VERSION "HINBNNNYYNNNYYNNNNNNNNNNNNYNNNYYYNNYNNNNNN/4//%%/4/'%**4NNN///"

NS_ :

BS_:

BU_: VirtualNMTMaster BMS_5_1 BMS_4_1 BMS_3_1 BMS_2_1 BMS_1_1 BMS_0_1 BMS_5_0 BMS_4_0 BMS_3_0 BMS_2_0 BMS_1_0 BMS_0_0 PVC IMU TMS TMU MC

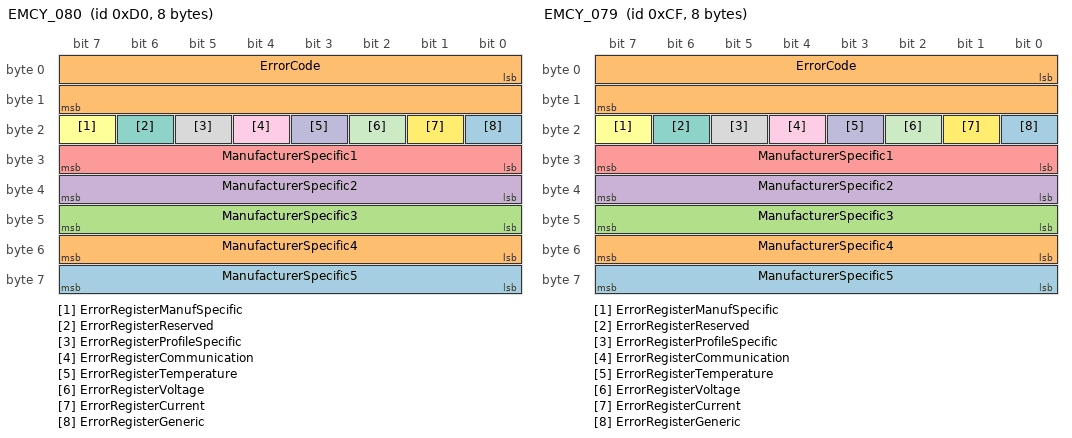
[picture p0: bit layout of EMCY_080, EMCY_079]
BO_ 208 EMCY_080: 8 Vector__XXX
 SG_ ManufacturerSpecific5 : 56|8@1+ (1,0) [0|0] "" Vector__XXX
 SG_ ManufacturerSpecific4 : 48|8@1+ (1,0) [0|0] "" Vector__XXX
 SG_ ManufacturerSpecific3 : 40|8@1+ (1,0) [0|0] "" Vector__XXX
 SG_ ManufacturerSpecific2 : 32|8@1+ (1,0) [0|0] "" Vector__XXX
 SG_ ManufacturerSpecific1 : 24|8@1+ (1,0) [0|0] "" Vector__XXX
 SG_ ErrorRegisterManufSpecific : 23|1@1+ (1,0) [0|0] "" Vector__XXX
 SG_ ErrorRegisterReserved : 22|1@1+ (1,0) [0|0] "" Vector__XXX
 SG_ ErrorRegisterProfileSpecific : 21|1@1+ (1,0) [0|0] "" Vector__XXX
 SG_ ErrorRegisterCommunication : 20|1@1+ (1,0) [0|0] "" Vector__XXX
 SG_ ErrorRegisterTemperature : 19|1@1+ (1,0) [0|0] "" Vector__XXX
 SG_ ErrorRegisterVoltage : 18|1@1+ (1,0) [0|0] "" Vector__XXX
 SG_ ErrorRegisterCurrent : 17|1@1+ (1,0) [0|0] "" Vector__XXX
 SG_ ErrorRegisterGeneric : 16|1@1+ (1,0) [0|0] "" Vector__XXX
 SG_ ErrorCode : 0|16@1+ (1,0) [0|0] "" Vector__XXX

BO_ 1871 HBGuard_079: 1 Vector__XXX
 SG_ Toggle : 7|1@1+ (1,0) [0|0] "" Vector__XXX
 SG_ State : 0|7@1+ (1,0) [0|0] "" Vector__XXX

BO_ 1487 SSDO_079: 8 Vector__XXX

BO_ 1615 CSDO_079: 8 Vector__XXX

BO_ 207 EMCY_079: 8 Vector__XXX
 SG_ ManufacturerSpecific5 : 56|8@1+ (1,0) [0|0] "" Vector__XXX
 SG_ ManufacturerSpecific4 : 48|8@1+ (1,0) [0|0] "" Vector__XXX
 SG_ ManufacturerSpecific3 : 40|8@1+ (1,0) [0|0] "" Vector__XXX
 SG_ ManufacturerSpecific2 : 32|8@1+ (1,0) [0|0] "" Vector__XXX
 SG_ ManufacturerSpecific1 : 24|8@1+ (1,0) [0|0] "" Vector__XXX
 SG_ ErrorRegisterManufSpecific : 23|1@1+ (1,0) [0|0] "" Vector__XXX
 SG_ ErrorRegisterReserved : 22|1@1+ (1,0) [0|0] "" Vector__XXX
 SG_ ErrorRegisterProfileSpecific : 21|1@1+ (1,0) [0|0] "" Vector__XXX
 SG_ ErrorRegisterCommunication : 20|1@1+ (1,0) [0|0] "" Vector__XXX
 SG_ ErrorRegisterTemperature : 19|1@1+ (1,0) [0|0] "" Vector__XXX
 SG_ ErrorRegisterVoltage : 18|1@1+ (1,0) [0|0] "" Vector__XXX
 SG_ ErrorRegisterCurrent : 17|1@1+ (1,0) [0|0] "" Vector__XXX
 SG_ ErrorRegisterGeneric : 16|1@1+ (1,0) [0|0] "" Vector__XXX
 SG_ ErrorCode : 0|16@1+ (1,0) [0|0] "" Vector__XXX

BO_ 1870 HBGuard_078: 1 Vector__XXX
 SG_ Toggle : 7|1@1+ (1,0) [0|0] "" Vector__XXX
 SG_ State : 0|7@1+ (1,0) [0|0] "" Vector__XXX

BO_ 1486 SSDO_078: 8 Vector__XXX

BO_ 1614 CSDO_078: 8 Vector__XXX

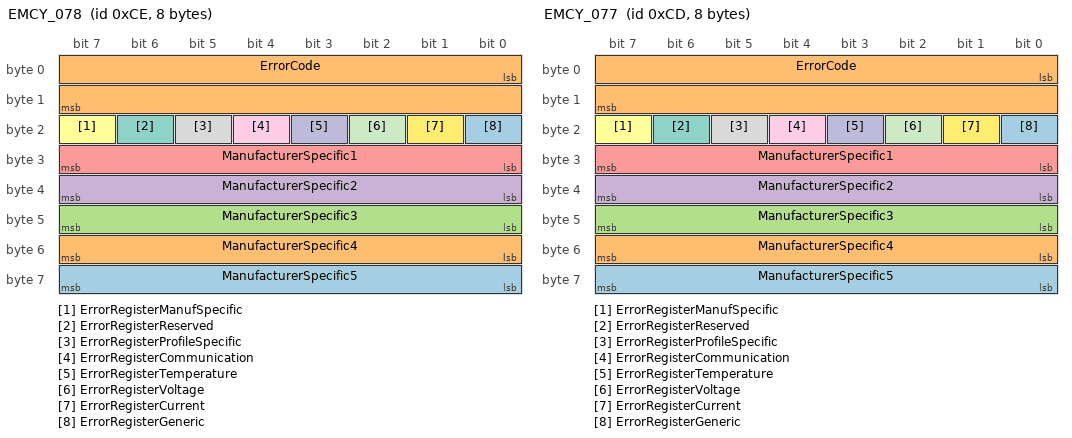
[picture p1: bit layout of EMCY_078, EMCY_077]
BO_ 206 EMCY_078: 8 Vector__XXX
 SG_ ManufacturerSpecific5 : 56|8@1+ (1,0) [0|0] "" Vector__XXX
 SG_ ManufacturerSpecific4 : 48|8@1+ (1,0) [0|0] "" Vector__XXX
 SG_ ManufacturerSpecific3 : 40|8@1+ (1,0) [0|0] "" Vector__XXX
 SG_ ManufacturerSpecific2 : 32|8@1+ (1,0) [0|0] "" Vector__XXX
 SG_ ManufacturerSpecific1 : 24|8@1+ (1,0) [0|0] "" Vector__XXX
 SG_ ErrorRegisterManufSpecific : 23|1@1+ (1,0) [0|0] "" Vector__XXX
 SG_ ErrorRegisterReserved : 22|1@1+ (1,0) [0|0] "" Vector__XXX
 SG_ ErrorRegisterProfileSpecific : 21|1@1+ (1,0) [0|0] "" Vector__XXX
 SG_ ErrorRegisterCommunication : 20|1@1+ (1,0) [0|0] "" Vector__XXX
 SG_ ErrorRegisterTemperature : 19|1@1+ (1,0) [0|0] "" Vector__XXX
 SG_ ErrorRegisterVoltage : 18|1@1+ (1,0) [0|0] "" Vector__XXX
 SG_ ErrorRegisterCurrent : 17|1@1+ (1,0) [0|0] "" Vector__XXX
 SG_ ErrorRegisterGeneric : 16|1@1+ (1,0) [0|0] "" Vector__XXX
 SG_ ErrorCode : 0|16@1+ (1,0) [0|0] "" Vector__XXX

BO_ 1869 HBGuard_077: 1 Vector__XXX
 SG_ Toggle : 7|1@1+ (1,0) [0|0] "" Vector__XXX
 SG_ State : 0|7@1+ (1,0) [0|0] "" Vector__XXX

BO_ 1485 SSDO_077: 8 Vector__XXX

BO_ 1613 CSDO_077: 8 Vector__XXX

BO_ 205 EMCY_077: 8 Vector__XXX
 SG_ ManufacturerSpecific5 : 56|8@1+ (1,0) [0|0] "" Vector__XXX
 SG_ ManufacturerSpecific4 : 48|8@1+ (1,0) [0|0] "" Vector__XXX
 SG_ ManufacturerSpecific3 : 40|8@1+ (1,0) [0|0] "" Vector__XXX
 SG_ ManufacturerSpecific2 : 32|8@1+ (1,0) [0|0] "" Vector__XXX
 SG_ ManufacturerSpecific1 : 24|8@1+ (1,0) [0|0] "" Vector__XXX
 SG_ ErrorRegisterManufSpecific : 23|1@1+ (1,0) [0|0] "" Vector__XXX
 SG_ ErrorRegisterReserved : 22|1@1+ (1,0) [0|0] "" Vector__XXX
 SG_ ErrorRegisterProfileSpecific : 21|1@1+ (1,0) [0|0] "" Vector__XXX
 SG_ ErrorRegisterCommunication : 20|1@1+ (1,0) [0|0] "" Vector__XXX
 SG_ ErrorRegisterTemperature : 19|1@1+ (1,0) [0|0] "" Vector__XXX
 SG_ ErrorRegisterVoltage : 18|1@1+ (1,0) [0|0] "" Vector__XXX
 SG_ ErrorRegisterCurrent : 17|1@1+ (1,0) [0|0] "" Vector__XXX
 SG_ ErrorRegisterGeneric : 16|1@1+ (1,0) [0|0] "" Vector__XXX
 SG_ ErrorCode : 0|16@1+ (1,0) [0|0] "" Vector__XXX

BO_ 1868 HBGuard_076: 1 Vector__XXX
 SG_ Toggle : 7|1@1+ (1,0) [0|0] "" Vector__XXX
 SG_ State : 0|7@1+ (1,0) [0|0] "" Vector__XXX

BO_ 1484 SSDO_076: 8 Vector__XXX

BO_ 1612 CSDO_076: 8 Vector__XXX

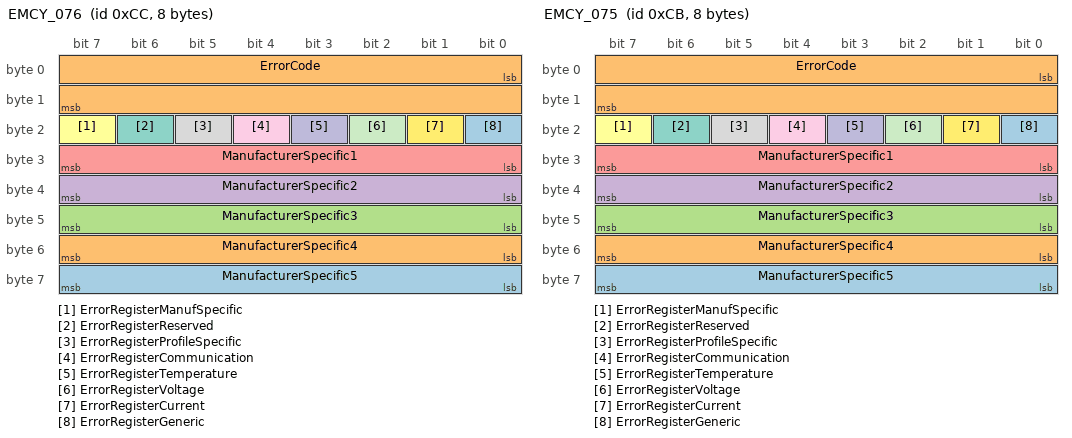
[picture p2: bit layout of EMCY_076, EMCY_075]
BO_ 204 EMCY_076: 8 Vector__XXX
 SG_ ManufacturerSpecific5 : 56|8@1+ (1,0) [0|0] "" Vector__XXX
 SG_ ManufacturerSpecific4 : 48|8@1+ (1,0) [0|0] "" Vector__XXX
 SG_ ManufacturerSpecific3 : 40|8@1+ (1,0) [0|0] "" Vector__XXX
 SG_ ManufacturerSpecific2 : 32|8@1+ (1,0) [0|0] "" Vector__XXX
 SG_ ManufacturerSpecific1 : 24|8@1+ (1,0) [0|0] "" Vector__XXX
 SG_ ErrorRegisterManufSpecific : 23|1@1+ (1,0) [0|0] "" Vector__XXX
 SG_ ErrorRegisterReserved : 22|1@1+ (1,0) [0|0] "" Vector__XXX
 SG_ ErrorRegisterProfileSpecific : 21|1@1+ (1,0) [0|0] "" Vector__XXX
 SG_ ErrorRegisterCommunication : 20|1@1+ (1,0) [0|0] "" Vector__XXX
 SG_ ErrorRegisterTemperature : 19|1@1+ (1,0) [0|0] "" Vector__XXX
 SG_ ErrorRegisterVoltage : 18|1@1+ (1,0) [0|0] "" Vector__XXX
 SG_ ErrorRegisterCurrent : 17|1@1+ (1,0) [0|0] "" Vector__XXX
 SG_ ErrorRegisterGeneric : 16|1@1+ (1,0) [0|0] "" Vector__XXX
 SG_ ErrorCode : 0|16@1+ (1,0) [0|0] "" Vector__XXX

BO_ 1867 HBGuard_075: 1 Vector__XXX
 SG_ Toggle : 7|1@1+ (1,0) [0|0] "" Vector__XXX
 SG_ State : 0|7@1+ (1,0) [0|0] "" Vector__XXX

BO_ 1483 SSDO_075: 8 Vector__XXX

BO_ 1611 CSDO_075: 8 Vector__XXX

BO_ 203 EMCY_075: 8 Vector__XXX
 SG_ ManufacturerSpecific5 : 56|8@1+ (1,0) [0|0] "" Vector__XXX
 SG_ ManufacturerSpecific4 : 48|8@1+ (1,0) [0|0] "" Vector__XXX
 SG_ ManufacturerSpecific3 : 40|8@1+ (1,0) [0|0] "" Vector__XXX
 SG_ ManufacturerSpecific2 : 32|8@1+ (1,0) [0|0] "" Vector__XXX
 SG_ ManufacturerSpecific1 : 24|8@1+ (1,0) [0|0] "" Vector__XXX
 SG_ ErrorRegisterManufSpecific : 23|1@1+ (1,0) [0|0] "" Vector__XXX
 SG_ ErrorRegisterReserved : 22|1@1+ (1,0) [0|0] "" Vector__XXX
 SG_ ErrorRegisterProfileSpecific : 21|1@1+ (1,0) [0|0] "" Vector__XXX
 SG_ ErrorRegisterCommunication : 20|1@1+ (1,0) [0|0] "" Vector__XXX
 SG_ ErrorRegisterTemperature : 19|1@1+ (1,0) [0|0] "" Vector__XXX
 SG_ ErrorRegisterVoltage : 18|1@1+ (1,0) [0|0] "" Vector__XXX
 SG_ ErrorRegisterCurrent : 17|1@1+ (1,0) [0|0] "" Vector__XXX
 SG_ ErrorRegisterGeneric : 16|1@1+ (1,0) [0|0] "" Vector__XXX
 SG_ ErrorCode : 0|16@1+ (1,0) [0|0] "" Vector__XXX

BO_ 1866 HBGuard_074: 1 Vector__XXX
 SG_ Toggle : 7|1@1+ (1,0) [0|0] "" Vector__XXX
 SG_ State : 0|7@1+ (1,0) [0|0] "" Vector__XXX

BO_ 1482 SSDO_074: 8 Vector__XXX

BO_ 1610 CSDO_074: 8 Vector__XXX

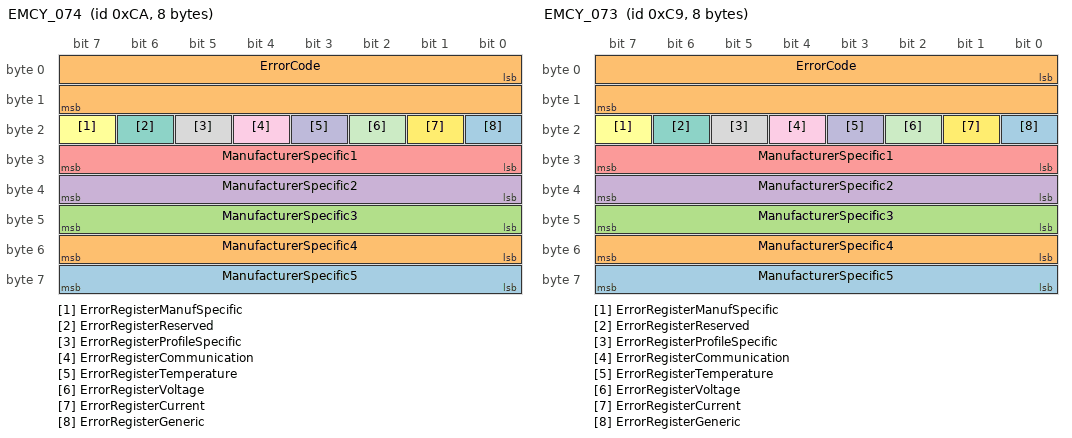
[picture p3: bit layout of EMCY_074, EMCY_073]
BO_ 202 EMCY_074: 8 Vector__XXX
 SG_ ManufacturerSpecific5 : 56|8@1+ (1,0) [0|0] "" Vector__XXX
 SG_ ManufacturerSpecific4 : 48|8@1+ (1,0) [0|0] "" Vector__XXX
 SG_ ManufacturerSpecific3 : 40|8@1+ (1,0) [0|0] "" Vector__XXX
 SG_ ManufacturerSpecific2 : 32|8@1+ (1,0) [0|0] "" Vector__XXX
 SG_ ManufacturerSpecific1 : 24|8@1+ (1,0) [0|0] "" Vector__XXX
 SG_ ErrorRegisterManufSpecific : 23|1@1+ (1,0) [0|0] "" Vector__XXX
 SG_ ErrorRegisterReserved : 22|1@1+ (1,0) [0|0] "" Vector__XXX
 SG_ ErrorRegisterProfileSpecific : 21|1@1+ (1,0) [0|0] "" Vector__XXX
 SG_ ErrorRegisterCommunication : 20|1@1+ (1,0) [0|0] "" Vector__XXX
 SG_ ErrorRegisterTemperature : 19|1@1+ (1,0) [0|0] "" Vector__XXX
 SG_ ErrorRegisterVoltage : 18|1@1+ (1,0) [0|0] "" Vector__XXX
 SG_ ErrorRegisterCurrent : 17|1@1+ (1,0) [0|0] "" Vector__XXX
 SG_ ErrorRegisterGeneric : 16|1@1+ (1,0) [0|0] "" Vector__XXX
 SG_ ErrorCode : 0|16@1+ (1,0) [0|0] "" Vector__XXX

BO_ 1865 HBGuard_073: 1 Vector__XXX
 SG_ Toggle : 7|1@1+ (1,0) [0|0] "" Vector__XXX
 SG_ State : 0|7@1+ (1,0) [0|0] "" Vector__XXX

BO_ 1481 SSDO_073: 8 Vector__XXX

BO_ 1609 CSDO_073: 8 Vector__XXX

BO_ 201 EMCY_073: 8 Vector__XXX
 SG_ ManufacturerSpecific5 : 56|8@1+ (1,0) [0|0] "" Vector__XXX
 SG_ ManufacturerSpecific4 : 48|8@1+ (1,0) [0|0] "" Vector__XXX
 SG_ ManufacturerSpecific3 : 40|8@1+ (1,0) [0|0] "" Vector__XXX
 SG_ ManufacturerSpecific2 : 32|8@1+ (1,0) [0|0] "" Vector__XXX
 SG_ ManufacturerSpecific1 : 24|8@1+ (1,0) [0|0] "" Vector__XXX
 SG_ ErrorRegisterManufSpecific : 23|1@1+ (1,0) [0|0] "" Vector__XXX
 SG_ ErrorRegisterReserved : 22|1@1+ (1,0) [0|0] "" Vector__XXX
 SG_ ErrorRegisterProfileSpecific : 21|1@1+ (1,0) [0|0] "" Vector__XXX
 SG_ ErrorRegisterCommunication : 20|1@1+ (1,0) [0|0] "" Vector__XXX
 SG_ ErrorRegisterTemperature : 19|1@1+ (1,0) [0|0] "" Vector__XXX
 SG_ ErrorRegisterVoltage : 18|1@1+ (1,0) [0|0] "" Vector__XXX
 SG_ ErrorRegisterCurrent : 17|1@1+ (1,0) [0|0] "" Vector__XXX
 SG_ ErrorRegisterGeneric : 16|1@1+ (1,0) [0|0] "" Vector__XXX
 SG_ ErrorCode : 0|16@1+ (1,0) [0|0] "" Vector__XXX

BO_ 1864 HBGuard_072: 1 Vector__XXX
 SG_ Toggle : 7|1@1+ (1,0) [0|0] "" Vector__XXX
 SG_ State : 0|7@1+ (1,0) [0|0] "" Vector__XXX

BO_ 1480 SSDO_072: 8 Vector__XXX

BO_ 1608 CSDO_072: 8 Vector__XXX

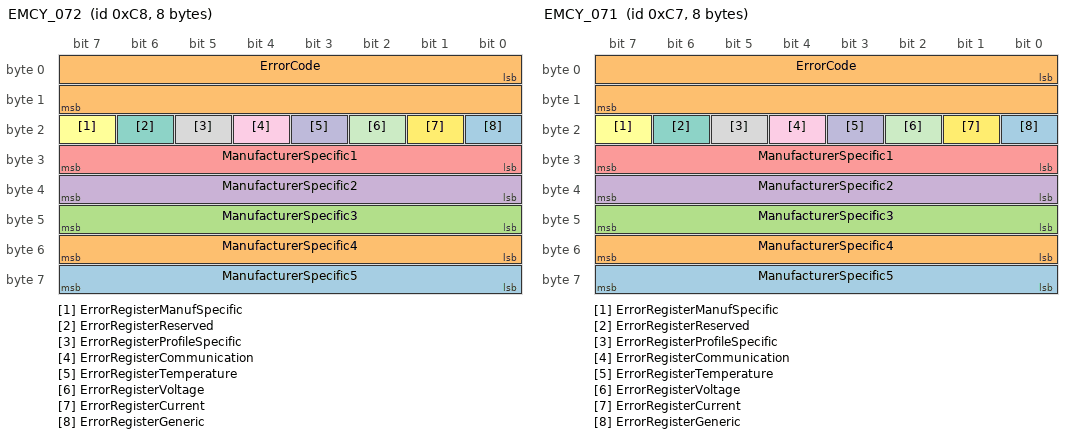
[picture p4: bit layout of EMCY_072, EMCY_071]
BO_ 200 EMCY_072: 8 Vector__XXX
 SG_ ManufacturerSpecific5 : 56|8@1+ (1,0) [0|0] "" Vector__XXX
 SG_ ManufacturerSpecific4 : 48|8@1+ (1,0) [0|0] "" Vector__XXX
 SG_ ManufacturerSpecific3 : 40|8@1+ (1,0) [0|0] "" Vector__XXX
 SG_ ManufacturerSpecific2 : 32|8@1+ (1,0) [0|0] "" Vector__XXX
 SG_ ManufacturerSpecific1 : 24|8@1+ (1,0) [0|0] "" Vector__XXX
 SG_ ErrorRegisterManufSpecific : 23|1@1+ (1,0) [0|0] "" Vector__XXX
 SG_ ErrorRegisterReserved : 22|1@1+ (1,0) [0|0] "" Vector__XXX
 SG_ ErrorRegisterProfileSpecific : 21|1@1+ (1,0) [0|0] "" Vector__XXX
 SG_ ErrorRegisterCommunication : 20|1@1+ (1,0) [0|0] "" Vector__XXX
 SG_ ErrorRegisterTemperature : 19|1@1+ (1,0) [0|0] "" Vector__XXX
 SG_ ErrorRegisterVoltage : 18|1@1+ (1,0) [0|0] "" Vector__XXX
 SG_ ErrorRegisterCurrent : 17|1@1+ (1,0) [0|0] "" Vector__XXX
 SG_ ErrorRegisterGeneric : 16|1@1+ (1,0) [0|0] "" Vector__XXX
 SG_ ErrorCode : 0|16@1+ (1,0) [0|0] "" Vector__XXX

BO_ 1863 HBGuard_071: 1 Vector__XXX
 SG_ Toggle : 7|1@1+ (1,0) [0|0] "" Vector__XXX
 SG_ State : 0|7@1+ (1,0) [0|0] "" Vector__XXX

BO_ 1479 SSDO_071: 8 Vector__XXX

BO_ 1607 CSDO_071: 8 Vector__XXX

BO_ 199 EMCY_071: 8 Vector__XXX
 SG_ ManufacturerSpecific5 : 56|8@1+ (1,0) [0|0] "" Vector__XXX
 SG_ ManufacturerSpecific4 : 48|8@1+ (1,0) [0|0] "" Vector__XXX
 SG_ ManufacturerSpecific3 : 40|8@1+ (1,0) [0|0] "" Vector__XXX
 SG_ ManufacturerSpecific2 : 32|8@1+ (1,0) [0|0] "" Vector__XXX
 SG_ ManufacturerSpecific1 : 24|8@1+ (1,0) [0|0] "" Vector__XXX
 SG_ ErrorRegisterManufSpecific : 23|1@1+ (1,0) [0|0] "" Vector__XXX
 SG_ ErrorRegisterReserved : 22|1@1+ (1,0) [0|0] "" Vector__XXX
 SG_ ErrorRegisterProfileSpecific : 21|1@1+ (1,0) [0|0] "" Vector__XXX
 SG_ ErrorRegisterCommunication : 20|1@1+ (1,0) [0|0] "" Vector__XXX
 SG_ ErrorRegisterTemperature : 19|1@1+ (1,0) [0|0] "" Vector__XXX
 SG_ ErrorRegisterVoltage : 18|1@1+ (1,0) [0|0] "" Vector__XXX
 SG_ ErrorRegisterCurrent : 17|1@1+ (1,0) [0|0] "" Vector__XXX
 SG_ ErrorRegisterGeneric : 16|1@1+ (1,0) [0|0] "" Vector__XXX
 SG_ ErrorCode : 0|16@1+ (1,0) [0|0] "" Vector__XXX

BO_ 1862 HBGuard_070: 1 Vector__XXX
 SG_ Toggle : 7|1@1+ (1,0) [0|0] "" Vector__XXX
 SG_ State : 0|7@1+ (1,0) [0|0] "" Vector__XXX

BO_ 1478 SSDO_070: 8 Vector__XXX

BO_ 1606 CSDO_070: 8 Vector__XXX

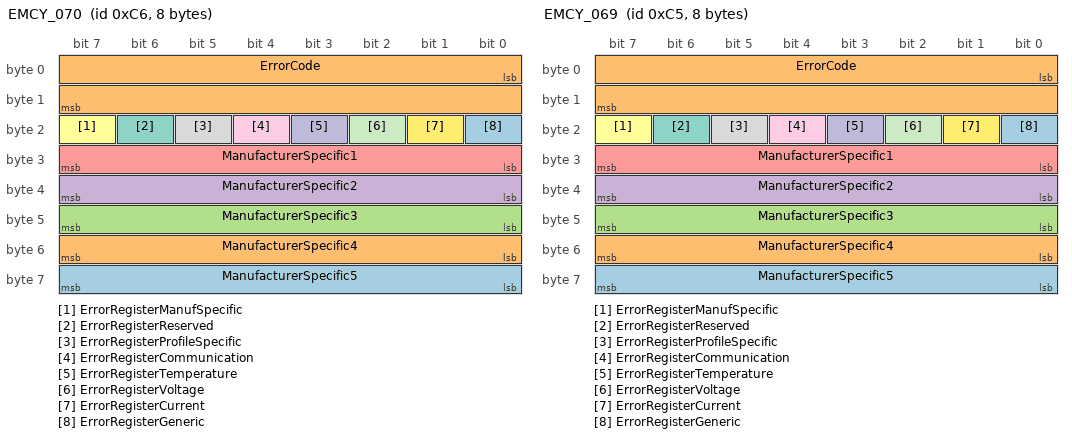
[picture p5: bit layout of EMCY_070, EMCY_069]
BO_ 198 EMCY_070: 8 Vector__XXX
 SG_ ManufacturerSpecific5 : 56|8@1+ (1,0) [0|0] "" Vector__XXX
 SG_ ManufacturerSpecific4 : 48|8@1+ (1,0) [0|0] "" Vector__XXX
 SG_ ManufacturerSpecific3 : 40|8@1+ (1,0) [0|0] "" Vector__XXX
 SG_ ManufacturerSpecific2 : 32|8@1+ (1,0) [0|0] "" Vector__XXX
 SG_ ManufacturerSpecific1 : 24|8@1+ (1,0) [0|0] "" Vector__XXX
 SG_ ErrorRegisterManufSpecific : 23|1@1+ (1,0) [0|0] "" Vector__XXX
 SG_ ErrorRegisterReserved : 22|1@1+ (1,0) [0|0] "" Vector__XXX
 SG_ ErrorRegisterProfileSpecific : 21|1@1+ (1,0) [0|0] "" Vector__XXX
 SG_ ErrorRegisterCommunication : 20|1@1+ (1,0) [0|0] "" Vector__XXX
 SG_ ErrorRegisterTemperature : 19|1@1+ (1,0) [0|0] "" Vector__XXX
 SG_ ErrorRegisterVoltage : 18|1@1+ (1,0) [0|0] "" Vector__XXX
 SG_ ErrorRegisterCurrent : 17|1@1+ (1,0) [0|0] "" Vector__XXX
 SG_ ErrorRegisterGeneric : 16|1@1+ (1,0) [0|0] "" Vector__XXX
 SG_ ErrorCode : 0|16@1+ (1,0) [0|0] "" Vector__XXX

BO_ 1861 HBGuard_069: 1 Vector__XXX
 SG_ Toggle : 7|1@1+ (1,0) [0|0] "" Vector__XXX
 SG_ State : 0|7@1+ (1,0) [0|0] "" Vector__XXX

BO_ 1477 SSDO_069: 8 Vector__XXX

BO_ 1605 CSDO_069: 8 Vector__XXX

BO_ 197 EMCY_069: 8 Vector__XXX
 SG_ ManufacturerSpecific5 : 56|8@1+ (1,0) [0|0] "" Vector__XXX
 SG_ ManufacturerSpecific4 : 48|8@1+ (1,0) [0|0] "" Vector__XXX
 SG_ ManufacturerSpecific3 : 40|8@1+ (1,0) [0|0] "" Vector__XXX
 SG_ ManufacturerSpecific2 : 32|8@1+ (1,0) [0|0] "" Vector__XXX
 SG_ ManufacturerSpecific1 : 24|8@1+ (1,0) [0|0] "" Vector__XXX
 SG_ ErrorRegisterManufSpecific : 23|1@1+ (1,0) [0|0] "" Vector__XXX
 SG_ ErrorRegisterReserved : 22|1@1+ (1,0) [0|0] "" Vector__XXX
 SG_ ErrorRegisterProfileSpecific : 21|1@1+ (1,0) [0|0] "" Vector__XXX
 SG_ ErrorRegisterCommunication : 20|1@1+ (1,0) [0|0] "" Vector__XXX
 SG_ ErrorRegisterTemperature : 19|1@1+ (1,0) [0|0] "" Vector__XXX
 SG_ ErrorRegisterVoltage : 18|1@1+ (1,0) [0|0] "" Vector__XXX
 SG_ ErrorRegisterCurrent : 17|1@1+ (1,0) [0|0] "" Vector__XXX
 SG_ ErrorRegisterGeneric : 16|1@1+ (1,0) [0|0] "" Vector__XXX
 SG_ ErrorCode : 0|16@1+ (1,0) [0|0] "" Vector__XXX

BO_ 1860 HBGuard_068: 1 Vector__XXX
 SG_ Toggle : 7|1@1+ (1,0) [0|0] "" Vector__XXX
 SG_ State : 0|7@1+ (1,0) [0|0] "" Vector__XXX

BO_ 1476 SSDO_068: 8 Vector__XXX

BO_ 1604 CSDO_068: 8 Vector__XXX

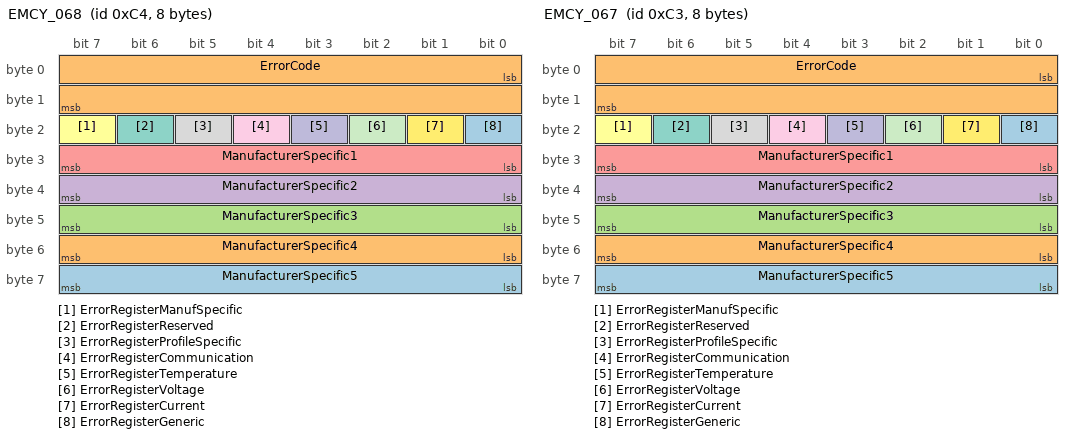
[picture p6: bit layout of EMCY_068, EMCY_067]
BO_ 196 EMCY_068: 8 Vector__XXX
 SG_ ManufacturerSpecific5 : 56|8@1+ (1,0) [0|0] "" Vector__XXX
 SG_ ManufacturerSpecific4 : 48|8@1+ (1,0) [0|0] "" Vector__XXX
 SG_ ManufacturerSpecific3 : 40|8@1+ (1,0) [0|0] "" Vector__XXX
 SG_ ManufacturerSpecific2 : 32|8@1+ (1,0) [0|0] "" Vector__XXX
 SG_ ManufacturerSpecific1 : 24|8@1+ (1,0) [0|0] "" Vector__XXX
 SG_ ErrorRegisterManufSpecific : 23|1@1+ (1,0) [0|0] "" Vector__XXX
 SG_ ErrorRegisterReserved : 22|1@1+ (1,0) [0|0] "" Vector__XXX
 SG_ ErrorRegisterProfileSpecific : 21|1@1+ (1,0) [0|0] "" Vector__XXX
 SG_ ErrorRegisterCommunication : 20|1@1+ (1,0) [0|0] "" Vector__XXX
 SG_ ErrorRegisterTemperature : 19|1@1+ (1,0) [0|0] "" Vector__XXX
 SG_ ErrorRegisterVoltage : 18|1@1+ (1,0) [0|0] "" Vector__XXX
 SG_ ErrorRegisterCurrent : 17|1@1+ (1,0) [0|0] "" Vector__XXX
 SG_ ErrorRegisterGeneric : 16|1@1+ (1,0) [0|0] "" Vector__XXX
 SG_ ErrorCode : 0|16@1+ (1,0) [0|0] "" Vector__XXX

BO_ 1859 HBGuard_067: 1 Vector__XXX
 SG_ Toggle : 7|1@1+ (1,0) [0|0] "" Vector__XXX
 SG_ State : 0|7@1+ (1,0) [0|0] "" Vector__XXX

BO_ 1475 SSDO_067: 8 Vector__XXX

BO_ 1603 CSDO_067: 8 Vector__XXX

BO_ 195 EMCY_067: 8 Vector__XXX
 SG_ ManufacturerSpecific5 : 56|8@1+ (1,0) [0|0] "" Vector__XXX
 SG_ ManufacturerSpecific4 : 48|8@1+ (1,0) [0|0] "" Vector__XXX
 SG_ ManufacturerSpecific3 : 40|8@1+ (1,0) [0|0] "" Vector__XXX
 SG_ ManufacturerSpecific2 : 32|8@1+ (1,0) [0|0] "" Vector__XXX
 SG_ ManufacturerSpecific1 : 24|8@1+ (1,0) [0|0] "" Vector__XXX
 SG_ ErrorRegisterManufSpecific : 23|1@1+ (1,0) [0|0] "" Vector__XXX
 SG_ ErrorRegisterReserved : 22|1@1+ (1,0) [0|0] "" Vector__XXX
 SG_ ErrorRegisterProfileSpecific : 21|1@1+ (1,0) [0|0] "" Vector__XXX
 SG_ ErrorRegisterCommunication : 20|1@1+ (1,0) [0|0] "" Vector__XXX
 SG_ ErrorRegisterTemperature : 19|1@1+ (1,0) [0|0] "" Vector__XXX
 SG_ ErrorRegisterVoltage : 18|1@1+ (1,0) [0|0] "" Vector__XXX
 SG_ ErrorRegisterCurrent : 17|1@1+ (1,0) [0|0] "" Vector__XXX
 SG_ ErrorRegisterGeneric : 16|1@1+ (1,0) [0|0] "" Vector__XXX
 SG_ ErrorCode : 0|16@1+ (1,0) [0|0] "" Vector__XXX

BO_ 1858 HBGuard_066: 1 Vector__XXX
 SG_ Toggle : 7|1@1+ (1,0) [0|0] "" Vector__XXX
 SG_ State : 0|7@1+ (1,0) [0|0] "" Vector__XXX

BO_ 1474 SSDO_066: 8 Vector__XXX

BO_ 1602 CSDO_066: 8 Vector__XXX

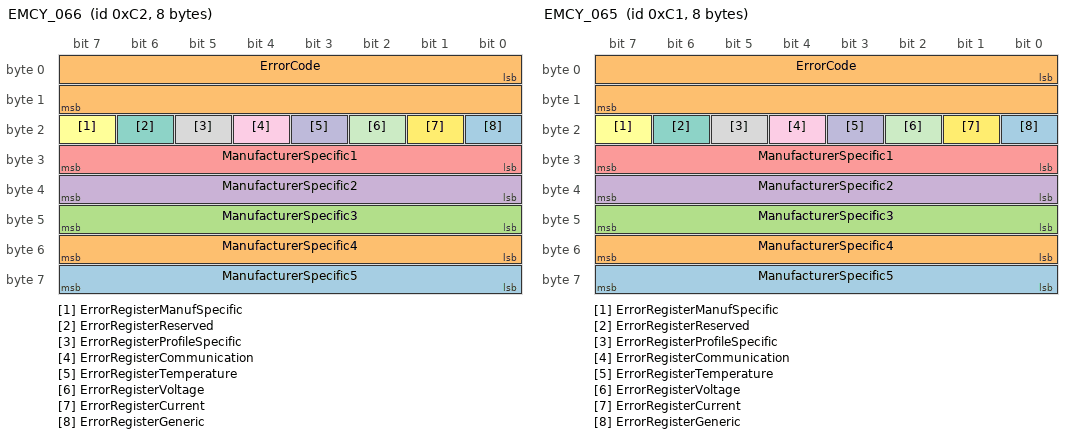
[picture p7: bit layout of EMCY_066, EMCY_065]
BO_ 194 EMCY_066: 8 Vector__XXX
 SG_ ManufacturerSpecific5 : 56|8@1+ (1,0) [0|0] "" Vector__XXX
 SG_ ManufacturerSpecific4 : 48|8@1+ (1,0) [0|0] "" Vector__XXX
 SG_ ManufacturerSpecific3 : 40|8@1+ (1,0) [0|0] "" Vector__XXX
 SG_ ManufacturerSpecific2 : 32|8@1+ (1,0) [0|0] "" Vector__XXX
 SG_ ManufacturerSpecific1 : 24|8@1+ (1,0) [0|0] "" Vector__XXX
 SG_ ErrorRegisterManufSpecific : 23|1@1+ (1,0) [0|0] "" Vector__XXX
 SG_ ErrorRegisterReserved : 22|1@1+ (1,0) [0|0] "" Vector__XXX
 SG_ ErrorRegisterProfileSpecific : 21|1@1+ (1,0) [0|0] "" Vector__XXX
 SG_ ErrorRegisterCommunication : 20|1@1+ (1,0) [0|0] "" Vector__XXX
 SG_ ErrorRegisterTemperature : 19|1@1+ (1,0) [0|0] "" Vector__XXX
 SG_ ErrorRegisterVoltage : 18|1@1+ (1,0) [0|0] "" Vector__XXX
 SG_ ErrorRegisterCurrent : 17|1@1+ (1,0) [0|0] "" Vector__XXX
 SG_ ErrorRegisterGeneric : 16|1@1+ (1,0) [0|0] "" Vector__XXX
 SG_ ErrorCode : 0|16@1+ (1,0) [0|0] "" Vector__XXX

BO_ 1857 HBGuard_065: 1 Vector__XXX
 SG_ Toggle : 7|1@1+ (1,0) [0|0] "" Vector__XXX
 SG_ State : 0|7@1+ (1,0) [0|0] "" Vector__XXX

BO_ 1473 SSDO_065: 8 Vector__XXX

BO_ 1601 CSDO_065: 8 Vector__XXX

BO_ 193 EMCY_065: 8 Vector__XXX
 SG_ ManufacturerSpecific5 : 56|8@1+ (1,0) [0|0] "" Vector__XXX
 SG_ ManufacturerSpecific4 : 48|8@1+ (1,0) [0|0] "" Vector__XXX
 SG_ ManufacturerSpecific3 : 40|8@1+ (1,0) [0|0] "" Vector__XXX
 SG_ ManufacturerSpecific2 : 32|8@1+ (1,0) [0|0] "" Vector__XXX
 SG_ ManufacturerSpecific1 : 24|8@1+ (1,0) [0|0] "" Vector__XXX
 SG_ ErrorRegisterManufSpecific : 23|1@1+ (1,0) [0|0] "" Vector__XXX
 SG_ ErrorRegisterReserved : 22|1@1+ (1,0) [0|0] "" Vector__XXX
 SG_ ErrorRegisterProfileSpecific : 21|1@1+ (1,0) [0|0] "" Vector__XXX
 SG_ ErrorRegisterCommunication : 20|1@1+ (1,0) [0|0] "" Vector__XXX
 SG_ ErrorRegisterTemperature : 19|1@1+ (1,0) [0|0] "" Vector__XXX
 SG_ ErrorRegisterVoltage : 18|1@1+ (1,0) [0|0] "" Vector__XXX
 SG_ ErrorRegisterCurrent : 17|1@1+ (1,0) [0|0] "" Vector__XXX
 SG_ ErrorRegisterGeneric : 16|1@1+ (1,0) [0|0] "" Vector__XXX
 SG_ ErrorCode : 0|16@1+ (1,0) [0|0] "" Vector__XXX

BO_ 1856 HBGuard_064: 1 Vector__XXX
 SG_ Toggle : 7|1@1+ (1,0) [0|0] "" Vector__XXX
 SG_ State : 0|7@1+ (1,0) [0|0] "" Vector__XXX

BO_ 1472 SSDO_064: 8 Vector__XXX

BO_ 1600 CSDO_064: 8 Vector__XXX

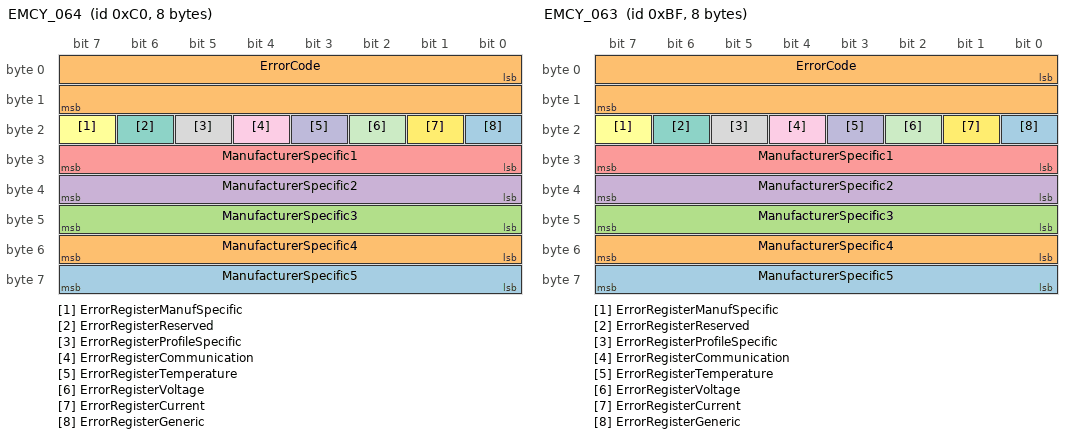
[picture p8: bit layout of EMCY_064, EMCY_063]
BO_ 192 EMCY_064: 8 Vector__XXX
 SG_ ManufacturerSpecific5 : 56|8@1+ (1,0) [0|0] "" Vector__XXX
 SG_ ManufacturerSpecific4 : 48|8@1+ (1,0) [0|0] "" Vector__XXX
 SG_ ManufacturerSpecific3 : 40|8@1+ (1,0) [0|0] "" Vector__XXX
 SG_ ManufacturerSpecific2 : 32|8@1+ (1,0) [0|0] "" Vector__XXX
 SG_ ManufacturerSpecific1 : 24|8@1+ (1,0) [0|0] "" Vector__XXX
 SG_ ErrorRegisterManufSpecific : 23|1@1+ (1,0) [0|0] "" Vector__XXX
 SG_ ErrorRegisterReserved : 22|1@1+ (1,0) [0|0] "" Vector__XXX
 SG_ ErrorRegisterProfileSpecific : 21|1@1+ (1,0) [0|0] "" Vector__XXX
 SG_ ErrorRegisterCommunication : 20|1@1+ (1,0) [0|0] "" Vector__XXX
 SG_ ErrorRegisterTemperature : 19|1@1+ (1,0) [0|0] "" Vector__XXX
 SG_ ErrorRegisterVoltage : 18|1@1+ (1,0) [0|0] "" Vector__XXX
 SG_ ErrorRegisterCurrent : 17|1@1+ (1,0) [0|0] "" Vector__XXX
 SG_ ErrorRegisterGeneric : 16|1@1+ (1,0) [0|0] "" Vector__XXX
 SG_ ErrorCode : 0|16@1+ (1,0) [0|0] "" Vector__XXX

BO_ 1855 HBGuard_063: 1 Vector__XXX
 SG_ Toggle : 7|1@1+ (1,0) [0|0] "" Vector__XXX
 SG_ State : 0|7@1+ (1,0) [0|0] "" Vector__XXX

BO_ 1471 SSDO_063: 8 Vector__XXX

BO_ 1599 CSDO_063: 8 Vector__XXX

BO_ 191 EMCY_063: 8 Vector__XXX
 SG_ ManufacturerSpecific5 : 56|8@1+ (1,0) [0|0] "" Vector__XXX
 SG_ ManufacturerSpecific4 : 48|8@1+ (1,0) [0|0] "" Vector__XXX
 SG_ ManufacturerSpecific3 : 40|8@1+ (1,0) [0|0] "" Vector__XXX
 SG_ ManufacturerSpecific2 : 32|8@1+ (1,0) [0|0] "" Vector__XXX
 SG_ ManufacturerSpecific1 : 24|8@1+ (1,0) [0|0] "" Vector__XXX
 SG_ ErrorRegisterManufSpecific : 23|1@1+ (1,0) [0|0] "" Vector__XXX
 SG_ ErrorRegisterReserved : 22|1@1+ (1,0) [0|0] "" Vector__XXX
 SG_ ErrorRegisterProfileSpecific : 21|1@1+ (1,0) [0|0] "" Vector__XXX
 SG_ ErrorRegisterCommunication : 20|1@1+ (1,0) [0|0] "" Vector__XXX
 SG_ ErrorRegisterTemperature : 19|1@1+ (1,0) [0|0] "" Vector__XXX
 SG_ ErrorRegisterVoltage : 18|1@1+ (1,0) [0|0] "" Vector__XXX
 SG_ ErrorRegisterCurrent : 17|1@1+ (1,0) [0|0] "" Vector__XXX
 SG_ ErrorRegisterGeneric : 16|1@1+ (1,0) [0|0] "" Vector__XXX
 SG_ ErrorCode : 0|16@1+ (1,0) [0|0] "" Vector__XXX

BO_ 1854 HBGuard_062: 1 Vector__XXX
 SG_ Toggle : 7|1@1+ (1,0) [0|0] "" Vector__XXX
 SG_ State : 0|7@1+ (1,0) [0|0] "" Vector__XXX

BO_ 1470 SSDO_062: 8 Vector__XXX

BO_ 1598 CSDO_062: 8 Vector__XXX

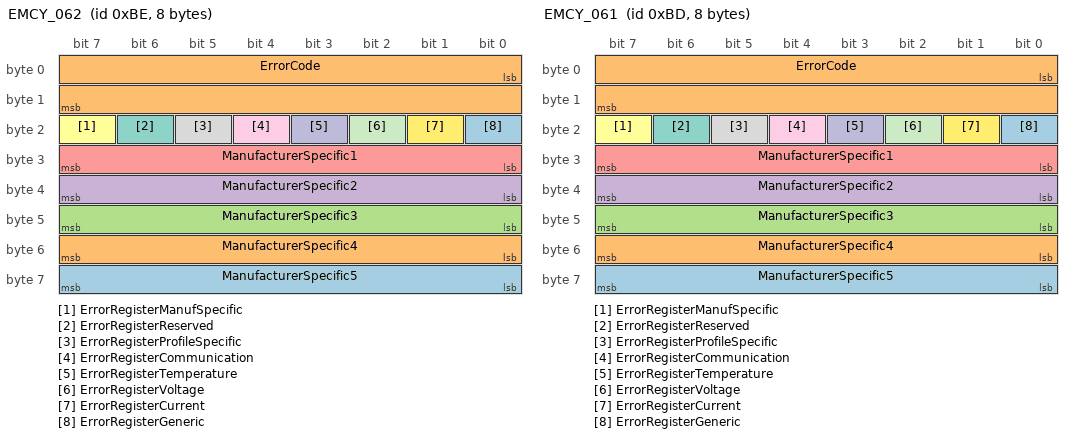
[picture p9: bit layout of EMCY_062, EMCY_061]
BO_ 190 EMCY_062: 8 Vector__XXX
 SG_ ManufacturerSpecific5 : 56|8@1+ (1,0) [0|0] "" Vector__XXX
 SG_ ManufacturerSpecific4 : 48|8@1+ (1,0) [0|0] "" Vector__XXX
 SG_ ManufacturerSpecific3 : 40|8@1+ (1,0) [0|0] "" Vector__XXX
 SG_ ManufacturerSpecific2 : 32|8@1+ (1,0) [0|0] "" Vector__XXX
 SG_ ManufacturerSpecific1 : 24|8@1+ (1,0) [0|0] "" Vector__XXX
 SG_ ErrorRegisterManufSpecific : 23|1@1+ (1,0) [0|0] "" Vector__XXX
 SG_ ErrorRegisterReserved : 22|1@1+ (1,0) [0|0] "" Vector__XXX
 SG_ ErrorRegisterProfileSpecific : 21|1@1+ (1,0) [0|0] "" Vector__XXX
 SG_ ErrorRegisterCommunication : 20|1@1+ (1,0) [0|0] "" Vector__XXX
 SG_ ErrorRegisterTemperature : 19|1@1+ (1,0) [0|0] "" Vector__XXX
 SG_ ErrorRegisterVoltage : 18|1@1+ (1,0) [0|0] "" Vector__XXX
 SG_ ErrorRegisterCurrent : 17|1@1+ (1,0) [0|0] "" Vector__XXX
 SG_ ErrorRegisterGeneric : 16|1@1+ (1,0) [0|0] "" Vector__XXX
 SG_ ErrorCode : 0|16@1+ (1,0) [0|0] "" Vector__XXX

BO_ 1853 HBGuard_061: 1 Vector__XXX
 SG_ Toggle : 7|1@1+ (1,0) [0|0] "" Vector__XXX
 SG_ State : 0|7@1+ (1,0) [0|0] "" Vector__XXX

BO_ 1469 SSDO_061: 8 Vector__XXX

BO_ 1597 CSDO_061: 8 Vector__XXX

BO_ 189 EMCY_061: 8 Vector__XXX
 SG_ ManufacturerSpecific5 : 56|8@1+ (1,0) [0|0] "" Vector__XXX
 SG_ ManufacturerSpecific4 : 48|8@1+ (1,0) [0|0] "" Vector__XXX
 SG_ ManufacturerSpecific3 : 40|8@1+ (1,0) [0|0] "" Vector__XXX
 SG_ ManufacturerSpecific2 : 32|8@1+ (1,0) [0|0] "" Vector__XXX
 SG_ ManufacturerSpecific1 : 24|8@1+ (1,0) [0|0] "" Vector__XXX
 SG_ ErrorRegisterManufSpecific : 23|1@1+ (1,0) [0|0] "" Vector__XXX
 SG_ ErrorRegisterReserved : 22|1@1+ (1,0) [0|0] "" Vector__XXX
 SG_ ErrorRegisterProfileSpecific : 21|1@1+ (1,0) [0|0] "" Vector__XXX
 SG_ ErrorRegisterCommunication : 20|1@1+ (1,0) [0|0] "" Vector__XXX
 SG_ ErrorRegisterTemperature : 19|1@1+ (1,0) [0|0] "" Vector__XXX
 SG_ ErrorRegisterVoltage : 18|1@1+ (1,0) [0|0] "" Vector__XXX
 SG_ ErrorRegisterCurrent : 17|1@1+ (1,0) [0|0] "" Vector__XXX
 SG_ ErrorRegisterGeneric : 16|1@1+ (1,0) [0|0] "" Vector__XXX
 SG_ ErrorCode : 0|16@1+ (1,0) [0|0] "" Vector__XXX

BO_ 1852 HBGuard_060: 1 Vector__XXX
 SG_ Toggle : 7|1@1+ (1,0) [0|0] "" Vector__XXX
 SG_ State : 0|7@1+ (1,0) [0|0] "" Vector__XXX

BO_ 1468 SSDO_060: 8 Vector__XXX

BO_ 1596 CSDO_060: 8 Vector__XXX

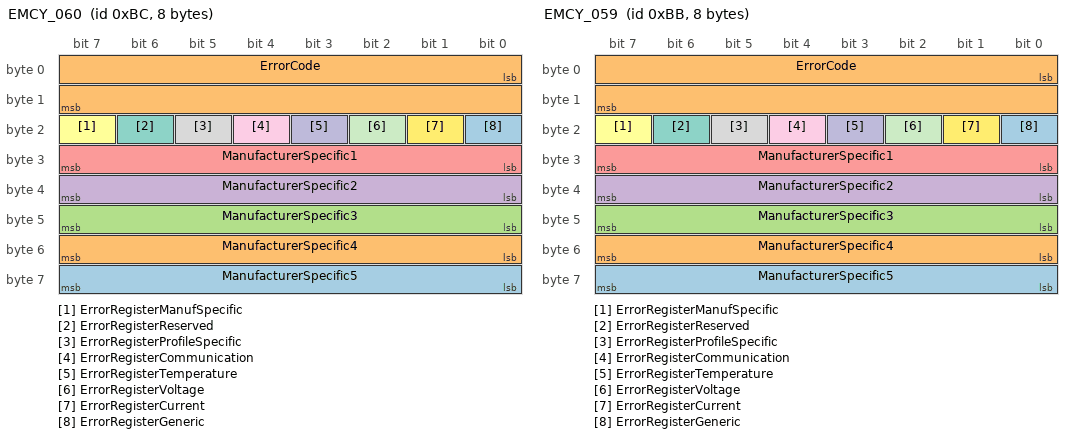
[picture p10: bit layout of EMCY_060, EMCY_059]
BO_ 188 EMCY_060: 8 Vector__XXX
 SG_ ManufacturerSpecific5 : 56|8@1+ (1,0) [0|0] "" Vector__XXX
 SG_ ManufacturerSpecific4 : 48|8@1+ (1,0) [0|0] "" Vector__XXX
 SG_ ManufacturerSpecific3 : 40|8@1+ (1,0) [0|0] "" Vector__XXX
 SG_ ManufacturerSpecific2 : 32|8@1+ (1,0) [0|0] "" Vector__XXX
 SG_ ManufacturerSpecific1 : 24|8@1+ (1,0) [0|0] "" Vector__XXX
 SG_ ErrorRegisterManufSpecific : 23|1@1+ (1,0) [0|0] "" Vector__XXX
 SG_ ErrorRegisterReserved : 22|1@1+ (1,0) [0|0] "" Vector__XXX
 SG_ ErrorRegisterProfileSpecific : 21|1@1+ (1,0) [0|0] "" Vector__XXX
 SG_ ErrorRegisterCommunication : 20|1@1+ (1,0) [0|0] "" Vector__XXX
 SG_ ErrorRegisterTemperature : 19|1@1+ (1,0) [0|0] "" Vector__XXX
 SG_ ErrorRegisterVoltage : 18|1@1+ (1,0) [0|0] "" Vector__XXX
 SG_ ErrorRegisterCurrent : 17|1@1+ (1,0) [0|0] "" Vector__XXX
 SG_ ErrorRegisterGeneric : 16|1@1+ (1,0) [0|0] "" Vector__XXX
 SG_ ErrorCode : 0|16@1+ (1,0) [0|0] "" Vector__XXX

BO_ 1851 HBGuard_059: 1 Vector__XXX
 SG_ Toggle : 7|1@1+ (1,0) [0|0] "" Vector__XXX
 SG_ State : 0|7@1+ (1,0) [0|0] "" Vector__XXX

BO_ 1467 SSDO_059: 8 Vector__XXX

BO_ 1595 CSDO_059: 8 Vector__XXX

BO_ 187 EMCY_059: 8 Vector__XXX
 SG_ ManufacturerSpecific5 : 56|8@1+ (1,0) [0|0] "" Vector__XXX
 SG_ ManufacturerSpecific4 : 48|8@1+ (1,0) [0|0] "" Vector__XXX
 SG_ ManufacturerSpecific3 : 40|8@1+ (1,0) [0|0] "" Vector__XXX
 SG_ ManufacturerSpecific2 : 32|8@1+ (1,0) [0|0] "" Vector__XXX
 SG_ ManufacturerSpecific1 : 24|8@1+ (1,0) [0|0] "" Vector__XXX
 SG_ ErrorRegisterManufSpecific : 23|1@1+ (1,0) [0|0] "" Vector__XXX
 SG_ ErrorRegisterReserved : 22|1@1+ (1,0) [0|0] "" Vector__XXX
 SG_ ErrorRegisterProfileSpecific : 21|1@1+ (1,0) [0|0] "" Vector__XXX
 SG_ ErrorRegisterCommunication : 20|1@1+ (1,0) [0|0] "" Vector__XXX
 SG_ ErrorRegisterTemperature : 19|1@1+ (1,0) [0|0] "" Vector__XXX
 SG_ ErrorRegisterVoltage : 18|1@1+ (1,0) [0|0] "" Vector__XXX
 SG_ ErrorRegisterCurrent : 17|1@1+ (1,0) [0|0] "" Vector__XXX
 SG_ ErrorRegisterGeneric : 16|1@1+ (1,0) [0|0] "" Vector__XXX
 SG_ ErrorCode : 0|16@1+ (1,0) [0|0] "" Vector__XXX

BO_ 1850 HBGuard_058: 1 Vector__XXX
 SG_ Toggle : 7|1@1+ (1,0) [0|0] "" Vector__XXX
 SG_ State : 0|7@1+ (1,0) [0|0] "" Vector__XXX

BO_ 1466 SSDO_058: 8 Vector__XXX

BO_ 1594 CSDO_058: 8 Vector__XXX

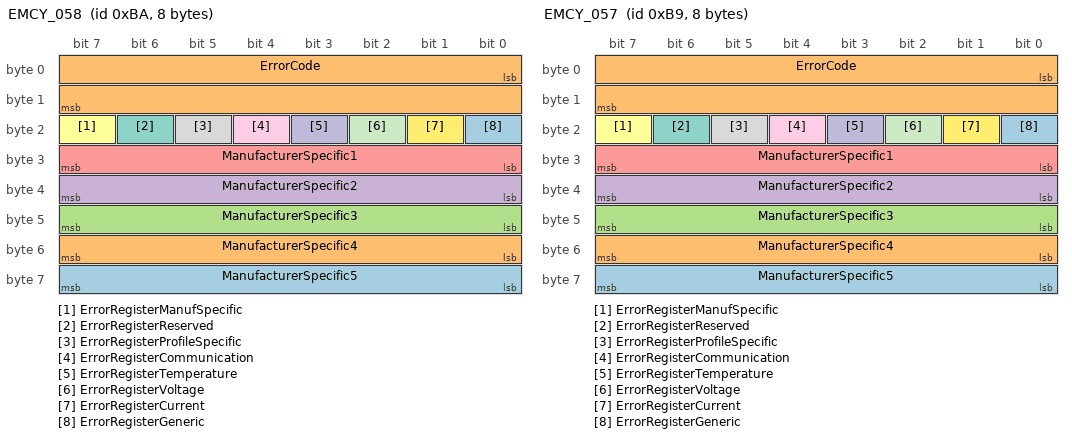
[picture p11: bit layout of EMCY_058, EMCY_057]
BO_ 186 EMCY_058: 8 Vector__XXX
 SG_ ManufacturerSpecific5 : 56|8@1+ (1,0) [0|0] "" Vector__XXX
 SG_ ManufacturerSpecific4 : 48|8@1+ (1,0) [0|0] "" Vector__XXX
 SG_ ManufacturerSpecific3 : 40|8@1+ (1,0) [0|0] "" Vector__XXX
 SG_ ManufacturerSpecific2 : 32|8@1+ (1,0) [0|0] "" Vector__XXX
 SG_ ManufacturerSpecific1 : 24|8@1+ (1,0) [0|0] "" Vector__XXX
 SG_ ErrorRegisterManufSpecific : 23|1@1+ (1,0) [0|0] "" Vector__XXX
 SG_ ErrorRegisterReserved : 22|1@1+ (1,0) [0|0] "" Vector__XXX
 SG_ ErrorRegisterProfileSpecific : 21|1@1+ (1,0) [0|0] "" Vector__XXX
 SG_ ErrorRegisterCommunication : 20|1@1+ (1,0) [0|0] "" Vector__XXX
 SG_ ErrorRegisterTemperature : 19|1@1+ (1,0) [0|0] "" Vector__XXX
 SG_ ErrorRegisterVoltage : 18|1@1+ (1,0) [0|0] "" Vector__XXX
 SG_ ErrorRegisterCurrent : 17|1@1+ (1,0) [0|0] "" Vector__XXX
 SG_ ErrorRegisterGeneric : 16|1@1+ (1,0) [0|0] "" Vector__XXX
 SG_ ErrorCode : 0|16@1+ (1,0) [0|0] "" Vector__XXX

BO_ 1849 HBGuard_057: 1 Vector__XXX
 SG_ Toggle : 7|1@1+ (1,0) [0|0] "" Vector__XXX
 SG_ State : 0|7@1+ (1,0) [0|0] "" Vector__XXX

BO_ 1465 SSDO_057: 8 Vector__XXX

BO_ 1593 CSDO_057: 8 Vector__XXX

BO_ 185 EMCY_057: 8 Vector__XXX
 SG_ ManufacturerSpecific5 : 56|8@1+ (1,0) [0|0] "" Vector__XXX
 SG_ ManufacturerSpecific4 : 48|8@1+ (1,0) [0|0] "" Vector__XXX
 SG_ ManufacturerSpecific3 : 40|8@1+ (1,0) [0|0] "" Vector__XXX
 SG_ ManufacturerSpecific2 : 32|8@1+ (1,0) [0|0] "" Vector__XXX
 SG_ ManufacturerSpecific1 : 24|8@1+ (1,0) [0|0] "" Vector__XXX
 SG_ ErrorRegisterManufSpecific : 23|1@1+ (1,0) [0|0] "" Vector__XXX
 SG_ ErrorRegisterReserved : 22|1@1+ (1,0) [0|0] "" Vector__XXX
 SG_ ErrorRegisterProfileSpecific : 21|1@1+ (1,0) [0|0] "" Vector__XXX
 SG_ ErrorRegisterCommunication : 20|1@1+ (1,0) [0|0] "" Vector__XXX
 SG_ ErrorRegisterTemperature : 19|1@1+ (1,0) [0|0] "" Vector__XXX
 SG_ ErrorRegisterVoltage : 18|1@1+ (1,0) [0|0] "" Vector__XXX
 SG_ ErrorRegisterCurrent : 17|1@1+ (1,0) [0|0] "" Vector__XXX
 SG_ ErrorRegisterGeneric : 16|1@1+ (1,0) [0|0] "" Vector__XXX
 SG_ ErrorCode : 0|16@1+ (1,0) [0|0] "" Vector__XXX

BO_ 1848 HBGuard_056: 1 Vector__XXX
 SG_ Toggle : 7|1@1+ (1,0) [0|0] "" Vector__XXX
 SG_ State : 0|7@1+ (1,0) [0|0] "" Vector__XXX

BO_ 1464 SSDO_056: 8 Vector__XXX

BO_ 1592 CSDO_056: 8 Vector__XXX

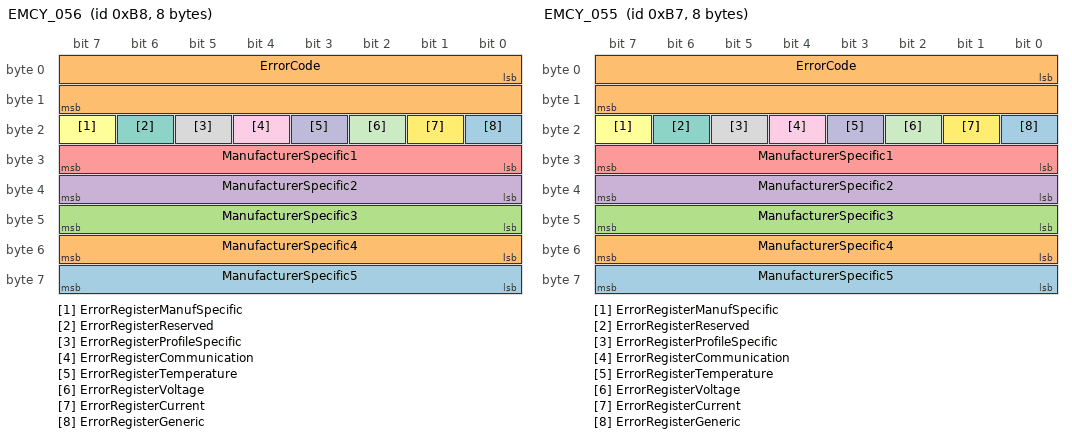
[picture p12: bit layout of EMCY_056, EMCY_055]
BO_ 184 EMCY_056: 8 Vector__XXX
 SG_ ManufacturerSpecific5 : 56|8@1+ (1,0) [0|0] "" Vector__XXX
 SG_ ManufacturerSpecific4 : 48|8@1+ (1,0) [0|0] "" Vector__XXX
 SG_ ManufacturerSpecific3 : 40|8@1+ (1,0) [0|0] "" Vector__XXX
 SG_ ManufacturerSpecific2 : 32|8@1+ (1,0) [0|0] "" Vector__XXX
 SG_ ManufacturerSpecific1 : 24|8@1+ (1,0) [0|0] "" Vector__XXX
 SG_ ErrorRegisterManufSpecific : 23|1@1+ (1,0) [0|0] "" Vector__XXX
 SG_ ErrorRegisterReserved : 22|1@1+ (1,0) [0|0] "" Vector__XXX
 SG_ ErrorRegisterProfileSpecific : 21|1@1+ (1,0) [0|0] "" Vector__XXX
 SG_ ErrorRegisterCommunication : 20|1@1+ (1,0) [0|0] "" Vector__XXX
 SG_ ErrorRegisterTemperature : 19|1@1+ (1,0) [0|0] "" Vector__XXX
 SG_ ErrorRegisterVoltage : 18|1@1+ (1,0) [0|0] "" Vector__XXX
 SG_ ErrorRegisterCurrent : 17|1@1+ (1,0) [0|0] "" Vector__XXX
 SG_ ErrorRegisterGeneric : 16|1@1+ (1,0) [0|0] "" Vector__XXX
 SG_ ErrorCode : 0|16@1+ (1,0) [0|0] "" Vector__XXX

BO_ 1847 HBGuard_055: 1 Vector__XXX
 SG_ Toggle : 7|1@1+ (1,0) [0|0] "" Vector__XXX
 SG_ State : 0|7@1+ (1,0) [0|0] "" Vector__XXX

BO_ 1463 SSDO_055: 8 Vector__XXX

BO_ 1591 CSDO_055: 8 Vector__XXX

BO_ 183 EMCY_055: 8 Vector__XXX
 SG_ ManufacturerSpecific5 : 56|8@1+ (1,0) [0|0] "" Vector__XXX
 SG_ ManufacturerSpecific4 : 48|8@1+ (1,0) [0|0] "" Vector__XXX
 SG_ ManufacturerSpecific3 : 40|8@1+ (1,0) [0|0] "" Vector__XXX
 SG_ ManufacturerSpecific2 : 32|8@1+ (1,0) [0|0] "" Vector__XXX
 SG_ ManufacturerSpecific1 : 24|8@1+ (1,0) [0|0] "" Vector__XXX
 SG_ ErrorRegisterManufSpecific : 23|1@1+ (1,0) [0|0] "" Vector__XXX
 SG_ ErrorRegisterReserved : 22|1@1+ (1,0) [0|0] "" Vector__XXX
 SG_ ErrorRegisterProfileSpecific : 21|1@1+ (1,0) [0|0] "" Vector__XXX
 SG_ ErrorRegisterCommunication : 20|1@1+ (1,0) [0|0] "" Vector__XXX
 SG_ ErrorRegisterTemperature : 19|1@1+ (1,0) [0|0] "" Vector__XXX
 SG_ ErrorRegisterVoltage : 18|1@1+ (1,0) [0|0] "" Vector__XXX
 SG_ ErrorRegisterCurrent : 17|1@1+ (1,0) [0|0] "" Vector__XXX
 SG_ ErrorRegisterGeneric : 16|1@1+ (1,0) [0|0] "" Vector__XXX
 SG_ ErrorCode : 0|16@1+ (1,0) [0|0] "" Vector__XXX

BO_ 1846 HBGuard_054: 1 Vector__XXX
 SG_ Toggle : 7|1@1+ (1,0) [0|0] "" Vector__XXX
 SG_ State : 0|7@1+ (1,0) [0|0] "" Vector__XXX

BO_ 1462 SSDO_054: 8 Vector__XXX

BO_ 1590 CSDO_054: 8 Vector__XXX

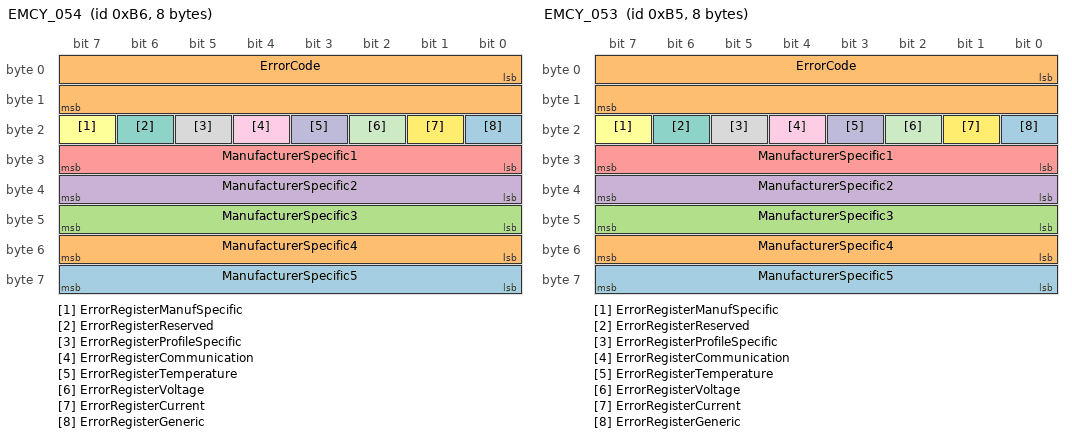
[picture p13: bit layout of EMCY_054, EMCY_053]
BO_ 182 EMCY_054: 8 Vector__XXX
 SG_ ManufacturerSpecific5 : 56|8@1+ (1,0) [0|0] "" Vector__XXX
 SG_ ManufacturerSpecific4 : 48|8@1+ (1,0) [0|0] "" Vector__XXX
 SG_ ManufacturerSpecific3 : 40|8@1+ (1,0) [0|0] "" Vector__XXX
 SG_ ManufacturerSpecific2 : 32|8@1+ (1,0) [0|0] "" Vector__XXX
 SG_ ManufacturerSpecific1 : 24|8@1+ (1,0) [0|0] "" Vector__XXX
 SG_ ErrorRegisterManufSpecific : 23|1@1+ (1,0) [0|0] "" Vector__XXX
 SG_ ErrorRegisterReserved : 22|1@1+ (1,0) [0|0] "" Vector__XXX
 SG_ ErrorRegisterProfileSpecific : 21|1@1+ (1,0) [0|0] "" Vector__XXX
 SG_ ErrorRegisterCommunication : 20|1@1+ (1,0) [0|0] "" Vector__XXX
 SG_ ErrorRegisterTemperature : 19|1@1+ (1,0) [0|0] "" Vector__XXX
 SG_ ErrorRegisterVoltage : 18|1@1+ (1,0) [0|0] "" Vector__XXX
 SG_ ErrorRegisterCurrent : 17|1@1+ (1,0) [0|0] "" Vector__XXX
 SG_ ErrorRegisterGeneric : 16|1@1+ (1,0) [0|0] "" Vector__XXX
 SG_ ErrorCode : 0|16@1+ (1,0) [0|0] "" Vector__XXX

BO_ 1845 HBGuard_053: 1 Vector__XXX
 SG_ Toggle : 7|1@1+ (1,0) [0|0] "" Vector__XXX
 SG_ State : 0|7@1+ (1,0) [0|0] "" Vector__XXX

BO_ 1461 SSDO_053: 8 Vector__XXX

BO_ 1589 CSDO_053: 8 Vector__XXX

BO_ 181 EMCY_053: 8 Vector__XXX
 SG_ ManufacturerSpecific5 : 56|8@1+ (1,0) [0|0] "" Vector__XXX
 SG_ ManufacturerSpecific4 : 48|8@1+ (1,0) [0|0] "" Vector__XXX
 SG_ ManufacturerSpecific3 : 40|8@1+ (1,0) [0|0] "" Vector__XXX
 SG_ ManufacturerSpecific2 : 32|8@1+ (1,0) [0|0] "" Vector__XXX
 SG_ ManufacturerSpecific1 : 24|8@1+ (1,0) [0|0] "" Vector__XXX
 SG_ ErrorRegisterManufSpecific : 23|1@1+ (1,0) [0|0] "" Vector__XXX
 SG_ ErrorRegisterReserved : 22|1@1+ (1,0) [0|0] "" Vector__XXX
 SG_ ErrorRegisterProfileSpecific : 21|1@1+ (1,0) [0|0] "" Vector__XXX
 SG_ ErrorRegisterCommunication : 20|1@1+ (1,0) [0|0] "" Vector__XXX
 SG_ ErrorRegisterTemperature : 19|1@1+ (1,0) [0|0] "" Vector__XXX
 SG_ ErrorRegisterVoltage : 18|1@1+ (1,0) [0|0] "" Vector__XXX
 SG_ ErrorRegisterCurrent : 17|1@1+ (1,0) [0|0] "" Vector__XXX
 SG_ ErrorRegisterGeneric : 16|1@1+ (1,0) [0|0] "" Vector__XXX
 SG_ ErrorCode : 0|16@1+ (1,0) [0|0] "" Vector__XXX

BO_ 1844 HBGuard_052: 1 Vector__XXX
 SG_ Toggle : 7|1@1+ (1,0) [0|0] "" Vector__XXX
 SG_ State : 0|7@1+ (1,0) [0|0] "" Vector__XXX

BO_ 1460 SSDO_052: 8 Vector__XXX

BO_ 1588 CSDO_052: 8 Vector__XXX

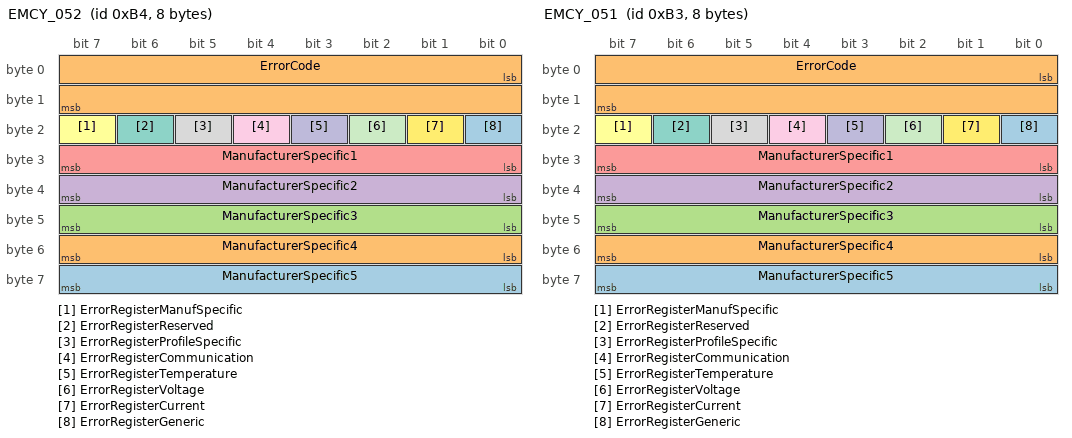
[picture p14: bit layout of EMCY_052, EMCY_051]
BO_ 180 EMCY_052: 8 Vector__XXX
 SG_ ManufacturerSpecific5 : 56|8@1+ (1,0) [0|0] "" Vector__XXX
 SG_ ManufacturerSpecific4 : 48|8@1+ (1,0) [0|0] "" Vector__XXX
 SG_ ManufacturerSpecific3 : 40|8@1+ (1,0) [0|0] "" Vector__XXX
 SG_ ManufacturerSpecific2 : 32|8@1+ (1,0) [0|0] "" Vector__XXX
 SG_ ManufacturerSpecific1 : 24|8@1+ (1,0) [0|0] "" Vector__XXX
 SG_ ErrorRegisterManufSpecific : 23|1@1+ (1,0) [0|0] "" Vector__XXX
 SG_ ErrorRegisterReserved : 22|1@1+ (1,0) [0|0] "" Vector__XXX
 SG_ ErrorRegisterProfileSpecific : 21|1@1+ (1,0) [0|0] "" Vector__XXX
 SG_ ErrorRegisterCommunication : 20|1@1+ (1,0) [0|0] "" Vector__XXX
 SG_ ErrorRegisterTemperature : 19|1@1+ (1,0) [0|0] "" Vector__XXX
 SG_ ErrorRegisterVoltage : 18|1@1+ (1,0) [0|0] "" Vector__XXX
 SG_ ErrorRegisterCurrent : 17|1@1+ (1,0) [0|0] "" Vector__XXX
 SG_ ErrorRegisterGeneric : 16|1@1+ (1,0) [0|0] "" Vector__XXX
 SG_ ErrorCode : 0|16@1+ (1,0) [0|0] "" Vector__XXX

BO_ 1843 HBGuard_051: 1 Vector__XXX
 SG_ Toggle : 7|1@1+ (1,0) [0|0] "" Vector__XXX
 SG_ State : 0|7@1+ (1,0) [0|0] "" Vector__XXX

BO_ 1459 SSDO_051: 8 Vector__XXX

BO_ 1587 CSDO_051: 8 Vector__XXX

BO_ 179 EMCY_051: 8 Vector__XXX
 SG_ ManufacturerSpecific5 : 56|8@1+ (1,0) [0|0] "" Vector__XXX
 SG_ ManufacturerSpecific4 : 48|8@1+ (1,0) [0|0] "" Vector__XXX
 SG_ ManufacturerSpecific3 : 40|8@1+ (1,0) [0|0] "" Vector__XXX
 SG_ ManufacturerSpecific2 : 32|8@1+ (1,0) [0|0] "" Vector__XXX
 SG_ ManufacturerSpecific1 : 24|8@1+ (1,0) [0|0] "" Vector__XXX
 SG_ ErrorRegisterManufSpecific : 23|1@1+ (1,0) [0|0] "" Vector__XXX
 SG_ ErrorRegisterReserved : 22|1@1+ (1,0) [0|0] "" Vector__XXX
 SG_ ErrorRegisterProfileSpecific : 21|1@1+ (1,0) [0|0] "" Vector__XXX
 SG_ ErrorRegisterCommunication : 20|1@1+ (1,0) [0|0] "" Vector__XXX
 SG_ ErrorRegisterTemperature : 19|1@1+ (1,0) [0|0] "" Vector__XXX
 SG_ ErrorRegisterVoltage : 18|1@1+ (1,0) [0|0] "" Vector__XXX
 SG_ ErrorRegisterCurrent : 17|1@1+ (1,0) [0|0] "" Vector__XXX
 SG_ ErrorRegisterGeneric : 16|1@1+ (1,0) [0|0] "" Vector__XXX
 SG_ ErrorCode : 0|16@1+ (1,0) [0|0] "" Vector__XXX

BO_ 1842 HBGuard_050: 1 Vector__XXX
 SG_ Toggle : 7|1@1+ (1,0) [0|0] "" Vector__XXX
 SG_ State : 0|7@1+ (1,0) [0|0] "" Vector__XXX

BO_ 1458 SSDO_050: 8 Vector__XXX

BO_ 1586 CSDO_050: 8 Vector__XXX

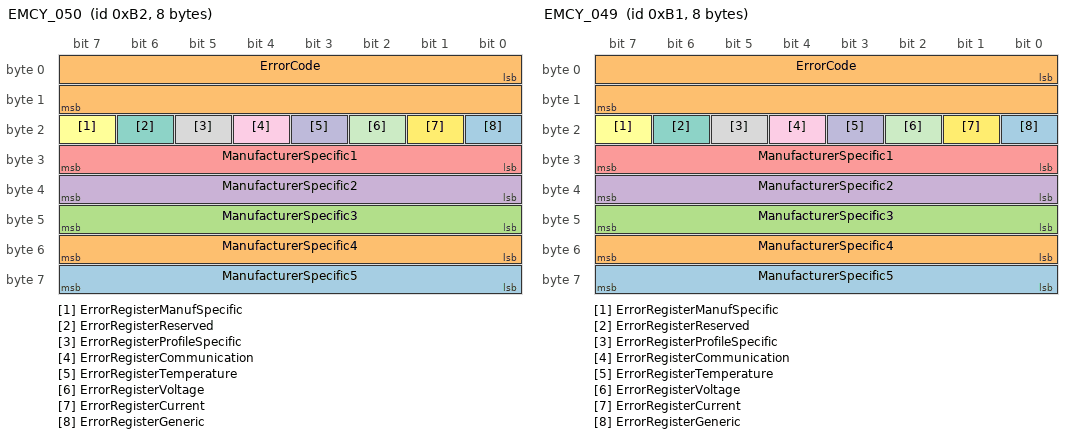
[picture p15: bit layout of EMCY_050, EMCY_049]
BO_ 178 EMCY_050: 8 Vector__XXX
 SG_ ManufacturerSpecific5 : 56|8@1+ (1,0) [0|0] "" Vector__XXX
 SG_ ManufacturerSpecific4 : 48|8@1+ (1,0) [0|0] "" Vector__XXX
 SG_ ManufacturerSpecific3 : 40|8@1+ (1,0) [0|0] "" Vector__XXX
 SG_ ManufacturerSpecific2 : 32|8@1+ (1,0) [0|0] "" Vector__XXX
 SG_ ManufacturerSpecific1 : 24|8@1+ (1,0) [0|0] "" Vector__XXX
 SG_ ErrorRegisterManufSpecific : 23|1@1+ (1,0) [0|0] "" Vector__XXX
 SG_ ErrorRegisterReserved : 22|1@1+ (1,0) [0|0] "" Vector__XXX
 SG_ ErrorRegisterProfileSpecific : 21|1@1+ (1,0) [0|0] "" Vector__XXX
 SG_ ErrorRegisterCommunication : 20|1@1+ (1,0) [0|0] "" Vector__XXX
 SG_ ErrorRegisterTemperature : 19|1@1+ (1,0) [0|0] "" Vector__XXX
 SG_ ErrorRegisterVoltage : 18|1@1+ (1,0) [0|0] "" Vector__XXX
 SG_ ErrorRegisterCurrent : 17|1@1+ (1,0) [0|0] "" Vector__XXX
 SG_ ErrorRegisterGeneric : 16|1@1+ (1,0) [0|0] "" Vector__XXX
 SG_ ErrorCode : 0|16@1+ (1,0) [0|0] "" Vector__XXX

BO_ 1841 HBGuard_049: 1 Vector__XXX
 SG_ Toggle : 7|1@1+ (1,0) [0|0] "" Vector__XXX
 SG_ State : 0|7@1+ (1,0) [0|0] "" Vector__XXX

BO_ 1457 SSDO_049: 8 Vector__XXX

BO_ 1585 CSDO_049: 8 Vector__XXX

BO_ 177 EMCY_049: 8 Vector__XXX
 SG_ ManufacturerSpecific5 : 56|8@1+ (1,0) [0|0] "" Vector__XXX
 SG_ ManufacturerSpecific4 : 48|8@1+ (1,0) [0|0] "" Vector__XXX
 SG_ ManufacturerSpecific3 : 40|8@1+ (1,0) [0|0] "" Vector__XXX
 SG_ ManufacturerSpecific2 : 32|8@1+ (1,0) [0|0] "" Vector__XXX
 SG_ ManufacturerSpecific1 : 24|8@1+ (1,0) [0|0] "" Vector__XXX
 SG_ ErrorRegisterManufSpecific : 23|1@1+ (1,0) [0|0] "" Vector__XXX
 SG_ ErrorRegisterReserved : 22|1@1+ (1,0) [0|0] "" Vector__XXX
 SG_ ErrorRegisterProfileSpecific : 21|1@1+ (1,0) [0|0] "" Vector__XXX
 SG_ ErrorRegisterCommunication : 20|1@1+ (1,0) [0|0] "" Vector__XXX
 SG_ ErrorRegisterTemperature : 19|1@1+ (1,0) [0|0] "" Vector__XXX
 SG_ ErrorRegisterVoltage : 18|1@1+ (1,0) [0|0] "" Vector__XXX
 SG_ ErrorRegisterCurrent : 17|1@1+ (1,0) [0|0] "" Vector__XXX
 SG_ ErrorRegisterGeneric : 16|1@1+ (1,0) [0|0] "" Vector__XXX
 SG_ ErrorCode : 0|16@1+ (1,0) [0|0] "" Vector__XXX

BO_ 1840 HBGuard_048: 1 Vector__XXX
 SG_ Toggle : 7|1@1+ (1,0) [0|0] "" Vector__XXX
 SG_ State : 0|7@1+ (1,0) [0|0] "" Vector__XXX

BO_ 1456 SSDO_048: 8 Vector__XXX

BO_ 1584 CSDO_048: 8 Vector__XXX

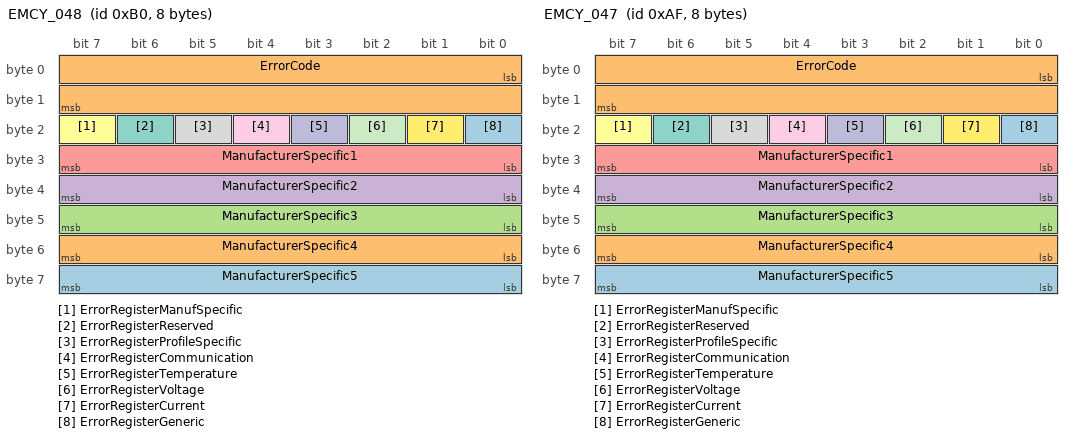
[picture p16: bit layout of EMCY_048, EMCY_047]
BO_ 176 EMCY_048: 8 Vector__XXX
 SG_ ManufacturerSpecific5 : 56|8@1+ (1,0) [0|0] "" Vector__XXX
 SG_ ManufacturerSpecific4 : 48|8@1+ (1,0) [0|0] "" Vector__XXX
 SG_ ManufacturerSpecific3 : 40|8@1+ (1,0) [0|0] "" Vector__XXX
 SG_ ManufacturerSpecific2 : 32|8@1+ (1,0) [0|0] "" Vector__XXX
 SG_ ManufacturerSpecific1 : 24|8@1+ (1,0) [0|0] "" Vector__XXX
 SG_ ErrorRegisterManufSpecific : 23|1@1+ (1,0) [0|0] "" Vector__XXX
 SG_ ErrorRegisterReserved : 22|1@1+ (1,0) [0|0] "" Vector__XXX
 SG_ ErrorRegisterProfileSpecific : 21|1@1+ (1,0) [0|0] "" Vector__XXX
 SG_ ErrorRegisterCommunication : 20|1@1+ (1,0) [0|0] "" Vector__XXX
 SG_ ErrorRegisterTemperature : 19|1@1+ (1,0) [0|0] "" Vector__XXX
 SG_ ErrorRegisterVoltage : 18|1@1+ (1,0) [0|0] "" Vector__XXX
 SG_ ErrorRegisterCurrent : 17|1@1+ (1,0) [0|0] "" Vector__XXX
 SG_ ErrorRegisterGeneric : 16|1@1+ (1,0) [0|0] "" Vector__XXX
 SG_ ErrorCode : 0|16@1+ (1,0) [0|0] "" Vector__XXX

BO_ 1839 HBGuard_047: 1 Vector__XXX
 SG_ Toggle : 7|1@1+ (1,0) [0|0] "" Vector__XXX
 SG_ State : 0|7@1+ (1,0) [0|0] "" Vector__XXX

BO_ 1455 SSDO_047: 8 Vector__XXX

BO_ 1583 CSDO_047: 8 Vector__XXX

BO_ 175 EMCY_047: 8 Vector__XXX
 SG_ ManufacturerSpecific5 : 56|8@1+ (1,0) [0|0] "" Vector__XXX
 SG_ ManufacturerSpecific4 : 48|8@1+ (1,0) [0|0] "" Vector__XXX
 SG_ ManufacturerSpecific3 : 40|8@1+ (1,0) [0|0] "" Vector__XXX
 SG_ ManufacturerSpecific2 : 32|8@1+ (1,0) [0|0] "" Vector__XXX
 SG_ ManufacturerSpecific1 : 24|8@1+ (1,0) [0|0] "" Vector__XXX
 SG_ ErrorRegisterManufSpecific : 23|1@1+ (1,0) [0|0] "" Vector__XXX
 SG_ ErrorRegisterReserved : 22|1@1+ (1,0) [0|0] "" Vector__XXX
 SG_ ErrorRegisterProfileSpecific : 21|1@1+ (1,0) [0|0] "" Vector__XXX
 SG_ ErrorRegisterCommunication : 20|1@1+ (1,0) [0|0] "" Vector__XXX
 SG_ ErrorRegisterTemperature : 19|1@1+ (1,0) [0|0] "" Vector__XXX
 SG_ ErrorRegisterVoltage : 18|1@1+ (1,0) [0|0] "" Vector__XXX
 SG_ ErrorRegisterCurrent : 17|1@1+ (1,0) [0|0] "" Vector__XXX
 SG_ ErrorRegisterGeneric : 16|1@1+ (1,0) [0|0] "" Vector__XXX
 SG_ ErrorCode : 0|16@1+ (1,0) [0|0] "" Vector__XXX

BO_ 1838 HBGuard_046: 1 Vector__XXX
 SG_ Toggle : 7|1@1+ (1,0) [0|0] "" Vector__XXX
 SG_ State : 0|7@1+ (1,0) [0|0] "" Vector__XXX

BO_ 1454 SSDO_046: 8 Vector__XXX

BO_ 1582 CSDO_046: 8 Vector__XXX

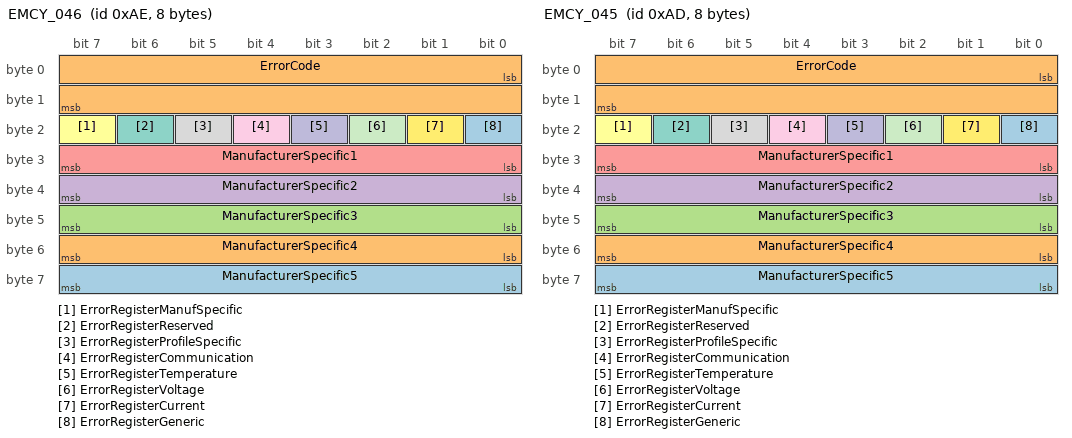
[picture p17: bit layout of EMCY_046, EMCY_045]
BO_ 174 EMCY_046: 8 Vector__XXX
 SG_ ManufacturerSpecific5 : 56|8@1+ (1,0) [0|0] "" Vector__XXX
 SG_ ManufacturerSpecific4 : 48|8@1+ (1,0) [0|0] "" Vector__XXX
 SG_ ManufacturerSpecific3 : 40|8@1+ (1,0) [0|0] "" Vector__XXX
 SG_ ManufacturerSpecific2 : 32|8@1+ (1,0) [0|0] "" Vector__XXX
 SG_ ManufacturerSpecific1 : 24|8@1+ (1,0) [0|0] "" Vector__XXX
 SG_ ErrorRegisterManufSpecific : 23|1@1+ (1,0) [0|0] "" Vector__XXX
 SG_ ErrorRegisterReserved : 22|1@1+ (1,0) [0|0] "" Vector__XXX
 SG_ ErrorRegisterProfileSpecific : 21|1@1+ (1,0) [0|0] "" Vector__XXX
 SG_ ErrorRegisterCommunication : 20|1@1+ (1,0) [0|0] "" Vector__XXX
 SG_ ErrorRegisterTemperature : 19|1@1+ (1,0) [0|0] "" Vector__XXX
 SG_ ErrorRegisterVoltage : 18|1@1+ (1,0) [0|0] "" Vector__XXX
 SG_ ErrorRegisterCurrent : 17|1@1+ (1,0) [0|0] "" Vector__XXX
 SG_ ErrorRegisterGeneric : 16|1@1+ (1,0) [0|0] "" Vector__XXX
 SG_ ErrorCode : 0|16@1+ (1,0) [0|0] "" Vector__XXX

BO_ 1837 HBGuard_045: 1 Vector__XXX
 SG_ Toggle : 7|1@1+ (1,0) [0|0] "" Vector__XXX
 SG_ State : 0|7@1+ (1,0) [0|0] "" Vector__XXX

BO_ 1453 SSDO_045: 8 Vector__XXX

BO_ 1581 CSDO_045: 8 Vector__XXX

BO_ 173 EMCY_045: 8 Vector__XXX
 SG_ ManufacturerSpecific5 : 56|8@1+ (1,0) [0|0] "" Vector__XXX
 SG_ ManufacturerSpecific4 : 48|8@1+ (1,0) [0|0] "" Vector__XXX
 SG_ ManufacturerSpecific3 : 40|8@1+ (1,0) [0|0] "" Vector__XXX
 SG_ ManufacturerSpecific2 : 32|8@1+ (1,0) [0|0] "" Vector__XXX
 SG_ ManufacturerSpecific1 : 24|8@1+ (1,0) [0|0] "" Vector__XXX
 SG_ ErrorRegisterManufSpecific : 23|1@1+ (1,0) [0|0] "" Vector__XXX
 SG_ ErrorRegisterReserved : 22|1@1+ (1,0) [0|0] "" Vector__XXX
 SG_ ErrorRegisterProfileSpecific : 21|1@1+ (1,0) [0|0] "" Vector__XXX
 SG_ ErrorRegisterCommunication : 20|1@1+ (1,0) [0|0] "" Vector__XXX
 SG_ ErrorRegisterTemperature : 19|1@1+ (1,0) [0|0] "" Vector__XXX
 SG_ ErrorRegisterVoltage : 18|1@1+ (1,0) [0|0] "" Vector__XXX
 SG_ ErrorRegisterCurrent : 17|1@1+ (1,0) [0|0] "" Vector__XXX
 SG_ ErrorRegisterGeneric : 16|1@1+ (1,0) [0|0] "" Vector__XXX
 SG_ ErrorCode : 0|16@1+ (1,0) [0|0] "" Vector__XXX

BO_ 1836 HBGuard_044: 1 Vector__XXX
 SG_ Toggle : 7|1@1+ (1,0) [0|0] "" Vector__XXX
 SG_ State : 0|7@1+ (1,0) [0|0] "" Vector__XXX

BO_ 1452 SSDO_044: 8 Vector__XXX

BO_ 1580 CSDO_044: 8 Vector__XXX

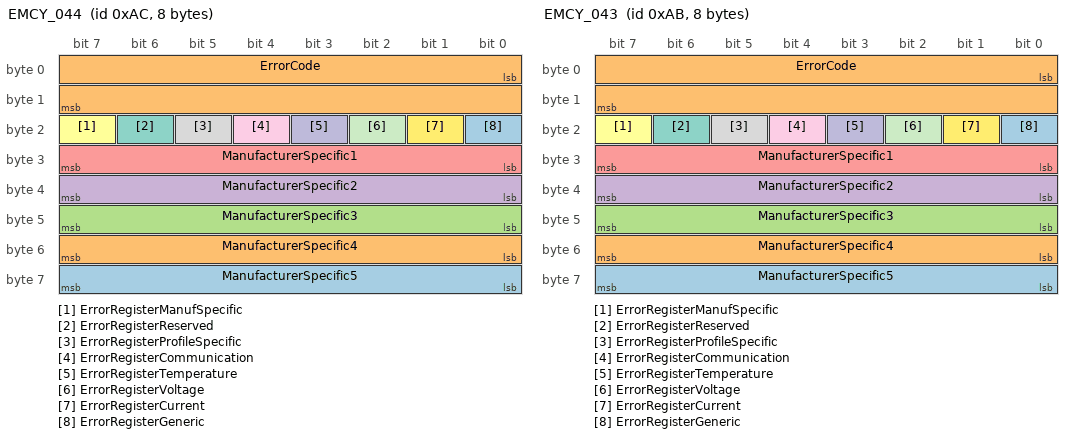
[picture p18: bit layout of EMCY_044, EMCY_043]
BO_ 172 EMCY_044: 8 Vector__XXX
 SG_ ManufacturerSpecific5 : 56|8@1+ (1,0) [0|0] "" Vector__XXX
 SG_ ManufacturerSpecific4 : 48|8@1+ (1,0) [0|0] "" Vector__XXX
 SG_ ManufacturerSpecific3 : 40|8@1+ (1,0) [0|0] "" Vector__XXX
 SG_ ManufacturerSpecific2 : 32|8@1+ (1,0) [0|0] "" Vector__XXX
 SG_ ManufacturerSpecific1 : 24|8@1+ (1,0) [0|0] "" Vector__XXX
 SG_ ErrorRegisterManufSpecific : 23|1@1+ (1,0) [0|0] "" Vector__XXX
 SG_ ErrorRegisterReserved : 22|1@1+ (1,0) [0|0] "" Vector__XXX
 SG_ ErrorRegisterProfileSpecific : 21|1@1+ (1,0) [0|0] "" Vector__XXX
 SG_ ErrorRegisterCommunication : 20|1@1+ (1,0) [0|0] "" Vector__XXX
 SG_ ErrorRegisterTemperature : 19|1@1+ (1,0) [0|0] "" Vector__XXX
 SG_ ErrorRegisterVoltage : 18|1@1+ (1,0) [0|0] "" Vector__XXX
 SG_ ErrorRegisterCurrent : 17|1@1+ (1,0) [0|0] "" Vector__XXX
 SG_ ErrorRegisterGeneric : 16|1@1+ (1,0) [0|0] "" Vector__XXX
 SG_ ErrorCode : 0|16@1+ (1,0) [0|0] "" Vector__XXX

BO_ 1835 HBGuard_043: 1 Vector__XXX
 SG_ Toggle : 7|1@1+ (1,0) [0|0] "" Vector__XXX
 SG_ State : 0|7@1+ (1,0) [0|0] "" Vector__XXX

BO_ 1451 SSDO_043: 8 Vector__XXX

BO_ 1579 CSDO_043: 8 Vector__XXX

BO_ 171 EMCY_043: 8 Vector__XXX
 SG_ ManufacturerSpecific5 : 56|8@1+ (1,0) [0|0] "" Vector__XXX
 SG_ ManufacturerSpecific4 : 48|8@1+ (1,0) [0|0] "" Vector__XXX
 SG_ ManufacturerSpecific3 : 40|8@1+ (1,0) [0|0] "" Vector__XXX
 SG_ ManufacturerSpecific2 : 32|8@1+ (1,0) [0|0] "" Vector__XXX
 SG_ ManufacturerSpecific1 : 24|8@1+ (1,0) [0|0] "" Vector__XXX
 SG_ ErrorRegisterManufSpecific : 23|1@1+ (1,0) [0|0] "" Vector__XXX
 SG_ ErrorRegisterReserved : 22|1@1+ (1,0) [0|0] "" Vector__XXX
 SG_ ErrorRegisterProfileSpecific : 21|1@1+ (1,0) [0|0] "" Vector__XXX
 SG_ ErrorRegisterCommunication : 20|1@1+ (1,0) [0|0] "" Vector__XXX
 SG_ ErrorRegisterTemperature : 19|1@1+ (1,0) [0|0] "" Vector__XXX
 SG_ ErrorRegisterVoltage : 18|1@1+ (1,0) [0|0] "" Vector__XXX
 SG_ ErrorRegisterCurrent : 17|1@1+ (1,0) [0|0] "" Vector__XXX
 SG_ ErrorRegisterGeneric : 16|1@1+ (1,0) [0|0] "" Vector__XXX
 SG_ ErrorCode : 0|16@1+ (1,0) [0|0] "" Vector__XXX

BO_ 1834 HBGuard_042: 1 Vector__XXX
 SG_ Toggle : 7|1@1+ (1,0) [0|0] "" Vector__XXX
 SG_ State : 0|7@1+ (1,0) [0|0] "" Vector__XXX

BO_ 1450 SSDO_042: 8 Vector__XXX

BO_ 1578 CSDO_042: 8 Vector__XXX

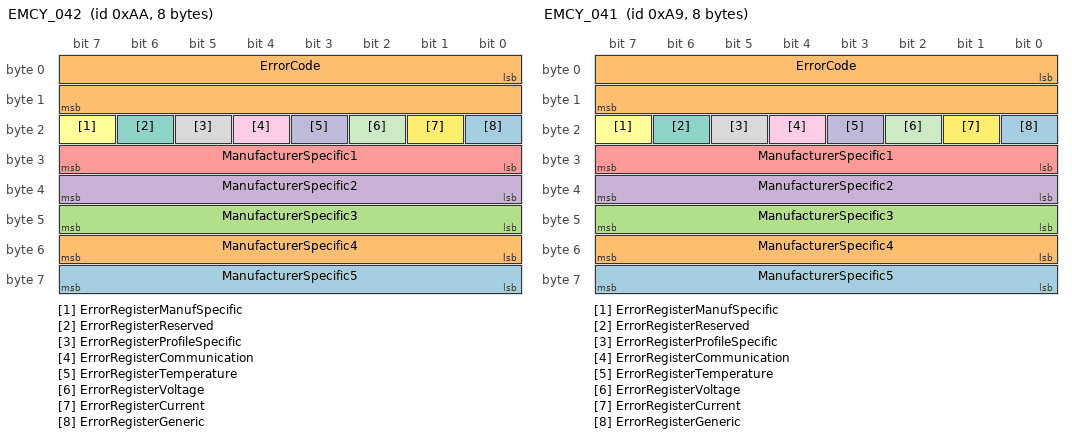
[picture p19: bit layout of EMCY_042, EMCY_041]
BO_ 170 EMCY_042: 8 Vector__XXX
 SG_ ManufacturerSpecific5 : 56|8@1+ (1,0) [0|0] "" Vector__XXX
 SG_ ManufacturerSpecific4 : 48|8@1+ (1,0) [0|0] "" Vector__XXX
 SG_ ManufacturerSpecific3 : 40|8@1+ (1,0) [0|0] "" Vector__XXX
 SG_ ManufacturerSpecific2 : 32|8@1+ (1,0) [0|0] "" Vector__XXX
 SG_ ManufacturerSpecific1 : 24|8@1+ (1,0) [0|0] "" Vector__XXX
 SG_ ErrorRegisterManufSpecific : 23|1@1+ (1,0) [0|0] "" Vector__XXX
 SG_ ErrorRegisterReserved : 22|1@1+ (1,0) [0|0] "" Vector__XXX
 SG_ ErrorRegisterProfileSpecific : 21|1@1+ (1,0) [0|0] "" Vector__XXX
 SG_ ErrorRegisterCommunication : 20|1@1+ (1,0) [0|0] "" Vector__XXX
 SG_ ErrorRegisterTemperature : 19|1@1+ (1,0) [0|0] "" Vector__XXX
 SG_ ErrorRegisterVoltage : 18|1@1+ (1,0) [0|0] "" Vector__XXX
 SG_ ErrorRegisterCurrent : 17|1@1+ (1,0) [0|0] "" Vector__XXX
 SG_ ErrorRegisterGeneric : 16|1@1+ (1,0) [0|0] "" Vector__XXX
 SG_ ErrorCode : 0|16@1+ (1,0) [0|0] "" Vector__XXX

BO_ 1833 HBGuard_041: 1 Vector__XXX
 SG_ Toggle : 7|1@1+ (1,0) [0|0] "" Vector__XXX
 SG_ State : 0|7@1+ (1,0) [0|0] "" Vector__XXX

BO_ 1449 SSDO_041: 8 Vector__XXX

BO_ 1577 CSDO_041: 8 Vector__XXX

BO_ 169 EMCY_041: 8 Vector__XXX
 SG_ ManufacturerSpecific5 : 56|8@1+ (1,0) [0|0] "" Vector__XXX
 SG_ ManufacturerSpecific4 : 48|8@1+ (1,0) [0|0] "" Vector__XXX
 SG_ ManufacturerSpecific3 : 40|8@1+ (1,0) [0|0] "" Vector__XXX
 SG_ ManufacturerSpecific2 : 32|8@1+ (1,0) [0|0] "" Vector__XXX
 SG_ ManufacturerSpecific1 : 24|8@1+ (1,0) [0|0] "" Vector__XXX
 SG_ ErrorRegisterManufSpecific : 23|1@1+ (1,0) [0|0] "" Vector__XXX
 SG_ ErrorRegisterReserved : 22|1@1+ (1,0) [0|0] "" Vector__XXX
 SG_ ErrorRegisterProfileSpecific : 21|1@1+ (1,0) [0|0] "" Vector__XXX
 SG_ ErrorRegisterCommunication : 20|1@1+ (1,0) [0|0] "" Vector__XXX
 SG_ ErrorRegisterTemperature : 19|1@1+ (1,0) [0|0] "" Vector__XXX
 SG_ ErrorRegisterVoltage : 18|1@1+ (1,0) [0|0] "" Vector__XXX
 SG_ ErrorRegisterCurrent : 17|1@1+ (1,0) [0|0] "" Vector__XXX
 SG_ ErrorRegisterGeneric : 16|1@1+ (1,0) [0|0] "" Vector__XXX
 SG_ ErrorCode : 0|16@1+ (1,0) [0|0] "" Vector__XXX

BO_ 1832 HBGuard_040: 1 Vector__XXX
 SG_ Toggle : 7|1@1+ (1,0) [0|0] "" Vector__XXX
 SG_ State : 0|7@1+ (1,0) [0|0] "" Vector__XXX

BO_ 1448 SSDO_040: 8 Vector__XXX

BO_ 1576 CSDO_040: 8 Vector__XXX

BO_ 168 EMCY_040: 8 Vector__XXX
 SG_ ManufacturerSpecific5 : 56|8@1+ (1,0) [0|0] "" Vector__XXX
 SG_ ManufacturerSpecific4 : 48|8@1+ (1,0) [0|0] "" Vector__XXX
 SG_ ManufacturerSpecific3 : 40|8@1+ (1,0) [0|0] "" Vector__XXX
 SG_ ManufacturerSpecific2 : 32|8@1+ (1,0) [0|0] "" Vector__XXX
 SG_ ManufacturerSpecific1 : 24|8@1+ (1,0) [0|0] "" Vector__XXX
 SG_ ErrorRegisterManufSpecific : 23|1@1+ (1,0) [0|0] "" Vector__XXX
 SG_ ErrorRegisterReserved : 22|1@1+ (1,0) [0|0] "" Vector__XXX
 SG_ ErrorRegisterProfileSpecific : 21|1@1+ (1,0) [0|0] "" Vector__XXX
 SG_ ErrorRegisterCommunication : 20|1@1+ (1,0) [0|0] "" Vector__XXX
 SG_ ErrorRegisterTemperature : 19|1@1+ (1,0) [0|0] "" Vector__XXX
 SG_ ErrorRegisterVoltage : 18|1@1+ (1,0) [0|0] "" Vector__XXX
 SG_ ErrorRegisterCurrent : 17|1@1+ (1,0) [0|0] "" Vector__XXX
 SG_ ErrorRegisterGeneric : 16|1@1+ (1,0) [0|0] "" Vector__XXX
 SG_ ErrorCode : 0|16@1+ (1,0) [0|0] "" Vector__XXX

BO_ 1831 HBGuard_039: 1 Vector__XXX
 SG_ Toggle : 7|1@1+ (1,0) [0|0] "" Vector__XXX
 SG_ State : 0|7@1+ (1,0) [0|0] "" Vector__XXX

BO_ 1447 SSDO_039: 8 Vector__XXX

BO_ 1575 CSDO_039: 8 Vector__XXX

BO_ 167 EMCY_039: 8 Vector__XXX
 SG_ ManufacturerSpecific5 : 56|8@1+ (1,0) [0|0] "" Vector__XXX
 SG_ ManufacturerSpecific4 : 48|8@1+ (1,0) [0|0] "" Vector__XXX
 SG_ ManufacturerSpecific3 : 40|8@1+ (1,0) [0|0] "" Vector__XXX
 SG_ ManufacturerSpecific2 : 32|8@1+ (1,0) [0|0] "" Vector__XXX
 SG_ ManufacturerSpecific1 : 24|8@1+ (1,0) [0|0] "" Vector__XXX
 SG_ ErrorRegisterManufSpecific : 23|1@1+ (1,0) [0|0] "" Vector__XXX
 SG_ ErrorRegisterReserved : 22|1@1+ (1,0) [0|0] "" Vector__XXX
 SG_ ErrorRegisterProfileSpecific : 21|1@1+ (1,0) [0|0] "" Vector__XXX
 SG_ ErrorRegisterCommunication : 20|1@1+ (1,0) [0|0] "" Vector__XXX
 SG_ ErrorRegisterTemperature : 19|1@1+ (1,0) [0|0] "" Vector__XXX
 SG_ ErrorRegisterVoltage : 18|1@1+ (1,0) [0|0] "" Vector__XXX
 SG_ ErrorRegisterCurrent : 17|1@1+ (1,0) [0|0] "" Vector__XXX
 SG_ ErrorRegisterGeneric : 16|1@1+ (1,0) [0|0] "" Vector__XXX
 SG_ ErrorCode : 0|16@1+ (1,0) [0|0] "" Vector__XXX

BO_ 1830 HBGuard_038: 1 Vector__XXX
 SG_ Toggle : 7|1@1+ (1,0) [0|0] "" Vector__XXX
 SG_ State : 0|7@1+ (1,0) [0|0] "" Vector__XXX

BO_ 1446 SSDO_038: 8 Vector__XXX

BO_ 1574 CSDO_038: 8 Vector__XXX

BO_ 166 EMCY_038: 8 Vector__XXX
 SG_ ManufacturerSpecific5 : 56|8@1+ (1,0) [0|0] "" Vector__XXX
 SG_ ManufacturerSpecific4 : 48|8@1+ (1,0) [0|0] "" Vector__XXX
 SG_ ManufacturerSpecific3 : 40|8@1+ (1,0) [0|0] "" Vector__XXX
 SG_ ManufacturerSpecific2 : 32|8@1+ (1,0) [0|0] "" Vector__XXX
 SG_ ManufacturerSpecific1 : 24|8@1+ (1,0) [0|0] "" Vector__XXX
 SG_ ErrorRegisterManufSpecific : 23|1@1+ (1,0) [0|0] "" Vector__XXX
 SG_ ErrorRegisterReserved : 22|1@1+ (1,0) [0|0] "" Vector__XXX
 SG_ ErrorRegisterProfileSpecific : 21|1@1+ (1,0) [0|0] "" Vector__XXX
 SG_ ErrorRegisterCommunication : 20|1@1+ (1,0) [0|0] "" Vector__XXX
 SG_ ErrorRegisterTemperature : 19|1@1+ (1,0) [0|0] "" Vector__XXX
 SG_ ErrorRegisterVoltage : 18|1@1+ (1,0) [0|0] "" Vector__XXX
 SG_ ErrorRegisterCurrent : 17|1@1+ (1,0) [0|0] "" Vector__XXX
 SG_ ErrorRegisterGeneric : 16|1@1+ (1,0) [0|0] "" Vector__XXX
 SG_ ErrorCode : 0|16@1+ (1,0) [0|0] "" Vector__XXX

BO_ 1829 HBGuard_037: 1 Vector__XXX
 SG_ Toggle : 7|1@1+ (1,0) [0|0] "" Vector__XXX
 SG_ State : 0|7@1+ (1,0) [0|0] "" Vector__XXX

BO_ 1445 SSDO_037: 8 Vector__XXX

BO_ 1573 CSDO_037: 8 Vector__XXX

BO_ 165 EMCY_037: 8 Vector__XXX
 SG_ ManufacturerSpecific5 : 56|8@1+ (1,0) [0|0] "" Vector__XXX
 SG_ ManufacturerSpecific4 : 48|8@1+ (1,0) [0|0] "" Vector__XXX
 SG_ ManufacturerSpecific3 : 40|8@1+ (1,0) [0|0] "" Vector__XXX
 SG_ ManufacturerSpecific2 : 32|8@1+ (1,0) [0|0] "" Vector__XXX
 SG_ ManufacturerSpecific1 : 24|8@1+ (1,0) [0|0] "" Vector__XXX
 SG_ ErrorRegisterManufSpecific : 23|1@1+ (1,0) [0|0] "" Vector__XXX
 SG_ ErrorRegisterReserved : 22|1@1+ (1,0) [0|0] "" Vector__XXX
 SG_ ErrorRegisterProfileSpecific : 21|1@1+ (1,0) [0|0] "" Vector__XXX
 SG_ ErrorRegisterCommunication : 20|1@1+ (1,0) [0|0] "" Vector__XXX
 SG_ ErrorRegisterTemperature : 19|1@1+ (1,0) [0|0] "" Vector__XXX
 SG_ ErrorRegisterVoltage : 18|1@1+ (1,0) [0|0] "" Vector__XXX
 SG_ ErrorRegisterCurrent : 17|1@1+ (1,0) [0|0] "" Vector__XXX
 SG_ ErrorRegisterGeneric : 16|1@1+ (1,0) [0|0] "" Vector__XXX
 SG_ ErrorCode : 0|16@1+ (1,0) [0|0] "" Vector__XXX

BO_ 1828 HBGuard_036: 1 Vector__XXX
 SG_ Toggle : 7|1@1+ (1,0) [0|0] "" Vector__XXX
 SG_ State : 0|7@1+ (1,0) [0|0] "" Vector__XXX

BO_ 1444 SSDO_036: 8 Vector__XXX

BO_ 1572 CSDO_036: 8 Vector__XXX

BO_ 164 EMCY_036: 8 Vector__XXX
 SG_ ManufacturerSpecific5 : 56|8@1+ (1,0) [0|0] "" Vector__XXX
 SG_ ManufacturerSpecific4 : 48|8@1+ (1,0) [0|0] "" Vector__XXX
 SG_ ManufacturerSpecific3 : 40|8@1+ (1,0) [0|0] "" Vector__XXX
 SG_ ManufacturerSpecific2 : 32|8@1+ (1,0) [0|0] "" Vector__XXX
 SG_ ManufacturerSpecific1 : 24|8@1+ (1,0) [0|0] "" Vector__XXX
 SG_ ErrorRegisterManufSpecific : 23|1@1+ (1,0) [0|0] "" Vector__XXX
 SG_ ErrorRegisterReserved : 22|1@1+ (1,0) [0|0] "" Vector__XXX
 SG_ ErrorRegisterProfileSpecific : 21|1@1+ (1,0) [0|0] "" Vector__XXX
 SG_ ErrorRegisterCommunication : 20|1@1+ (1,0) [0|0] "" Vector__XXX
 SG_ ErrorRegisterTemperature : 19|1@1+ (1,0) [0|0] "" Vector__XXX
 SG_ ErrorRegisterVoltage : 18|1@1+ (1,0) [0|0] "" Vector__XXX
 SG_ ErrorRegisterCurrent : 17|1@1+ (1,0) [0|0] "" Vector__XXX
 SG_ ErrorRegisterGeneric : 16|1@1+ (1,0) [0|0] "" Vector__XXX
 SG_ ErrorCode : 0|16@1+ (1,0) [0|0] "" Vector__XXX

BO_ 1821 HBGuard_029: 1 Vector__XXX
 SG_ Toggle : 7|1@1+ (1,0) [0|0] "" Vector__XXX
 SG_ State : 0|7@1+ (1,0) [0|0] "" Vector__XXX

BO_ 1437 SSDO_029: 8 Vector__XXX

BO_ 1565 CSDO_029: 8 Vector__XXX

BO_ 157 EMCY_029: 8 Vector__XXX
 SG_ ManufacturerSpecific5 : 56|8@1+ (1,0) [0|0] "" Vector__XXX
 SG_ ManufacturerSpecific4 : 48|8@1+ (1,0) [0|0] "" Vector__XXX
 SG_ ManufacturerSpecific3 : 40|8@1+ (1,0) [0|0] "" Vector__XXX
 SG_ ManufacturerSpecific2 : 32|8@1+ (1,0) [0|0] "" Vector__XXX
 SG_ ManufacturerSpecific1 : 24|8@1+ (1,0) [0|0] "" Vector__XXX
 SG_ ErrorRegisterManufSpecific : 23|1@1+ (1,0) [0|0] "" Vector__XXX
 SG_ ErrorRegisterReserved : 22|1@1+ (1,0) [0|0] "" Vector__XXX
 SG_ ErrorRegisterProfileSpecific : 21|1@1+ (1,0) [0|0] "" Vector__XXX
 SG_ ErrorRegisterCommunication : 20|1@1+ (1,0) [0|0] "" Vector__XXX
 SG_ ErrorRegisterTemperature : 19|1@1+ (1,0) [0|0] "" Vector__XXX
 SG_ ErrorRegisterVoltage : 18|1@1+ (1,0) [0|0] "" Vector__XXX
 SG_ ErrorRegisterCurrent : 17|1@1+ (1,0) [0|0] "" Vector__XXX
 SG_ ErrorRegisterGeneric : 16|1@1+ (1,0) [0|0] "" Vector__XXX
 SG_ ErrorCode : 0|16@1+ (1,0) [0|0] "" Vector__XXX

BO_ 1820 HBGuard_028: 1 Vector__XXX
 SG_ Toggle : 7|1@1+ (1,0) [0|0] "" Vector__XXX
 SG_ State : 0|7@1+ (1,0) [0|0] "" Vector__XXX

BO_ 1436 SSDO_028: 8 Vector__XXX

BO_ 1564 CSDO_028: 8 Vector__XXX

BO_ 156 EMCY_028: 8 Vector__XXX
 SG_ ManufacturerSpecific5 : 56|8@1+ (1,0) [0|0] "" Vector__XXX
 SG_ ManufacturerSpecific4 : 48|8@1+ (1,0) [0|0] "" Vector__XXX
 SG_ ManufacturerSpecific3 : 40|8@1+ (1,0) [0|0] "" Vector__XXX
 SG_ ManufacturerSpecific2 : 32|8@1+ (1,0) [0|0] "" Vector__XXX
 SG_ ManufacturerSpecific1 : 24|8@1+ (1,0) [0|0] "" Vector__XXX
 SG_ ErrorRegisterManufSpecific : 23|1@1+ (1,0) [0|0] "" Vector__XXX
 SG_ ErrorRegisterReserved : 22|1@1+ (1,0) [0|0] "" Vector__XXX
 SG_ ErrorRegisterProfileSpecific : 21|1@1+ (1,0) [0|0] "" Vector__XXX
 SG_ ErrorRegisterCommunication : 20|1@1+ (1,0) [0|0] "" Vector__XXX
 SG_ ErrorRegisterTemperature : 19|1@1+ (1,0) [0|0] "" Vector__XXX
 SG_ ErrorRegisterVoltage : 18|1@1+ (1,0) [0|0] "" Vector__XXX
 SG_ ErrorRegisterCurrent : 17|1@1+ (1,0) [0|0] "" Vector__XXX
 SG_ ErrorRegisterGeneric : 16|1@1+ (1,0) [0|0] "" Vector__XXX
 SG_ ErrorCode : 0|16@1+ (1,0) [0|0] "" Vector__XXX

BO_ 1819 HBGuard_027: 1 Vector__XXX
 SG_ Toggle : 7|1@1+ (1,0) [0|0] "" Vector__XXX
 SG_ State : 0|7@1+ (1,0) [0|0] "" Vector__XXX

BO_ 1435 SSDO_027: 8 Vector__XXX

BO_ 1563 CSDO_027: 8 Vector__XXX

BO_ 155 EMCY_027: 8 Vector__XXX
 SG_ ManufacturerSpecific5 : 56|8@1+ (1,0) [0|0] "" Vector__XXX
 SG_ ManufacturerSpecific4 : 48|8@1+ (1,0) [0|0] "" Vector__XXX
 SG_ ManufacturerSpecific3 : 40|8@1+ (1,0) [0|0] "" Vector__XXX
 SG_ ManufacturerSpecific2 : 32|8@1+ (1,0) [0|0] "" Vector__XXX
 SG_ ManufacturerSpecific1 : 24|8@1+ (1,0) [0|0] "" Vector__XXX
 SG_ ErrorRegisterManufSpecific : 23|1@1+ (1,0) [0|0] "" Vector__XXX
 SG_ ErrorRegisterReserved : 22|1@1+ (1,0) [0|0] "" Vector__XXX
 SG_ ErrorRegisterProfileSpecific : 21|1@1+ (1,0) [0|0] "" Vector__XXX
 SG_ ErrorRegisterCommunication : 20|1@1+ (1,0) [0|0] "" Vector__XXX
 SG_ ErrorRegisterTemperature : 19|1@1+ (1,0) [0|0] "" Vector__XXX
 SG_ ErrorRegisterVoltage : 18|1@1+ (1,0) [0|0] "" Vector__XXX
 SG_ ErrorRegisterCurrent : 17|1@1+ (1,0) [0|0] "" Vector__XXX
 SG_ ErrorRegisterGeneric : 16|1@1+ (1,0) [0|0] "" Vector__XXX
 SG_ ErrorCode : 0|16@1+ (1,0) [0|0] "" Vector__XXX

BO_ 1818 HBGuard_026: 1 Vector__XXX
 SG_ Toggle : 7|1@1+ (1,0) [0|0] "" Vector__XXX
 SG_ State : 0|7@1+ (1,0) [0|0] "" Vector__XXX

BO_ 1434 SSDO_026: 8 Vector__XXX

BO_ 1562 CSDO_026: 8 Vector__XXX

BO_ 154 EMCY_026: 8 Vector__XXX
 SG_ ManufacturerSpecific5 : 56|8@1+ (1,0) [0|0] "" Vector__XXX
 SG_ ManufacturerSpecific4 : 48|8@1+ (1,0) [0|0] "" Vector__XXX
 SG_ ManufacturerSpecific3 : 40|8@1+ (1,0) [0|0] "" Vector__XXX
 SG_ ManufacturerSpecific2 : 32|8@1+ (1,0) [0|0] "" Vector__XXX
 SG_ ManufacturerSpecific1 : 24|8@1+ (1,0) [0|0] "" Vector__XXX
 SG_ ErrorRegisterManufSpecific : 23|1@1+ (1,0) [0|0] "" Vector__XXX
 SG_ ErrorRegisterReserved : 22|1@1+ (1,0) [0|0] "" Vector__XXX
 SG_ ErrorRegisterProfileSpecific : 21|1@1+ (1,0) [0|0] "" Vector__XXX
 SG_ ErrorRegisterCommunication : 20|1@1+ (1,0) [0|0] "" Vector__XXX
 SG_ ErrorRegisterTemperature : 19|1@1+ (1,0) [0|0] "" Vector__XXX
 SG_ ErrorRegisterVoltage : 18|1@1+ (1,0) [0|0] "" Vector__XXX
 SG_ ErrorRegisterCurrent : 17|1@1+ (1,0) [0|0] "" Vector__XXX
 SG_ ErrorRegisterGeneric : 16|1@1+ (1,0) [0|0] "" Vector__XXX
 SG_ ErrorCode : 0|16@1+ (1,0) [0|0] "" Vector__XXX

BO_ 1811 HBGuard_019: 1 Vector__XXX
 SG_ Toggle : 7|1@1+ (1,0) [0|0] "" Vector__XXX
 SG_ State : 0|7@1+ (1,0) [0|0] "" Vector__XXX

BO_ 1427 SSDO_019: 8 Vector__XXX

BO_ 1555 CSDO_019: 8 Vector__XXX

BO_ 147 EMCY_019: 8 Vector__XXX
 SG_ ManufacturerSpecific5 : 56|8@1+ (1,0) [0|0] "" Vector__XXX
 SG_ ManufacturerSpecific4 : 48|8@1+ (1,0) [0|0] "" Vector__XXX
 SG_ ManufacturerSpecific3 : 40|8@1+ (1,0) [0|0] "" Vector__XXX
 SG_ ManufacturerSpecific2 : 32|8@1+ (1,0) [0|0] "" Vector__XXX
 SG_ ManufacturerSpecific1 : 24|8@1+ (1,0) [0|0] "" Vector__XXX
 SG_ ErrorRegisterManufSpecific : 23|1@1+ (1,0) [0|0] "" Vector__XXX
 SG_ ErrorRegisterReserved : 22|1@1+ (1,0) [0|0] "" Vector__XXX
 SG_ ErrorRegisterProfileSpecific : 21|1@1+ (1,0) [0|0] "" Vector__XXX
 SG_ ErrorRegisterCommunication : 20|1@1+ (1,0) [0|0] "" Vector__XXX
 SG_ ErrorRegisterTemperature : 19|1@1+ (1,0) [0|0] "" Vector__XXX
 SG_ ErrorRegisterVoltage : 18|1@1+ (1,0) [0|0] "" Vector__XXX
 SG_ ErrorRegisterCurrent : 17|1@1+ (1,0) [0|0] "" Vector__XXX
 SG_ ErrorRegisterGeneric : 16|1@1+ (1,0) [0|0] "" Vector__XXX
 SG_ ErrorCode : 0|16@1+ (1,0) [0|0] "" Vector__XXX

BO_ 1810 HBGuard_018: 1 Vector__XXX
 SG_ Toggle : 7|1@1+ (1,0) [0|0] "" Vector__XXX
 SG_ State : 0|7@1+ (1,0) [0|0] "" Vector__XXX

BO_ 1426 SSDO_018: 8 Vector__XXX

BO_ 1554 CSDO_018: 8 Vector__XXX

BO_ 146 EMCY_018: 8 Vector__XXX
 SG_ ManufacturerSpecific5 : 56|8@1+ (1,0) [0|0] "" Vector__XXX
 SG_ ManufacturerSpecific4 : 48|8@1+ (1,0) [0|0] "" Vector__XXX
 SG_ ManufacturerSpecific3 : 40|8@1+ (1,0) [0|0] "" Vector__XXX
 SG_ ManufacturerSpecific2 : 32|8@1+ (1,0) [0|0] "" Vector__XXX
 SG_ ManufacturerSpecific1 : 24|8@1+ (1,0) [0|0] "" Vector__XXX
 SG_ ErrorRegisterManufSpecific : 23|1@1+ (1,0) [0|0] "" Vector__XXX
 SG_ ErrorRegisterReserved : 22|1@1+ (1,0) [0|0] "" Vector__XXX
 SG_ ErrorRegisterProfileSpecific : 21|1@1+ (1,0) [0|0] "" Vector__XXX
 SG_ ErrorRegisterCommunication : 20|1@1+ (1,0) [0|0] "" Vector__XXX
 SG_ ErrorRegisterTemperature : 19|1@1+ (1,0) [0|0] "" Vector__XXX
 SG_ ErrorRegisterVoltage : 18|1@1+ (1,0) [0|0] "" Vector__XXX
 SG_ ErrorRegisterCurrent : 17|1@1+ (1,0) [0|0] "" Vector__XXX
 SG_ ErrorRegisterGeneric : 16|1@1+ (1,0) [0|0] "" Vector__XXX
 SG_ ErrorCode : 0|16@1+ (1,0) [0|0] "" Vector__XXX

BO_ 1809 HBGuard_017: 1 Vector__XXX
 SG_ Toggle : 7|1@1+ (1,0) [0|0] "" Vector__XXX
 SG_ State : 0|7@1+ (1,0) [0|0] "" Vector__XXX

BO_ 1425 SSDO_017: 8 Vector__XXX

BO_ 1553 CSDO_017: 8 Vector__XXX

BO_ 145 EMCY_017: 8 Vector__XXX
 SG_ ManufacturerSpecific5 : 56|8@1+ (1,0) [0|0] "" Vector__XXX
 SG_ ManufacturerSpecific4 : 48|8@1+ (1,0) [0|0] "" Vector__XXX
 SG_ ManufacturerSpecific3 : 40|8@1+ (1,0) [0|0] "" Vector__XXX
 SG_ ManufacturerSpecific2 : 32|8@1+ (1,0) [0|0] "" Vector__XXX
 SG_ ManufacturerSpecific1 : 24|8@1+ (1,0) [0|0] "" Vector__XXX
 SG_ ErrorRegisterManufSpecific : 23|1@1+ (1,0) [0|0] "" Vector__XXX
 SG_ ErrorRegisterReserved : 22|1@1+ (1,0) [0|0] "" Vector__XXX
 SG_ ErrorRegisterProfileSpecific : 21|1@1+ (1,0) [0|0] "" Vector__XXX
 SG_ ErrorRegisterCommunication : 20|1@1+ (1,0) [0|0] "" Vector__XXX
 SG_ ErrorRegisterTemperature : 19|1@1+ (1,0) [0|0] "" Vector__XXX
 SG_ ErrorRegisterVoltage : 18|1@1+ (1,0) [0|0] "" Vector__XXX
 SG_ ErrorRegisterCurrent : 17|1@1+ (1,0) [0|0] "" Vector__XXX
 SG_ ErrorRegisterGeneric : 16|1@1+ (1,0) [0|0] "" Vector__XXX
 SG_ ErrorCode : 0|16@1+ (1,0) [0|0] "" Vector__XXX

BO_ 1808 HBGuard_016: 1 Vector__XXX
 SG_ Toggle : 7|1@1+ (1,0) [0|0] "" Vector__XXX
 SG_ State : 0|7@1+ (1,0) [0|0] "" Vector__XXX

BO_ 1424 SSDO_016: 8 Vector__XXX

BO_ 1552 CSDO_016: 8 Vector__XXX

BO_ 144 EMCY_016: 8 Vector__XXX
 SG_ ManufacturerSpecific5 : 56|8@1+ (1,0) [0|0] "" Vector__XXX
 SG_ ManufacturerSpecific4 : 48|8@1+ (1,0) [0|0] "" Vector__XXX
 SG_ ManufacturerSpecific3 : 40|8@1+ (1,0) [0|0] "" Vector__XXX
 SG_ ManufacturerSpecific2 : 32|8@1+ (1,0) [0|0] "" Vector__XXX
 SG_ ManufacturerSpecific1 : 24|8@1+ (1,0) [0|0] "" Vector__XXX
 SG_ ErrorRegisterManufSpecific : 23|1@1+ (1,0) [0|0] "" Vector__XXX
 SG_ ErrorRegisterReserved : 22|1@1+ (1,0) [0|0] "" Vector__XXX
 SG_ ErrorRegisterProfileSpecific : 21|1@1+ (1,0) [0|0] "" Vector__XXX
 SG_ ErrorRegisterCommunication : 20|1@1+ (1,0) [0|0] "" Vector__XXX
 SG_ ErrorRegisterTemperature : 19|1@1+ (1,0) [0|0] "" Vector__XXX
 SG_ ErrorRegisterVoltage : 18|1@1+ (1,0) [0|0] "" Vector__XXX
 SG_ ErrorRegisterCurrent : 17|1@1+ (1,0) [0|0] "" Vector__XXX
 SG_ ErrorRegisterGeneric : 16|1@1+ (1,0) [0|0] "" Vector__XXX
 SG_ ErrorCode : 0|16@1+ (1,0) [0|0] "" Vector__XXX

BO_ 1807 HBGuard_015: 1 Vector__XXX
 SG_ Toggle : 7|1@1+ (1,0) [0|0] "" Vector__XXX
 SG_ State : 0|7@1+ (1,0) [0|0] "" Vector__XXX

BO_ 1423 SSDO_015: 8 Vector__XXX

BO_ 1551 CSDO_015: 8 Vector__XXX

BO_ 143 EMCY_015: 8 Vector__XXX
 SG_ ManufacturerSpecific5 : 56|8@1+ (1,0) [0|0] "" Vector__XXX
 SG_ ManufacturerSpecific4 : 48|8@1+ (1,0) [0|0] "" Vector__XXX
 SG_ ManufacturerSpecific3 : 40|8@1+ (1,0) [0|0] "" Vector__XXX
 SG_ ManufacturerSpecific2 : 32|8@1+ (1,0) [0|0] "" Vector__XXX
 SG_ ManufacturerSpecific1 : 24|8@1+ (1,0) [0|0] "" Vector__XXX
 SG_ ErrorRegisterManufSpecific : 23|1@1+ (1,0) [0|0] "" Vector__XXX
 SG_ ErrorRegisterReserved : 22|1@1+ (1,0) [0|0] "" Vector__XXX
 SG_ ErrorRegisterProfileSpecific : 21|1@1+ (1,0) [0|0] "" Vector__XXX
 SG_ ErrorRegisterCommunication : 20|1@1+ (1,0) [0|0] "" Vector__XXX
 SG_ ErrorRegisterTemperature : 19|1@1+ (1,0) [0|0] "" Vector__XXX
 SG_ ErrorRegisterVoltage : 18|1@1+ (1,0) [0|0] "" Vector__XXX
 SG_ ErrorRegisterCurrent : 17|1@1+ (1,0) [0|0] "" Vector__XXX
 SG_ ErrorRegisterGeneric : 16|1@1+ (1,0) [0|0] "" Vector__XXX
 SG_ ErrorCode : 0|16@1+ (1,0) [0|0] "" Vector__XXX

BO_ 1806 HBGuard_014: 1 Vector__XXX
 SG_ Toggle : 7|1@1+ (1,0) [0|0] "" Vector__XXX
 SG_ State : 0|7@1+ (1,0) [0|0] "" Vector__XXX

BO_ 1422 SSDO_014: 8 Vector__XXX

BO_ 1550 CSDO_014: 8 Vector__XXX

BO_ 142 EMCY_014: 8 Vector__XXX
 SG_ ManufacturerSpecific5 : 56|8@1+ (1,0) [0|0] "" Vector__XXX
 SG_ ManufacturerSpecific4 : 48|8@1+ (1,0) [0|0] "" Vector__XXX
 SG_ ManufacturerSpecific3 : 40|8@1+ (1,0) [0|0] "" Vector__XXX
 SG_ ManufacturerSpecific2 : 32|8@1+ (1,0) [0|0] "" Vector__XXX
 SG_ ManufacturerSpecific1 : 24|8@1+ (1,0) [0|0] "" Vector__XXX
 SG_ ErrorRegisterManufSpecific : 23|1@1+ (1,0) [0|0] "" Vector__XXX
 SG_ ErrorRegisterReserved : 22|1@1+ (1,0) [0|0] "" Vector__XXX
 SG_ ErrorRegisterProfileSpecific : 21|1@1+ (1,0) [0|0] "" Vector__XXX
 SG_ ErrorRegisterCommunication : 20|1@1+ (1,0) [0|0] "" Vector__XXX
 SG_ ErrorRegisterTemperature : 19|1@1+ (1,0) [0|0] "" Vector__XXX
 SG_ ErrorRegisterVoltage : 18|1@1+ (1,0) [0|0] "" Vector__XXX
 SG_ ErrorRegisterCurrent : 17|1@1+ (1,0) [0|0] "" Vector__XXX
 SG_ ErrorRegisterGeneric : 16|1@1+ (1,0) [0|0] "" Vector__XXX
 SG_ ErrorCode : 0|16@1+ (1,0) [0|0] "" Vector__XXX

BO_ 1805 HBGuard_013: 1 Vector__XXX
 SG_ Toggle : 7|1@1+ (1,0) [0|0] "" Vector__XXX
 SG_ State : 0|7@1+ (1,0) [0|0] "" Vector__XXX

BO_ 1421 SSDO_013: 8 Vector__XXX

BO_ 1549 CSDO_013: 8 Vector__XXX

BO_ 141 EMCY_013: 8 Vector__XXX
 SG_ ManufacturerSpecific5 : 56|8@1+ (1,0) [0|0] "" Vector__XXX
 SG_ ManufacturerSpecific4 : 48|8@1+ (1,0) [0|0] "" Vector__XXX
 SG_ ManufacturerSpecific3 : 40|8@1+ (1,0) [0|0] "" Vector__XXX
 SG_ ManufacturerSpecific2 : 32|8@1+ (1,0) [0|0] "" Vector__XXX
 SG_ ManufacturerSpecific1 : 24|8@1+ (1,0) [0|0] "" Vector__XXX
 SG_ ErrorRegisterManufSpecific : 23|1@1+ (1,0) [0|0] "" Vector__XXX
 SG_ ErrorRegisterReserved : 22|1@1+ (1,0) [0|0] "" Vector__XXX
 SG_ ErrorRegisterProfileSpecific : 21|1@1+ (1,0) [0|0] "" Vector__XXX
 SG_ ErrorRegisterCommunication : 20|1@1+ (1,0) [0|0] "" Vector__XXX
 SG_ ErrorRegisterTemperature : 19|1@1+ (1,0) [0|0] "" Vector__XXX
 SG_ ErrorRegisterVoltage : 18|1@1+ (1,0) [0|0] "" Vector__XXX
 SG_ ErrorRegisterCurrent : 17|1@1+ (1,0) [0|0] "" Vector__XXX
 SG_ ErrorRegisterGeneric : 16|1@1+ (1,0) [0|0] "" Vector__XXX
 SG_ ErrorCode : 0|16@1+ (1,0) [0|0] "" Vector__XXX

BO_ 1804 HBGuard_012: 1 Vector__XXX
 SG_ Toggle : 7|1@1+ (1,0) [0|0] "" Vector__XXX
 SG_ State : 0|7@1+ (1,0) [0|0] "" Vector__XXX

BO_ 1420 SSDO_012: 8 Vector__XXX

BO_ 1548 CSDO_012: 8 Vector__XXX

BO_ 140 EMCY_012: 8 Vector__XXX
 SG_ ManufacturerSpecific5 : 56|8@1+ (1,0) [0|0] "" Vector__XXX
 SG_ ManufacturerSpecific4 : 48|8@1+ (1,0) [0|0] "" Vector__XXX
 SG_ ManufacturerSpecific3 : 40|8@1+ (1,0) [0|0] "" Vector__XXX
 SG_ ManufacturerSpecific2 : 32|8@1+ (1,0) [0|0] "" Vector__XXX
 SG_ ManufacturerSpecific1 : 24|8@1+ (1,0) [0|0] "" Vector__XXX
 SG_ ErrorRegisterManufSpecific : 23|1@1+ (1,0) [0|0] "" Vector__XXX
 SG_ ErrorRegisterReserved : 22|1@1+ (1,0) [0|0] "" Vector__XXX
 SG_ ErrorRegisterProfileSpecific : 21|1@1+ (1,0) [0|0] "" Vector__XXX
 SG_ ErrorRegisterCommunication : 20|1@1+ (1,0) [0|0] "" Vector__XXX
 SG_ ErrorRegisterTemperature : 19|1@1+ (1,0) [0|0] "" Vector__XXX
 SG_ ErrorRegisterVoltage : 18|1@1+ (1,0) [0|0] "" Vector__XXX
 SG_ ErrorRegisterCurrent : 17|1@1+ (1,0) [0|0] "" Vector__XXX
 SG_ ErrorRegisterGeneric : 16|1@1+ (1,0) [0|0] "" Vector__XXX
 SG_ ErrorCode : 0|16@1+ (1,0) [0|0] "" Vector__XXX

BO_ 1803 HBGuard_011: 1 Vector__XXX
 SG_ Toggle : 7|1@1+ (1,0) [0|0] "" Vector__XXX
 SG_ State : 0|7@1+ (1,0) [0|0] "" Vector__XXX

BO_ 1419 SSDO_011: 8 Vector__XXX

BO_ 1547 CSDO_011: 8 Vector__XXX

BO_ 139 EMCY_011: 8 Vector__XXX
 SG_ ManufacturerSpecific5 : 56|8@1+ (1,0) [0|0] "" Vector__XXX
 SG_ ManufacturerSpecific4 : 48|8@1+ (1,0) [0|0] "" Vector__XXX
 SG_ ManufacturerSpecific3 : 40|8@1+ (1,0) [0|0] "" Vector__XXX
 SG_ ManufacturerSpecific2 : 32|8@1+ (1,0) [0|0] "" Vector__XXX
 SG_ ManufacturerSpecific1 : 24|8@1+ (1,0) [0|0] "" Vector__XXX
 SG_ ErrorRegisterManufSpecific : 23|1@1+ (1,0) [0|0] "" Vector__XXX
 SG_ ErrorRegisterReserved : 22|1@1+ (1,0) [0|0] "" Vector__XXX
 SG_ ErrorRegisterProfileSpecific : 21|1@1+ (1,0) [0|0] "" Vector__XXX
 SG_ ErrorRegisterCommunication : 20|1@1+ (1,0) [0|0] "" Vector__XXX
 SG_ ErrorRegisterTemperature : 19|1@1+ (1,0) [0|0] "" Vector__XXX
 SG_ ErrorRegisterVoltage : 18|1@1+ (1,0) [0|0] "" Vector__XXX
 SG_ ErrorRegisterCurrent : 17|1@1+ (1,0) [0|0] "" Vector__XXX
 SG_ ErrorRegisterGeneric : 16|1@1+ (1,0) [0|0] "" Vector__XXX
 SG_ ErrorCode : 0|16@1+ (1,0) [0|0] "" Vector__XXX

BO_ 1798 HBGuard_006: 1 Vector__XXX
 SG_ Toggle : 7|1@1+ (1,0) [0|0] "" Vector__XXX
 SG_ State : 0|7@1+ (1,0) [0|0] "" Vector__XXX

BO_ 1414 SSDO_006: 8 Vector__XXX

BO_ 1542 CSDO_006: 8 Vector__XXX

BO_ 134 EMCY_006: 8 Vector__XXX
 SG_ ManufacturerSpecific5 : 56|8@1+ (1,0) [0|0] "" Vector__XXX
 SG_ ManufacturerSpecific4 : 48|8@1+ (1,0) [0|0] "" Vector__XXX
 SG_ ManufacturerSpecific3 : 40|8@1+ (1,0) [0|0] "" Vector__XXX
 SG_ ManufacturerSpecific2 : 32|8@1+ (1,0) [0|0] "" Vector__XXX
 SG_ ManufacturerSpecific1 : 24|8@1+ (1,0) [0|0] "" Vector__XXX
 SG_ ErrorRegisterManufSpecific : 23|1@1+ (1,0) [0|0] "" Vector__XXX
 SG_ ErrorRegisterReserved : 22|1@1+ (1,0) [0|0] "" Vector__XXX
 SG_ ErrorRegisterProfileSpecific : 21|1@1+ (1,0) [0|0] "" Vector__XXX
 SG_ ErrorRegisterCommunication : 20|1@1+ (1,0) [0|0] "" Vector__XXX
 SG_ ErrorRegisterTemperature : 19|1@1+ (1,0) [0|0] "" Vector__XXX
 SG_ ErrorRegisterVoltage : 18|1@1+ (1,0) [0|0] "" Vector__XXX
 SG_ ErrorRegisterCurrent : 17|1@1+ (1,0) [0|0] "" Vector__XXX
 SG_ ErrorRegisterGeneric : 16|1@1+ (1,0) [0|0] "" Vector__XXX
 SG_ ErrorCode : 0|16@1+ (1,0) [0|0] "" Vector__XXX

BO_ 1797 HBGuard_005: 1 Vector__XXX
 SG_ Toggle : 7|1@1+ (1,0) [0|0] "" Vector__XXX
 SG_ State : 0|7@1+ (1,0) [0|0] "" Vector__XXX

BO_ 1413 SSDO_005: 8 Vector__XXX

BO_ 1541 CSDO_005: 8 Vector__XXX

BO_ 133 EMCY_005: 8 Vector__XXX
 SG_ ManufacturerSpecific5 : 56|8@1+ (1,0) [0|0] "" Vector__XXX
 SG_ ManufacturerSpecific4 : 48|8@1+ (1,0) [0|0] "" Vector__XXX
 SG_ ManufacturerSpecific3 : 40|8@1+ (1,0) [0|0] "" Vector__XXX
 SG_ ManufacturerSpecific2 : 32|8@1+ (1,0) [0|0] "" Vector__XXX
 SG_ ManufacturerSpecific1 : 24|8@1+ (1,0) [0|0] "" Vector__XXX
 SG_ ErrorRegisterManufSpecific : 23|1@1+ (1,0) [0|0] "" Vector__XXX
 SG_ ErrorRegisterReserved : 22|1@1+ (1,0) [0|0] "" Vector__XXX
 SG_ ErrorRegisterProfileSpecific : 21|1@1+ (1,0) [0|0] "" Vector__XXX
 SG_ ErrorRegisterCommunication : 20|1@1+ (1,0) [0|0] "" Vector__XXX
 SG_ ErrorRegisterTemperature : 19|1@1+ (1,0) [0|0] "" Vector__XXX
 SG_ ErrorRegisterVoltage : 18|1@1+ (1,0) [0|0] "" Vector__XXX
 SG_ ErrorRegisterCurrent : 17|1@1+ (1,0) [0|0] "" Vector__XXX
 SG_ ErrorRegisterGeneric : 16|1@1+ (1,0) [0|0] "" Vector__XXX
 SG_ ErrorCode : 0|16@1+ (1,0) [0|0] "" Vector__XXX

BO_ 1796 HBGuard_004: 1 Vector__XXX
 SG_ Toggle : 7|1@1+ (1,0) [0|0] "" Vector__XXX
 SG_ State : 0|7@1+ (1,0) [0|0] "" Vector__XXX

BO_ 1412 SSDO_004: 8 Vector__XXX

BO_ 1540 CSDO_004: 8 Vector__XXX

BO_ 132 EMCY_004: 8 Vector__XXX
 SG_ ManufacturerSpecific5 : 56|8@1+ (1,0) [0|0] "" Vector__XXX
 SG_ ManufacturerSpecific4 : 48|8@1+ (1,0) [0|0] "" Vector__XXX
 SG_ ManufacturerSpecific3 : 40|8@1+ (1,0) [0|0] "" Vector__XXX
 SG_ ManufacturerSpecific2 : 32|8@1+ (1,0) [0|0] "" Vector__XXX
 SG_ ManufacturerSpecific1 : 24|8@1+ (1,0) [0|0] "" Vector__XXX
 SG_ ErrorRegisterManufSpecific : 23|1@1+ (1,0) [0|0] "" Vector__XXX
 SG_ ErrorRegisterReserved : 22|1@1+ (1,0) [0|0] "" Vector__XXX
 SG_ ErrorRegisterProfileSpecific : 21|1@1+ (1,0) [0|0] "" Vector__XXX
 SG_ ErrorRegisterCommunication : 20|1@1+ (1,0) [0|0] "" Vector__XXX
 SG_ ErrorRegisterTemperature : 19|1@1+ (1,0) [0|0] "" Vector__XXX
 SG_ ErrorRegisterVoltage : 18|1@1+ (1,0) [0|0] "" Vector__XXX
 SG_ ErrorRegisterCurrent : 17|1@1+ (1,0) [0|0] "" Vector__XXX
 SG_ ErrorRegisterGeneric : 16|1@1+ (1,0) [0|0] "" Vector__XXX
 SG_ ErrorCode : 0|16@1+ (1,0) [0|0] "" Vector__XXX

BO_ 1795 HBGuard_003: 1 Vector__XXX
 SG_ Toggle : 7|1@1+ (1,0) [0|0] "" Vector__XXX
 SG_ State : 0|7@1+ (1,0) [0|0] "" Vector__XXX

BO_ 1411 SSDO_003: 8 Vector__XXX

BO_ 1539 CSDO_003: 8 Vector__XXX

BO_ 131 EMCY_003: 8 Vector__XXX
 SG_ ManufacturerSpecific5 : 56|8@1+ (1,0) [0|0] "" Vector__XXX
 SG_ ManufacturerSpecific4 : 48|8@1+ (1,0) [0|0] "" Vector__XXX
 SG_ ManufacturerSpecific3 : 40|8@1+ (1,0) [0|0] "" Vector__XXX
 SG_ ManufacturerSpecific2 : 32|8@1+ (1,0) [0|0] "" Vector__XXX
 SG_ ManufacturerSpecific1 : 24|8@1+ (1,0) [0|0] "" Vector__XXX
 SG_ ErrorRegisterManufSpecific : 23|1@1+ (1,0) [0|0] "" Vector__XXX
 SG_ ErrorRegisterReserved : 22|1@1+ (1,0) [0|0] "" Vector__XXX
 SG_ ErrorRegisterProfileSpecific : 21|1@1+ (1,0) [0|0] "" Vector__XXX
 SG_ ErrorRegisterCommunication : 20|1@1+ (1,0) [0|0] "" Vector__XXX
 SG_ ErrorRegisterTemperature : 19|1@1+ (1,0) [0|0] "" Vector__XXX
 SG_ ErrorRegisterVoltage : 18|1@1+ (1,0) [0|0] "" Vector__XXX
 SG_ ErrorRegisterCurrent : 17|1@1+ (1,0) [0|0] "" Vector__XXX
 SG_ ErrorRegisterGeneric : 16|1@1+ (1,0) [0|0] "" Vector__XXX
 SG_ ErrorCode : 0|16@1+ (1,0) [0|0] "" Vector__XXX

BO_ 1794 HBGuard_002: 1 Vector__XXX
 SG_ Toggle : 7|1@1+ (1,0) [0|0] "" Vector__XXX
 SG_ State : 0|7@1+ (1,0) [0|0] "" Vector__XXX

BO_ 1410 SSDO_002: 8 Vector__XXX

BO_ 1538 CSDO_002: 8 Vector__XXX

BO_ 130 EMCY_002: 8 Vector__XXX
 SG_ ManufacturerSpecific5 : 56|8@1+ (1,0) [0|0] "" Vector__XXX
 SG_ ManufacturerSpecific4 : 48|8@1+ (1,0) [0|0] "" Vector__XXX
 SG_ ManufacturerSpecific3 : 40|8@1+ (1,0) [0|0] "" Vector__XXX
 SG_ ManufacturerSpecific2 : 32|8@1+ (1,0) [0|0] "" Vector__XXX
 SG_ ManufacturerSpecific1 : 24|8@1+ (1,0) [0|0] "" Vector__XXX
 SG_ ErrorRegisterManufSpecific : 23|1@1+ (1,0) [0|0] "" Vector__XXX
 SG_ ErrorRegisterReserved : 22|1@1+ (1,0) [0|0] "" Vector__XXX
 SG_ ErrorRegisterProfileSpecific : 21|1@1+ (1,0) [0|0] "" Vector__XXX
 SG_ ErrorRegisterCommunication : 20|1@1+ (1,0) [0|0] "" Vector__XXX
 SG_ ErrorRegisterTemperature : 19|1@1+ (1,0) [0|0] "" Vector__XXX
 SG_ ErrorRegisterVoltage : 18|1@1+ (1,0) [0|0] "" Vector__XXX
 SG_ ErrorRegisterCurrent : 17|1@1+ (1,0) [0|0] "" Vector__XXX
 SG_ ErrorRegisterGeneric : 16|1@1+ (1,0) [0|0] "" Vector__XXX
 SG_ ErrorCode : 0|16@1+ (1,0) [0|0] "" Vector__XXX

BO_ 127 RED_IndicateActiveCANLine: 0 Vector__XXX

BO_ 118 FM_ForceReset: 0 Vector__XXX

BO_ 117 FM_ReqMasterCapable: 0 Vector__XXX

BO_ 116 FM_RspMasterCapable: 0 Vector__XXX

BO_ 115 FM_ReqPrioLevel: 0 Vector__XXX

BO_ 114 FM_TriggerTimeSlot: 0 Vector__XXX

BO_ 113 FM_MasterPrioLevel: 2 Vector__XXX
 SG_ FM_NodeID : 8|8@1+ (1,0) [0|0] "" Vector__XXX
 SG_ FM_PrioLevel : 0|8@1+ (1,0) [0|0] "" Vector__XXX

BO_ 256 TIME: 6 Vector__XXX
 SG_ days : 32|16@1+ (1,0) [0|65535] "days" Vector__XXX
 SG_ ms : 0|28@1+ (1,0) [0|86399999] "ms" Vector__XXX

BO_ 128 SYNC: 0 Vector__XXX

BO_ 0 NMTZeroMsg: 2 VirtualNMTMaster
 SG_ Node_ID : 8|8@1+ (1,0) [0|0] "" Vector__XXX
 SG_ CS : 0|8@1+ (1,0) [0|0] "" Vector__XXX

BO_ 1760 DynSDOReq: 0 Vector__XXX

BO_ 2021 LSS_M: 8 Vector__XXX
 SG_ LSS_ID_Number m81 : 8|32@1+ (1,0) [0|0] "" Vector__XXX
 SG_ LSS_BitCheck m81 : 40|8@1+ (1,0) [0|0] "" Vector__XXX
 SG_ LSS_Sub m81 : 48|8@1+ (1,0) [0|0] "" Vector__XXX
 SG_ LSS_Next m81 : 56|8@1+ (1,0) [0|0] "" Vector__XXX
 SG_ LSS_SwitchDelay m21 : 8|16@1+ (1,0) [0|0] "" Vector__XXX
 SG_ LSS_CfgNodeID m17 : 8|8@1+ (1,0) [0|0] "" Vector__XXX
 SG_ LSS_IdentSerialHigh m75 : 8|32@1+ (1,0) [0|0] "" Vector__XXX
 SG_ LSS_IdentSerialLow m74 : 8|32@1+ (1,0) [0|0] "" Vector__XXX
 SG_ LSS_IdentRevisionHigh m73 : 8|32@1+ (1,0) [0|0] "" Vector__XXX
 SG_ LSS_IdentRevisionLow m72 : 8|32@1+ (1,0) [0|0] "" Vector__XXX
 SG_ LSS_IdentProductCode m71 : 8|32@1+ (1,0) [0|0] "" Vector__XXX
 SG_ LSS_IdentVendorId m70 : 8|32@1+ (1,0) [0|0] "" Vector__XXX
 SG_ LSS_TableIndex m19 : 16|8@1+ (1,0) [0|0] "" Vector__XXX
 SG_ LSS_TableSelector m19 : 8|8@1+ (1,0) [0|0] "" Vector__XXX
 SG_ LSS_SwitchSerial m67 : 8|32@1+ (1,0) [0|0] "" Vector__XXX
 SG_ LSS_SwitchRevision m66 : 8|32@1+ (1,0) [0|0] "" Vector__XXX
 SG_ LSS_SwitchProductCode m65 : 8|32@1+ (1,0) [0|0] "" Vector__XXX
 SG_ LSS_SwitchVendorId m64 : 8|32@1+ (1,0) [0|0] "" Vector__XXX
 SG_ LSS_Mode m4 : 8|8@1+ (1,0) [0|0] "" Vector__XXX
 SG_ LSS_M_CS M : 0|8@1+ (1,0) [0|0] "" Vector__XXX

BO_ 2020 LSS_S: 8 Vector__XXX
 SG_ LSS_NodeId m94 : 8|8@1+ (1,0) [0|0] "" Vector__XXX
 SG_ LSS_Serial m93 : 8|32@1+ (1,0) [0|0] "" Vector__XXX
 SG_ LSS_Revision m92 : 8|32@1+ (1,0) [0|0] "" Vector__XXX
 SG_ LSS_ProductId m91 : 8|32@1+ (1,0) [0|0] "" Vector__XXX
 SG_ LSS_VendorId m90 : 8|32@1+ (1,0) [0|0] "" Vector__XXX
 SG_ LSS_StoreCfg_SpecErr m23 : 16|8@1+ (1,0) [0|0] "" Vector__XXX
 SG_ LSS_StoreCfg_ErrCode m23 : 8|8@1+ (1,0) [0|0] "" Vector__XXX
 SG_ LSS_CfgBitTim_SpecErr m19 : 16|8@1+ (1,0) [0|0] "" Vector__XXX
 SG_ LSS_CfgBitTim_ErrCode m19 : 8|8@1+ (1,0) [0|0] "" Vector__XXX
 SG_ LSS_CfgNodeID_SpecErr m17 : 16|8@1+ (1,0) [0|0] "" Vector__XXX
 SG_ LSS_CfgNodeID_ErrCode m17 : 8|8@1+ (1,0) [0|0] "" Vector__XXX
 SG_ LSS_S_CS M : 0|8@1+ (1,0) [0|0] "" Vector__XXX

BO_ 1 GFC: 0 Vector__XXX

BO_ 1281 N1_RPDO3: 0 Vector__XXX

BO_ 1025 N1_RPDO2: 0 Vector__XXX

BO_ 769 N1_RPDO1: 0 Vector__XXX

BO_ 513 N1_RPDO0: 0 Vector__XXX

BO_ 931 N35_TPDO2: 8 BMS_5_1
 SG_ BMS_Voltage_subC : 48|16@1+ (1,0) [0|0] "" Vector__XXX
 SG_ BMS_Voltage_subB : 32|16@1+ (1,0) [0|0] "" Vector__XXX
 SG_ BMS_Voltage_subA : 16|16@1+ (1,0) [0|0] "" Vector__XXX
 SG_ BMS_Voltage_sub9 : 0|16@1+ (1,0) [0|0] "" Vector__XXX

BO_ 675 N35_TPDO1: 8 BMS_5_1
 SG_ BMS_Voltage_sub8 : 48|16@1+ (1,0) [0|0] "" Vector__XXX
 SG_ BMS_Voltage_sub7 : 32|16@1+ (1,0) [0|0] "" Vector__XXX
 SG_ BMS_Voltage_sub6 : 16|16@1+ (1,0) [0|0] "" Vector__XXX
 SG_ BMS_Voltage_sub5 : 0|16@1+ (1,0) [0|0] "" Vector__XXX

BO_ 419 N35_TPDO0: 8 BMS_5_1
 SG_ BMS_Voltage_Cell_4 : 48|16@1+ (1,0) [0|0] "" Vector__XXX
 SG_ BMS_Voltage_Cell_3 : 32|16@1+ (1,0) [0|0] "" Vector__XXX
 SG_ BMS_Voltage_Cell_2 : 16|16@1+ (1,0) [0|0] "" Vector__XXX
 SG_ BMS_Voltage_Cell_1 : 0|16@1+ (1,0) [0|0] "" Vector__XXX

BO_ 930 N34_TPDO2: 8 BMS_4_1
 SG_ BMS_Voltage_subC : 48|16@1+ (1,0) [0|0] "" Vector__XXX
 SG_ BMS_Voltage_subB : 32|16@1+ (1,0) [0|0] "" Vector__XXX
 SG_ BMS_Voltage_subA : 16|16@1+ (1,0) [0|0] "" Vector__XXX
 SG_ BMS_Voltage_sub9 : 0|16@1+ (1,0) [0|0] "" Vector__XXX

BO_ 674 N34_TPDO1: 8 BMS_4_1
 SG_ BMS_Voltage_sub8 : 48|16@1+ (1,0) [0|0] "" Vector__XXX
 SG_ BMS_Voltage_sub7 : 32|16@1+ (1,0) [0|0] "" Vector__XXX
 SG_ BMS_Voltage_sub6 : 16|16@1+ (1,0) [0|0] "" Vector__XXX
 SG_ BMS_Voltage_sub5 : 0|16@1+ (1,0) [0|0] "" Vector__XXX

BO_ 418 N34_TPDO0: 8 BMS_4_1
 SG_ BMS_Voltage_Cell_4 : 48|16@1+ (1,0) [0|0] "" Vector__XXX
 SG_ BMS_Voltage_Cell_3 : 32|16@1+ (1,0) [0|0] "" Vector__XXX
 SG_ BMS_Voltage_Cell_2 : 16|16@1+ (1,0) [0|0] "" Vector__XXX
 SG_ BMS_Voltage_Cell_1 : 0|16@1+ (1,0) [0|0] "" Vector__XXX

BO_ 929 N33_TPDO2: 8 BMS_3_1
 SG_ BMS_Voltage_subC : 48|16@1+ (1,0) [0|0] "" Vector__XXX
 SG_ BMS_Voltage_subB : 32|16@1+ (1,0) [0|0] "" Vector__XXX
 SG_ BMS_Voltage_subA : 16|16@1+ (1,0) [0|0] "" Vector__XXX
 SG_ BMS_Voltage_sub9 : 0|16@1+ (1,0) [0|0] "" Vector__XXX

BO_ 673 N33_TPDO1: 8 BMS_3_1
 SG_ BMS_Voltage_sub8 : 48|16@1+ (1,0) [0|0] "" Vector__XXX
 SG_ BMS_Voltage_sub7 : 32|16@1+ (1,0) [0|0] "" Vector__XXX
 SG_ BMS_Voltage_sub6 : 16|16@1+ (1,0) [0|0] "" Vector__XXX
 SG_ BMS_Voltage_sub5 : 0|16@1+ (1,0) [0|0] "" Vector__XXX

BO_ 417 N33_TPDO0: 8 BMS_3_1
 SG_ BMS_Voltage_Cell_4 : 48|16@1+ (1,0) [0|0] "" Vector__XXX
 SG_ BMS_Voltage_Cell_3 : 32|16@1+ (1,0) [0|0] "" Vector__XXX
 SG_ BMS_Voltage_Cell_2 : 16|16@1+ (1,0) [0|0] "" Vector__XXX
 SG_ BMS_Voltage_Cell_1 : 0|16@1+ (1,0) [0|0] "" Vector__XXX

BO_ 928 N32_TPDO2: 8 BMS_2_1
 SG_ BMS_Voltage_subC : 48|16@1+ (1,0) [0|0] "" Vector__XXX
 SG_ BMS_Voltage_subB : 32|16@1+ (1,0) [0|0] "" Vector__XXX
 SG_ BMS_Voltage_subA : 16|16@1+ (1,0) [0|0] "" Vector__XXX
 SG_ BMS_Voltage_sub9 : 0|16@1+ (1,0) [0|0] "" Vector__XXX

BO_ 672 N32_TPDO1: 8 BMS_2_1
 SG_ BMS_Voltage_sub8 : 48|16@1+ (1,0) [0|0] "" Vector__XXX
 SG_ BMS_Voltage_sub7 : 32|16@1+ (1,0) [0|0] "" Vector__XXX
 SG_ BMS_Voltage_sub6 : 16|16@1+ (1,0) [0|0] "" Vector__XXX
 SG_ BMS_Voltage_sub5 : 0|16@1+ (1,0) [0|0] "" Vector__XXX

BO_ 416 N32_TPDO0: 8 BMS_2_1
 SG_ BMS_Voltage_Cell_4 : 48|16@1+ (1,0) [0|0] "" Vector__XXX
 SG_ BMS_Voltage_Cell_3 : 32|16@1+ (1,0) [0|0] "" Vector__XXX
 SG_ BMS_Voltage_Cell_2 : 16|16@1+ (1,0) [0|0] "" Vector__XXX
 SG_ BMS_Voltage_Cell_1 : 0|16@1+ (1,0) [0|0] "" Vector__XXX

BO_ 927 N31_TPDO2: 8 BMS_1_1
 SG_ BMS_Voltage_subC : 48|16@1+ (1,0) [0|0] "" Vector__XXX
 SG_ BMS_Voltage_subB : 32|16@1+ (1,0) [0|0] "" Vector__XXX
 SG_ BMS_Voltage_subA : 16|16@1+ (1,0) [0|0] "" Vector__XXX
 SG_ BMS_Voltage_sub9 : 0|16@1+ (1,0) [0|0] "" Vector__XXX

BO_ 671 N31_TPDO1: 8 BMS_1_1
 SG_ BMS_Voltage_sub8 : 48|16@1+ (1,0) [0|0] "" Vector__XXX
 SG_ BMS_Voltage_sub7 : 32|16@1+ (1,0) [0|0] "" Vector__XXX
 SG_ BMS_Voltage_sub6 : 16|16@1+ (1,0) [0|0] "" Vector__XXX
 SG_ BMS_Voltage_sub5 : 0|16@1+ (1,0) [0|0] "" Vector__XXX

BO_ 415 N31_TPDO0: 8 BMS_1_1
 SG_ BMS_Voltage_Cell_4 : 48|16@1+ (1,0) [0|0] "" Vector__XXX
 SG_ BMS_Voltage_Cell_3 : 32|16@1+ (1,0) [0|0] "" Vector__XXX
 SG_ BMS_Voltage_Cell_2 : 16|16@1+ (1,0) [0|0] "" Vector__XXX
 SG_ BMS_Voltage_Cell_1 : 0|16@1+ (1,0) [0|0] "" Vector__XXX

BO_ 926 N30_TPDO2: 8 BMS_0_1
 SG_ BMS_Voltage_subC : 48|16@1+ (1,0) [0|0] "" Vector__XXX
 SG_ BMS_Voltage_subB : 32|16@1+ (1,0) [0|0] "" Vector__XXX
 SG_ BMS_Voltage_subA : 16|16@1+ (1,0) [0|0] "" Vector__XXX
 SG_ BMS_Voltage_sub9 : 0|16@1+ (1,0) [0|0] "" Vector__XXX

BO_ 670 N30_TPDO1: 8 BMS_0_1
 SG_ BMS_Voltage_sub8 : 48|16@1+ (1,0) [0|0] "" Vector__XXX
 SG_ BMS_Voltage_sub7 : 32|16@1+ (1,0) [0|0] "" Vector__XXX
 SG_ BMS_Voltage_sub6 : 16|16@1+ (1,0) [0|0] "" Vector__XXX
 SG_ BMS_Voltage_sub5 : 0|16@1+ (1,0) [0|0] "" Vector__XXX

BO_ 414 N30_TPDO0: 8 BMS_0_1
 SG_ BMS_Voltage_Cell_4 : 48|16@1+ (1,0) [0|0] "" Vector__XXX
 SG_ BMS_Voltage_Cell_3 : 32|16@1+ (1,0) [0|0] "" Vector__XXX
 SG_ BMS_Voltage_Cell_2 : 16|16@1+ (1,0) [0|0] "" Vector__XXX
 SG_ BMS_Voltage_Cell_1 : 0|16@1+ (1,0) [0|0] "" Vector__XXX

BO_ 1177 N25_TPDO3: 6 BMS_5_0
 SG_ Battery_Status : 40|8@1+ (1,0) [0|0] "" Vector__XXX
 SG_ Alarm_Status : 32|8@1+ (1,0) [0|0] "" Vector__XXX
 SG_ Alert_C : 24|8@1+ (1,0) [0|0] "" Vector__XXX
 SG_ Alert_B : 16|8@1+ (1,0) [0|0] "" Vector__XXX
 SG_ Alert_A : 8|8@1+ (1,0) [0|0] "" Vector__XXX
 SG_ DC_pos7 : 7|1@1+ (1,0) [0|0] "" Vector__XXX
 SG_ Error : 6|1@1+ (1,0) [0|0] "" Vector__XXX
 SG_ I2C_ERR : 5|1@1+ (1,0) [0|0] "" Vector__XXX
 SG_ I2C_Timeout : 4|1@1+ (1,0) [0|0] "" Vector__XXX
 SG_ DC_pos3 : 3|1@1+ (1,0) [0|0] "" Vector__XXX
 SG_ Over_Temp : 2|1@1+ (1,0) [0|0] "" Vector__XXX
 SG_ BQ_Alarm : 1|1@1+ (1,0) [0|0] "" Vector__XXX
 SG_ BQ_Comm_Err : 0|1@1+ (1,0) [0|0] "" Vector__XXX

BO_ 921 N25_TPDO2: 8 BMS_5_0
 SG_ BMS_Board_Temp_2 : 56|8@1+ (1,0) [0|0] "" Vector__XXX
 SG_ BMS_Board_Temp_1 : 48|8@1+ (1,0) [0|0] "" Vector__XXX
 SG_ BMS_Pack_Temp_6 : 40|8@1+ (1,0) [0|0] "" Vector__XXX
 SG_ BMS_Pack_Temp_5 : 32|8@1+ (1,0) [0|0] "" Vector__XXX
 SG_ BMS_Pack_Temp_4 : 24|8@1+ (1,0) [0|0] "" Vector__XXX
 SG_ BMS_Pack_Temp_3 : 16|8@1+ (1,0) [0|0] "" Vector__XXX
 SG_ BMS_Pack_Temp_2 : 8|8@1+ (1,0) [0|0] "" Vector__XXX
 SG_ BMS_Pack_Temp_1 : 0|8@1+ (1,0) [0|0] "" Vector__XXX

BO_ 665 N25_TPDO1: 8 BMS_5_0
 SG_ BMS_State : 56|8@1+ (1,0) [0|0] "" Vector__XXX
 SG_ BQ_Temp : 48|8@1+ (1,0) [0|0] "" Vector__XXX
 SG_ Max_PT_ID : 40|8@1+ (1,0) [0|0] "" Vector__XXX
 SG_ Max_Pack_Temp : 32|8@1+ (1,0) [0|0] "" Vector__XXX
 SG_ Min_PT_ID : 24|8@1+ (1,0) [0|0] "" Vector__XXX
 SG_ Min_Pack_Temp : 16|8@1+ (1,0) [0|0] "" Vector__XXX
 SG_ BMS_Current : 0|16@1- (1,0) [0|0] "" Vector__XXX

BO_ 409 N25_TPDO0: 8 BMS_5_0
 SG_ BMS_Max_Cell_Voltage_ID : 56|8@1+ (1,0) [0|0] "" Vector__XXX
 SG_ BMS_Max_Cell_Voltage : 40|16@1+ (1,0) [0|0] "" Vector__XXX
 SG_ BMS_Min_Cell_Voltage_ID : 32|8@1+ (1,0) [0|0] "" Vector__XXX
 SG_ BMS_Min_Cell_Voltage : 16|16@1+ (1,0) [0|0] "" Vector__XXX
 SG_ BMS_Battery_Voltage : 0|16@1+ (1,0) [0|0] "" Vector__XXX

BO_ 1176 N24_TPDO3: 6 BMS_4_0
 SG_ Battery_Status : 40|8@1+ (1,0) [0|0] "" Vector__XXX
 SG_ Alarm_Status : 32|8@1+ (1,0) [0|0] "" Vector__XXX
 SG_ Alert_C : 24|8@1+ (1,0) [0|0] "" Vector__XXX
 SG_ Alert_B : 16|8@1+ (1,0) [0|0] "" Vector__XXX
 SG_ Alert_A : 8|8@1+ (1,0) [0|0] "" Vector__XXX
 SG_ DC_pos7 : 7|1@1+ (1,0) [0|0] "" Vector__XXX
 SG_ Error : 6|1@1+ (1,0) [0|0] "" Vector__XXX
 SG_ I2C_ERR : 5|1@1+ (1,0) [0|0] "" Vector__XXX
 SG_ I2C_Timeout : 4|1@1+ (1,0) [0|0] "" Vector__XXX
 SG_ DC_pos3 : 3|1@1+ (1,0) [0|0] "" Vector__XXX
 SG_ Over_Temp : 2|1@1+ (1,0) [0|0] "" Vector__XXX
 SG_ BQ_Alarm : 1|1@1+ (1,0) [0|0] "" Vector__XXX
 SG_ BQ_Comm_Err : 0|1@1+ (1,0) [0|0] "" Vector__XXX

BO_ 920 N24_TPDO2: 8 BMS_4_0
 SG_ BMS_Board_Temp_2 : 56|8@1+ (1,0) [0|0] "" Vector__XXX
 SG_ BMS_Board_Temp_1 : 48|8@1+ (1,0) [0|0] "" Vector__XXX
 SG_ BMS_Pack_Temp_6 : 40|8@1+ (1,0) [0|0] "" Vector__XXX
 SG_ BMS_Pack_Temp_5 : 32|8@1+ (1,0) [0|0] "" Vector__XXX
 SG_ BMS_Pack_Temp_4 : 24|8@1+ (1,0) [0|0] "" Vector__XXX
 SG_ BMS_Pack_Temp_3 : 16|8@1+ (1,0) [0|0] "" Vector__XXX
 SG_ BMS_Pack_Temp_2 : 8|8@1+ (1,0) [0|0] "" Vector__XXX
 SG_ BMS_Pack_Temp_1 : 0|8@1+ (1,0) [0|0] "" Vector__XXX

BO_ 664 N24_TPDO1: 8 BMS_4_0
 SG_ BMS_State : 56|8@1+ (1,0) [0|0] "" Vector__XXX
 SG_ BQ_Temp : 48|8@1+ (1,0) [0|0] "" Vector__XXX
 SG_ Max_PT_ID : 40|8@1+ (1,0) [0|0] "" Vector__XXX
 SG_ Max_Pack_Temp : 32|8@1+ (1,0) [0|0] "" Vector__XXX
 SG_ Min_PT_ID : 24|8@1+ (1,0) [0|0] "" Vector__XXX
 SG_ Min_Pack_Temp : 16|8@1+ (1,0) [0|0] "" Vector__XXX
 SG_ BMS_Current : 0|16@1- (1,0) [0|0] "" Vector__XXX

BO_ 408 N24_TPDO0: 8 BMS_4_0
 SG_ BMS_Max_Cell_Voltage_ID : 56|8@1+ (1,0) [0|0] "" Vector__XXX
 SG_ BMS_Max_Cell_Voltage : 40|16@1+ (1,0) [0|0] "" Vector__XXX
 SG_ BMS_Min_Cell_Voltage_ID : 32|8@1+ (1,0) [0|0] "" Vector__XXX
 SG_ BMS_Min_Cell_Voltage : 16|16@1+ (1,0) [0|0] "" Vector__XXX
 SG_ BMS_Battery_Voltage : 0|16@1+ (1,0) [0|0] "" Vector__XXX

BO_ 1175 N23_TPDO3: 6 BMS_3_0
 SG_ Battery_Status : 40|8@1+ (1,0) [0|0] "" Vector__XXX
 SG_ Alarm_Status : 32|8@1+ (1,0) [0|0] "" Vector__XXX
 SG_ Alert_C : 24|8@1+ (1,0) [0|0] "" Vector__XXX
 SG_ Alert_B : 16|8@1+ (1,0) [0|0] "" Vector__XXX
 SG_ Alert_A : 8|8@1+ (1,0) [0|0] "" Vector__XXX
 SG_ DC_pos7 : 7|1@1+ (1,0) [0|0] "" Vector__XXX
 SG_ Error : 6|1@1+ (1,0) [0|0] "" Vector__XXX
 SG_ I2C_ERR : 5|1@1+ (1,0) [0|0] "" Vector__XXX
 SG_ I2C_Timeout : 4|1@1+ (1,0) [0|0] "" Vector__XXX
 SG_ DC_pos3 : 3|1@1+ (1,0) [0|0] "" Vector__XXX
 SG_ Over_Temp : 2|1@1+ (1,0) [0|0] "" Vector__XXX
 SG_ BQ_Alarm : 1|1@1+ (1,0) [0|0] "" Vector__XXX
 SG_ BQ_Comm_Err : 0|1@1+ (1,0) [0|0] "" Vector__XXX

BO_ 919 N23_TPDO2: 8 BMS_3_0
 SG_ BMS_Board_Temp_2 : 56|8@1+ (1,0) [0|0] "" Vector__XXX
 SG_ BMS_Board_Temp_1 : 48|8@1+ (1,0) [0|0] "" Vector__XXX
 SG_ BMS_Pack_Temp_6 : 40|8@1+ (1,0) [0|0] "" Vector__XXX
 SG_ BMS_Pack_Temp_5 : 32|8@1+ (1,0) [0|0] "" Vector__XXX
 SG_ BMS_Pack_Temp_4 : 24|8@1+ (1,0) [0|0] "" Vector__XXX
 SG_ BMS_Pack_Temp_3 : 16|8@1+ (1,0) [0|0] "" Vector__XXX
 SG_ BMS_Pack_Temp_2 : 8|8@1+ (1,0) [0|0] "" Vector__XXX
 SG_ BMS_Pack_Temp_1 : 0|8@1+ (1,0) [0|0] "" Vector__XXX

BO_ 663 N23_TPDO1: 8 BMS_3_0
 SG_ BMS_State : 56|8@1+ (1,0) [0|0] "" Vector__XXX
 SG_ BQ_Temp : 48|8@1+ (1,0) [0|0] "" Vector__XXX
 SG_ Max_PT_ID : 40|8@1+ (1,0) [0|0] "" Vector__XXX
 SG_ Max_Pack_Temp : 32|8@1+ (1,0) [0|0] "" Vector__XXX
 SG_ Min_PT_ID : 24|8@1+ (1,0) [0|0] "" Vector__XXX
 SG_ Min_Pack_Temp : 16|8@1+ (1,0) [0|0] "" Vector__XXX
 SG_ BMS_Current : 0|16@1- (1,0) [0|0] "" Vector__XXX

BO_ 407 N23_TPDO0: 8 BMS_3_0
 SG_ BMS_Max_Cell_Voltage_ID : 56|8@1+ (1,0) [0|0] "" Vector__XXX
 SG_ BMS_Max_Cell_Voltage : 40|16@1+ (1,0) [0|0] "" Vector__XXX
 SG_ BMS_Min_Cell_Voltage_ID : 32|8@1+ (1,0) [0|0] "" Vector__XXX
 SG_ BMS_Min_Cell_Voltage : 16|16@1+ (1,0) [0|0] "" Vector__XXX
 SG_ BMS_Battery_Voltage : 0|16@1+ (1,0) [0|0] "" Vector__XXX

BO_ 1174 N22_TPDO3: 6 BMS_2_0
 SG_ Battery_Status : 40|8@1+ (1,0) [0|0] "" Vector__XXX
 SG_ Alarm_Status : 32|8@1+ (1,0) [0|0] "" Vector__XXX
 SG_ Alert_C : 24|8@1+ (1,0) [0|0] "" Vector__XXX
 SG_ Alert_B : 16|8@1+ (1,0) [0|0] "" Vector__XXX
 SG_ Alert_A : 8|8@1+ (1,0) [0|0] "" Vector__XXX
 SG_ DC_pos7 : 7|1@1+ (1,0) [0|0] "" Vector__XXX
 SG_ Error : 6|1@1+ (1,0) [0|0] "" Vector__XXX
 SG_ I2C_ERR : 5|1@1+ (1,0) [0|0] "" Vector__XXX
 SG_ I2C_Timeout : 4|1@1+ (1,0) [0|0] "" Vector__XXX
 SG_ DC_pos3 : 3|1@1+ (1,0) [0|0] "" Vector__XXX
 SG_ Over_Temp : 2|1@1+ (1,0) [0|0] "" Vector__XXX
 SG_ BQ_Alarm : 1|1@1+ (1,0) [0|0] "" Vector__XXX
 SG_ BQ_Comm_Err : 0|1@1+ (1,0) [0|0] "" Vector__XXX

BO_ 918 N22_TPDO2: 8 BMS_2_0
 SG_ BMS_Board_Temp_2 : 56|8@1+ (1,0) [0|0] "" Vector__XXX
 SG_ BMS_Board_Temp_1 : 48|8@1+ (1,0) [0|0] "" Vector__XXX
 SG_ BMS_Pack_Temp_6 : 40|8@1+ (1,0) [0|0] "" Vector__XXX
 SG_ BMS_Pack_Temp_5 : 32|8@1+ (1,0) [0|0] "" Vector__XXX
 SG_ BMS_Pack_Temp_4 : 24|8@1+ (1,0) [0|0] "" Vector__XXX
 SG_ BMS_Pack_Temp_3 : 16|8@1+ (1,0) [0|0] "" Vector__XXX
 SG_ BMS_Pack_Temp_2 : 8|8@1+ (1,0) [0|0] "" Vector__XXX
 SG_ BMS_Pack_Temp_1 : 0|8@1+ (1,0) [0|0] "" Vector__XXX

BO_ 662 N22_TPDO1: 8 BMS_2_0
 SG_ BMS_State : 56|8@1+ (1,0) [0|0] "" Vector__XXX
 SG_ BQ_Temp : 48|8@1+ (1,0) [0|0] "" Vector__XXX
 SG_ Max_PT_ID : 40|8@1+ (1,0) [0|0] "" Vector__XXX
 SG_ Max_Pack_Temp : 32|8@1+ (1,0) [0|0] "" Vector__XXX
 SG_ Min_PT_ID : 24|8@1+ (1,0) [0|0] "" Vector__XXX
 SG_ Min_Pack_Temp : 16|8@1+ (1,0) [0|0] "" Vector__XXX
 SG_ BMS_Current : 0|16@1- (1,0) [0|0] "" Vector__XXX

BO_ 406 N22_TPDO0: 8 BMS_2_0
 SG_ BMS_Max_Cell_Voltage_ID : 56|8@1+ (1,0) [0|0] "" Vector__XXX
 SG_ BMS_Max_Cell_Voltage : 40|16@1+ (1,0) [0|0] "" Vector__XXX
 SG_ BMS_Min_Cell_Voltage_ID : 32|8@1+ (1,0) [0|0] "" Vector__XXX
 SG_ BMS_Min_Cell_Voltage : 16|16@1+ (1,0) [0|0] "" Vector__XXX
 SG_ BMS_Battery_Voltage : 0|16@1+ (1,0) [0|0] "" Vector__XXX

BO_ 1173 N21_TPDO3: 6 BMS_1_0
 SG_ Battery_Status : 40|8@1+ (1,0) [0|0] "" Vector__XXX
 SG_ Alarm_Status : 32|8@1+ (1,0) [0|0] "" Vector__XXX
 SG_ Alert_C : 24|8@1+ (1,0) [0|0] "" Vector__XXX
 SG_ Alert_B : 16|8@1+ (1,0) [0|0] "" Vector__XXX
 SG_ Alert_A : 8|8@1+ (1,0) [0|0] "" Vector__XXX
 SG_ DC_pos7 : 7|1@1+ (1,0) [0|0] "" Vector__XXX
 SG_ Error : 6|1@1+ (1,0) [0|0] "" Vector__XXX
 SG_ I2C_ERR : 5|1@1+ (1,0) [0|0] "" Vector__XXX
 SG_ I2C_Timeout : 4|1@1+ (1,0) [0|0] "" Vector__XXX
 SG_ DC_pos3 : 3|1@1+ (1,0) [0|0] "" Vector__XXX
 SG_ Over_Temp : 2|1@1+ (1,0) [0|0] "" Vector__XXX
 SG_ BQ_Alarm : 1|1@1+ (1,0) [0|0] "" Vector__XXX
 SG_ BQ_Comm_Err : 0|1@1+ (1,0) [0|0] "" Vector__XXX

BO_ 917 N21_TPDO2: 8 BMS_1_0
 SG_ BMS_Board_Temp_2 : 56|8@1+ (1,0) [0|0] "" Vector__XXX
 SG_ BMS_Board_Temp_1 : 48|8@1+ (1,0) [0|0] "" Vector__XXX
 SG_ BMS_Pack_Temp_6 : 40|8@1+ (1,0) [0|0] "" Vector__XXX
 SG_ BMS_Pack_Temp_5 : 32|8@1+ (1,0) [0|0] "" Vector__XXX
 SG_ BMS_Pack_Temp_4 : 24|8@1+ (1,0) [0|0] "" Vector__XXX
 SG_ BMS_Pack_Temp_3 : 16|8@1+ (1,0) [0|0] "" Vector__XXX
 SG_ BMS_Pack_Temp_2 : 8|8@1+ (1,0) [0|0] "" Vector__XXX
 SG_ BMS_Pack_Temp_1 : 0|8@1+ (1,0) [0|0] "" Vector__XXX

BO_ 661 N21_TPDO1: 8 BMS_1_0
 SG_ BMS_State : 56|8@1+ (1,0) [0|0] "" Vector__XXX
 SG_ BQ_Temp : 48|8@1+ (1,0) [0|0] "" Vector__XXX
 SG_ Max_PT_ID : 40|8@1+ (1,0) [0|0] "" Vector__XXX
 SG_ Max_Pack_Temp : 32|8@1+ (1,0) [0|0] "" Vector__XXX
 SG_ Min_PT_ID : 24|8@1+ (1,0) [0|0] "" Vector__XXX
 SG_ Min_Pack_Temp : 16|8@1+ (1,0) [0|0] "" Vector__XXX
 SG_ BMS_Current : 0|16@1- (1,0) [0|0] "" Vector__XXX

BO_ 405 N21_TPDO0: 8 BMS_1_0
 SG_ BMS_Max_Cell_Voltage_ID : 56|8@1+ (1,0) [0|0] "" Vector__XXX
 SG_ BMS_Max_Cell_Voltage : 40|16@1+ (1,0) [0|0] "" Vector__XXX
 SG_ BMS_Min_Cell_Voltage_ID : 32|8@1+ (1,0) [0|0] "" Vector__XXX
 SG_ BMS_Min_Cell_Voltage : 16|16@1+ (1,0) [0|0] "" Vector__XXX
 SG_ BMS_Battery_Voltage : 0|16@1+ (1,0) [0|0] "" Vector__XXX

BO_ 1172 N20_TPDO3: 6 BMS_0_0
 SG_ Battery_Status : 40|8@1+ (1,0) [0|0] "" Vector__XXX
 SG_ Alarm_Status : 32|8@1+ (1,0) [0|0] "" Vector__XXX
 SG_ Alert_C : 24|8@1+ (1,0) [0|0] "" Vector__XXX
 SG_ Alert_B : 16|8@1+ (1,0) [0|0] "" Vector__XXX
 SG_ Alert_A : 8|8@1+ (1,0) [0|0] "" Vector__XXX
 SG_ DC_pos7 : 7|1@1+ (1,0) [0|0] "" Vector__XXX
 SG_ Error : 6|1@1+ (1,0) [0|0] "" Vector__XXX
 SG_ I2C_ERR : 5|1@1+ (1,0) [0|0] "" Vector__XXX
 SG_ I2C_Timeout : 4|1@1+ (1,0) [0|0] "" Vector__XXX
 SG_ DC_pos3 : 3|1@1+ (1,0) [0|0] "" Vector__XXX
 SG_ Over_Temp : 2|1@1+ (1,0) [0|0] "" Vector__XXX
 SG_ BQ_Alarm : 1|1@1+ (1,0) [0|0] "" Vector__XXX
 SG_ BQ_Comm_Err : 0|1@1+ (1,0) [0|0] "" Vector__XXX

BO_ 916 N20_TPDO2: 8 BMS_0_0
 SG_ BMS_Board_Temp_2 : 56|8@1+ (1,0) [0|0] "" Vector__XXX
 SG_ BMS_Board_Temp_1 : 48|8@1+ (1,0) [0|0] "" Vector__XXX
 SG_ BMS_Pack_Temp_6 : 40|8@1+ (1,0) [0|0] "" Vector__XXX
 SG_ BMS_Pack_Temp_5 : 32|8@1+ (1,0) [0|0] "" Vector__XXX
 SG_ BMS_Pack_Temp_4 : 24|8@1+ (1,0) [0|0] "" Vector__XXX
 SG_ BMS_Pack_Temp_3 : 16|8@1+ (1,0) [0|0] "" Vector__XXX
 SG_ BMS_Pack_Temp_2 : 8|8@1+ (1,0) [0|0] "" Vector__XXX
 SG_ BMS_Pack_Temp_1 : 0|8@1+ (1,0) [0|0] "" Vector__XXX

BO_ 660 N20_TPDO1: 8 BMS_0_0
 SG_ BMS_State : 56|8@1+ (1,0) [0|0] "" Vector__XXX
 SG_ BQ_Temp : 48|8@1+ (1,0) [0|0] "" Vector__XXX
 SG_ Max_PT_ID : 40|8@1+ (1,0) [0|0] "" Vector__XXX
 SG_ Max_Pack_Temp : 32|8@1+ (1,0) [0|0] "" Vector__XXX
 SG_ Min_PT_ID : 24|8@1+ (1,0) [0|0] "" Vector__XXX
 SG_ Min_Pack_Temp : 16|8@1+ (1,0) [0|0] "" Vector__XXX
 SG_ BMS_Current : 0|16@1- (1,0) [0|0] "" Vector__XXX

BO_ 404 N20_TPDO0: 8 BMS_0_0
 SG_ BMS_Max_Cell_Voltage_ID : 56|8@1+ (1,0) [0|0] "" Vector__XXX
 SG_ BMS_Max_Cell_Voltage : 40|16@1+ (1,0) [0|0] "" Vector__XXX
 SG_ BMS_Min_Cell_Voltage_ID : 32|8@1+ (1,0) [0|0] "" Vector__XXX
 SG_ BMS_Min_Cell_Voltage : 16|16@1+ (1,0) [0|0] "" Vector__XXX
 SG_ BMS_Battery_Voltage : 0|16@1+ (1,0) [0|0] "" Vector__XXX

BO_ 905 N9_TPDO2: 8 IMU
 SG_ VECTOR_ACCELEROMETER_Z : 48|16@1- (1,0) [0|0] "" Vector__XXX
 SG_ VECTOR_LINEAR_ACCEL_Z : 32|16@1- (1,0) [0|0] "" Vector__XXX
 SG_ VECTOR_GYROSCOPE_Z : 16|16@1- (1,0) [0|0] "" Vector__XXX
 SG_ VECTOR_EULER_Z : 0|16@1- (1,0) [0|0] "" Vector__XXX

BO_ 649 N9_TPDO1: 8 IMU
 SG_ VECTOR_ACCELEROMETER_Y : 48|16@1- (1,0) [0|0] "" Vector__XXX
 SG_ VECTOR_LINEAR_ACCEL_Y : 32|16@1- (1,0) [0|0] "" Vector__XXX
 SG_ VECTOR_GYROSCOPE_Y : 16|16@1- (1,0) [0|0] "" Vector__XXX
 SG_ VECTOR_EULER_Y : 0|16@1- (1,0) [0|0] "" Vector__XXX

BO_ 393 N9_TPDO0: 8 IMU
 SG_ VECTOR_ACCELEROMETER_X : 48|16@1- (1,0) [0|0] "" Vector__XXX
 SG_ VECTOR_LINEAR_ACCEL_X : 32|16@1- (1,0) [0|0] "" Vector__XXX
 SG_ VECTOR_GYROSCOPE_X : 16|16@1- (1,0) [0|0] "" Vector__XXX
 SG_ VECTOR_EULER_X : 0|16@1- (1,0) [0|0] "" Vector__XXX

BO_ 648 N8_TPDO1: 3 TMS
 SG_ Fan_2_Duty_Cycle : 16|8@1+ (1,0) [0|0] "" Vector__XXX
 SG_ Fan_1_Duty_Cycle : 8|8@1+ (1,0) [0|494967295] "" Vector__XXX
 SG_ Pump_Duty_Cycle : 0|8@1+ (1,0) [0|494967295] "" Vector__XXX

BO_ 392 N8_TPDO0: 8 TMS
 SG_ Temp_Radiator_Fan_1 : 48|16@1+ (1,0) [0|494967295] "" Vector__XXX
 SG_ Temp_Between_Motor_Inverter : 32|16@1+ (1,0) [0|494967295] "" Vector__XXX
 SG_ Temp_Radiator_Fan_2 : 16|16@1+ (1,0) [0|494967295] "" Vector__XXX
 SG_ Temp_TMS_Internal : 0|16@1+ (1,0) [0|494967295] "" Vector__XXX

BO_ 391 N7_TPDO0: 8 TMU
 SG_ Temp_3 : 48|16@1+ (1,0) [0|0] "" Vector__XXX
 SG_ Temp_2 : 32|16@1+ (1,0) [0|0] "" Vector__XXX
 SG_ Temp_1 : 16|16@1+ (1,0) [0|0] "" Vector__XXX
 SG_ Temp_0 : 0|16@1+ (1,0) [0|0] "" Vector__XXX

BO_ 1153 N1_TPDO3: 0 MC

BO_ 897 N1_TPDO2: 0 MC

BO_ 641 N1_TPDO1: 0 MC

BO_ 385 N1_TPDO0: 0 MC

BA_DEF_ BO_  "GenMsgSendType" ENUM  "Cyclic","SendType1","SendType2","SendType3","SendType4","SendType5","SendType6","SendType7","SendType8","SendType9";
BA_DEF_ SG_  "GenSigStartValue" INT 0 0;
BA_DEF_ BO_  "CO_MsgCategory" INT 0 0;
BA_DEF_DEF_  "GenMsgSendType" "(null)";
BA_DEF_DEF_  "GenSigStartValue" 0;
BA_DEF_DEF_  "CO_MsgCategory" 0;
BA_ "CO_MsgCategory" BO_ 208 205;
BA_ "CO_MsgCategory" BO_ 1871 505;
BA_ "CO_MsgCategory" BO_ 1487 410;
BA_ "CO_MsgCategory" BO_ 1615 405;
BA_ "CO_MsgCategory" BO_ 207 205;
BA_ "CO_MsgCategory" BO_ 1870 505;
BA_ "CO_MsgCategory" BO_ 1486 410;
BA_ "CO_MsgCategory" BO_ 1614 405;
BA_ "CO_MsgCategory" BO_ 206 205;
BA_ "CO_MsgCategory" BO_ 1869 505;
BA_ "CO_MsgCategory" BO_ 1485 410;
BA_ "CO_MsgCategory" BO_ 1613 405;
BA_ "CO_MsgCategory" BO_ 205 205;
BA_ "CO_MsgCategory" BO_ 1868 505;
BA_ "CO_MsgCategory" BO_ 1484 410;
BA_ "CO_MsgCategory" BO_ 1612 405;
BA_ "CO_MsgCategory" BO_ 204 205;
BA_ "CO_MsgCategory" BO_ 1867 505;
BA_ "CO_MsgCategory" BO_ 1483 410;
BA_ "CO_MsgCategory" BO_ 1611 405;
BA_ "CO_MsgCategory" BO_ 203 205;
BA_ "CO_MsgCategory" BO_ 1866 505;
BA_ "CO_MsgCategory" BO_ 1482 410;
BA_ "CO_MsgCategory" BO_ 1610 405;
BA_ "CO_MsgCategory" BO_ 202 205;
BA_ "CO_MsgCategory" BO_ 1865 505;
BA_ "CO_MsgCategory" BO_ 1481 410;
BA_ "CO_MsgCategory" BO_ 1609 405;
BA_ "CO_MsgCategory" BO_ 201 205;
BA_ "CO_MsgCategory" BO_ 1864 505;
BA_ "CO_MsgCategory" BO_ 1480 410;
BA_ "CO_MsgCategory" BO_ 1608 405;
BA_ "CO_MsgCategory" BO_ 200 205;
BA_ "CO_MsgCategory" BO_ 1863 505;
BA_ "CO_MsgCategory" BO_ 1479 410;
BA_ "CO_MsgCategory" BO_ 1607 405;
BA_ "CO_MsgCategory" BO_ 199 205;
BA_ "CO_MsgCategory" BO_ 1862 505;
BA_ "CO_MsgCategory" BO_ 1478 410;
BA_ "CO_MsgCategory" BO_ 1606 405;
BA_ "CO_MsgCategory" BO_ 198 205;
BA_ "CO_MsgCategory" BO_ 1861 505;
BA_ "CO_MsgCategory" BO_ 1477 410;
BA_ "CO_MsgCategory" BO_ 1605 405;
BA_ "CO_MsgCategory" BO_ 197 205;
BA_ "CO_MsgCategory" BO_ 1860 505;
BA_ "CO_MsgCategory" BO_ 1476 410;
BA_ "CO_MsgCategory" BO_ 1604 405;
BA_ "CO_MsgCategory" BO_ 196 205;
BA_ "CO_MsgCategory" BO_ 1859 505;
BA_ "CO_MsgCategory" BO_ 1475 410;
BA_ "CO_MsgCategory" BO_ 1603 405;
BA_ "CO_MsgCategory" BO_ 195 205;
BA_ "CO_MsgCategory" BO_ 1858 505;
BA_ "CO_MsgCategory" BO_ 1474 410;
BA_ "CO_MsgCategory" BO_ 1602 405;
BA_ "CO_MsgCategory" BO_ 194 205;
BA_ "CO_MsgCategory" BO_ 1857 505;
BA_ "CO_MsgCategory" BO_ 1473 410;
BA_ "CO_MsgCategory" BO_ 1601 405;
BA_ "CO_MsgCategory" BO_ 193 205;
BA_ "CO_MsgCategory" BO_ 1856 505;
BA_ "CO_MsgCategory" BO_ 1472 410;
BA_ "CO_MsgCategory" BO_ 1600 405;
BA_ "CO_MsgCategory" BO_ 192 205;
BA_ "CO_MsgCategory" BO_ 1855 505;
BA_ "CO_MsgCategory" BO_ 1471 410;
BA_ "CO_MsgCategory" BO_ 1599 405;
BA_ "CO_MsgCategory" BO_ 191 205;
BA_ "CO_MsgCategory" BO_ 1854 505;
BA_ "CO_MsgCategory" BO_ 1470 410;
BA_ "CO_MsgCategory" BO_ 1598 405;
BA_ "CO_MsgCategory" BO_ 190 205;
BA_ "CO_MsgCategory" BO_ 1853 505;
BA_ "CO_MsgCategory" BO_ 1469 410;
BA_ "CO_MsgCategory" BO_ 1597 405;
BA_ "CO_MsgCategory" BO_ 189 205;
BA_ "CO_MsgCategory" BO_ 1852 505;
BA_ "CO_MsgCategory" BO_ 1468 410;
BA_ "CO_MsgCategory" BO_ 1596 405;
BA_ "CO_MsgCategory" BO_ 188 205;
BA_ "CO_MsgCategory" BO_ 1851 505;
BA_ "CO_MsgCategory" BO_ 1467 410;
BA_ "CO_MsgCategory" BO_ 1595 405;
BA_ "CO_MsgCategory" BO_ 187 205;
BA_ "CO_MsgCategory" BO_ 1850 505;
BA_ "CO_MsgCategory" BO_ 1466 410;
BA_ "CO_MsgCategory" BO_ 1594 405;
BA_ "CO_MsgCategory" BO_ 186 205;
BA_ "CO_MsgCategory" BO_ 1849 505;
BA_ "CO_MsgCategory" BO_ 1465 410;
BA_ "CO_MsgCategory" BO_ 1593 405;
BA_ "CO_MsgCategory" BO_ 185 205;
BA_ "CO_MsgCategory" BO_ 1848 505;
BA_ "CO_MsgCategory" BO_ 1464 410;
BA_ "CO_MsgCategory" BO_ 1592 405;
BA_ "CO_MsgCategory" BO_ 184 205;
BA_ "CO_MsgCategory" BO_ 1847 505;
BA_ "CO_MsgCategory" BO_ 1463 410;
BA_ "CO_MsgCategory" BO_ 1591 405;
BA_ "CO_MsgCategory" BO_ 183 205;
BA_ "CO_MsgCategory" BO_ 1846 505;
BA_ "CO_MsgCategory" BO_ 1462 410;
BA_ "CO_MsgCategory" BO_ 1590 405;
BA_ "CO_MsgCategory" BO_ 182 205;
BA_ "CO_MsgCategory" BO_ 1845 505;
BA_ "CO_MsgCategory" BO_ 1461 410;
BA_ "CO_MsgCategory" BO_ 1589 405;
BA_ "CO_MsgCategory" BO_ 181 205;
BA_ "CO_MsgCategory" BO_ 1844 505;
BA_ "CO_MsgCategory" BO_ 1460 410;
BA_ "CO_MsgCategory" BO_ 1588 405;
BA_ "CO_MsgCategory" BO_ 180 205;
BA_ "CO_MsgCategory" BO_ 1843 505;
BA_ "CO_MsgCategory" BO_ 1459 410;
BA_ "CO_MsgCategory" BO_ 1587 405;
BA_ "CO_MsgCategory" BO_ 179 205;
BA_ "CO_MsgCategory" BO_ 1842 505;
BA_ "CO_MsgCategory" BO_ 1458 410;
BA_ "CO_MsgCategory" BO_ 1586 405;
BA_ "CO_MsgCategory" BO_ 178 205;
BA_ "CO_MsgCategory" BO_ 1841 505;
BA_ "CO_MsgCategory" BO_ 1457 410;
BA_ "CO_MsgCategory" BO_ 1585 405;
BA_ "CO_MsgCategory" BO_ 177 205;
BA_ "CO_MsgCategory" BO_ 1840 505;
BA_ "CO_MsgCategory" BO_ 1456 410;
BA_ "CO_MsgCategory" BO_ 1584 405;
BA_ "CO_MsgCategory" BO_ 176 205;
BA_ "CO_MsgCategory" BO_ 1839 505;
BA_ "CO_MsgCategory" BO_ 1455 410;
BA_ "CO_MsgCategory" BO_ 1583 405;
BA_ "CO_MsgCategory" BO_ 175 205;
BA_ "CO_MsgCategory" BO_ 1838 505;
BA_ "CO_MsgCategory" BO_ 1454 410;
BA_ "CO_MsgCategory" BO_ 1582 405;
BA_ "CO_MsgCategory" BO_ 174 205;
BA_ "CO_MsgCategory" BO_ 1837 505;
BA_ "CO_MsgCategory" BO_ 1453 410;
BA_ "CO_MsgCategory" BO_ 1581 405;
BA_ "CO_MsgCategory" BO_ 173 205;
BA_ "CO_MsgCategory" BO_ 1836 505;
BA_ "CO_MsgCategory" BO_ 1452 410;
BA_ "CO_MsgCategory" BO_ 1580 405;
BA_ "CO_MsgCategory" BO_ 172 205;
BA_ "CO_MsgCategory" BO_ 1835 505;
BA_ "CO_MsgCategory" BO_ 1451 410;
BA_ "CO_MsgCategory" BO_ 1579 405;
BA_ "CO_MsgCategory" BO_ 171 205;
BA_ "CO_MsgCategory" BO_ 1834 505;
BA_ "CO_MsgCategory" BO_ 1450 410;
BA_ "CO_MsgCategory" BO_ 1578 405;
BA_ "CO_MsgCategory" BO_ 170 205;
BA_ "CO_MsgCategory" BO_ 1833 505;
BA_ "CO_MsgCategory" BO_ 1449 410;
BA_ "CO_MsgCategory" BO_ 1577 405;
BA_ "CO_MsgCategory" BO_ 169 205;
BA_ "CO_MsgCategory" BO_ 1832 505;
BA_ "CO_MsgCategory" BO_ 1448 410;
BA_ "CO_MsgCategory" BO_ 1576 405;
BA_ "CO_MsgCategory" BO_ 168 205;
BA_ "CO_MsgCategory" BO_ 1831 505;
BA_ "CO_MsgCategory" BO_ 1447 410;
BA_ "CO_MsgCategory" BO_ 1575 405;
BA_ "CO_MsgCategory" BO_ 167 205;
BA_ "CO_MsgCategory" BO_ 1830 505;
BA_ "CO_MsgCategory" BO_ 1446 410;
BA_ "CO_MsgCategory" BO_ 1574 405;
BA_ "CO_MsgCategory" BO_ 166 205;
BA_ "CO_MsgCategory" BO_ 1829 505;
BA_ "CO_MsgCategory" BO_ 1445 410;
BA_ "CO_MsgCategory" BO_ 1573 405;
BA_ "CO_MsgCategory" BO_ 165 205;
BA_ "CO_MsgCategory" BO_ 1828 505;
BA_ "CO_MsgCategory" BO_ 1444 410;
BA_ "CO_MsgCategory" BO_ 1572 405;
BA_ "CO_MsgCategory" BO_ 164 205;
BA_ "CO_MsgCategory" BO_ 1821 505;
BA_ "CO_MsgCategory" BO_ 1437 410;
BA_ "CO_MsgCategory" BO_ 1565 405;
BA_ "CO_MsgCategory" BO_ 157 205;
BA_ "CO_MsgCategory" BO_ 1820 505;
BA_ "CO_MsgCategory" BO_ 1436 410;
BA_ "CO_MsgCategory" BO_ 1564 405;
BA_ "CO_MsgCategory" BO_ 156 205;
BA_ "CO_MsgCategory" BO_ 1819 505;
BA_ "CO_MsgCategory" BO_ 1435 410;
BA_ "CO_MsgCategory" BO_ 1563 405;
BA_ "CO_MsgCategory" BO_ 155 205;
BA_ "CO_MsgCategory" BO_ 1818 505;
BA_ "CO_MsgCategory" BO_ 1434 410;
BA_ "CO_MsgCategory" BO_ 1562 405;
BA_ "CO_MsgCategory" BO_ 154 205;
BA_ "CO_MsgCategory" BO_ 1811 505;
BA_ "CO_MsgCategory" BO_ 1427 410;
BA_ "CO_MsgCategory" BO_ 1555 405;
BA_ "CO_MsgCategory" BO_ 147 205;
BA_ "CO_MsgCategory" BO_ 1810 505;
BA_ "CO_MsgCategory" BO_ 1426 410;
BA_ "CO_MsgCategory" BO_ 1554 405;
BA_ "CO_MsgCategory" BO_ 146 205;
BA_ "CO_MsgCategory" BO_ 1809 505;
BA_ "CO_MsgCategory" BO_ 1425 410;
BA_ "CO_MsgCategory" BO_ 1553 405;
BA_ "CO_MsgCategory" BO_ 145 205;
BA_ "CO_MsgCategory" BO_ 1808 505;
BA_ "CO_MsgCategory" BO_ 1424 410;
BA_ "CO_MsgCategory" BO_ 1552 405;
BA_ "CO_MsgCategory" BO_ 144 205;
BA_ "CO_MsgCategory" BO_ 1807 505;
BA_ "CO_MsgCategory" BO_ 1423 410;
BA_ "CO_MsgCategory" BO_ 1551 405;
BA_ "CO_MsgCategory" BO_ 143 205;
BA_ "CO_MsgCategory" BO_ 1806 505;
BA_ "CO_MsgCategory" BO_ 1422 410;
BA_ "CO_MsgCategory" BO_ 1550 405;
BA_ "CO_MsgCategory" BO_ 142 205;
BA_ "CO_MsgCategory" BO_ 1805 505;
BA_ "CO_MsgCategory" BO_ 1421 410;
BA_ "CO_MsgCategory" BO_ 1549 405;
BA_ "CO_MsgCategory" BO_ 141 205;
BA_ "CO_MsgCategory" BO_ 1804 505;
BA_ "CO_MsgCategory" BO_ 1420 410;
BA_ "CO_MsgCategory" BO_ 1548 405;
BA_ "CO_MsgCategory" BO_ 140 205;
BA_ "CO_MsgCategory" BO_ 1803 505;
BA_ "CO_MsgCategory" BO_ 1419 410;
BA_ "CO_MsgCategory" BO_ 1547 405;
BA_ "CO_MsgCategory" BO_ 139 205;
BA_ "CO_MsgCategory" BO_ 1798 505;
BA_ "CO_MsgCategory" BO_ 1414 410;
BA_ "CO_MsgCategory" BO_ 1542 405;
BA_ "CO_MsgCategory" BO_ 134 205;
BA_ "CO_MsgCategory" BO_ 1797 505;
BA_ "CO_MsgCategory" BO_ 1413 410;
BA_ "CO_MsgCategory" BO_ 1541 405;
BA_ "CO_MsgCategory" BO_ 133 205;
BA_ "CO_MsgCategory" BO_ 1796 505;
BA_ "CO_MsgCategory" BO_ 1412 410;
BA_ "CO_MsgCategory" BO_ 1540 405;
BA_ "CO_MsgCategory" BO_ 132 205;
BA_ "CO_MsgCategory" BO_ 1795 505;
BA_ "CO_MsgCategory" BO_ 1411 410;
BA_ "CO_MsgCategory" BO_ 1539 405;
BA_ "CO_MsgCategory" BO_ 131 205;
BA_ "CO_MsgCategory" BO_ 1794 505;
BA_ "CO_MsgCategory" BO_ 1410 410;
BA_ "CO_MsgCategory" BO_ 1538 405;
BA_ "CO_MsgCategory" BO_ 130 205;
BA_ "CO_MsgCategory" BO_ 256 115;
BA_ "CO_MsgCategory" BO_ 128 110;
BA_ "CO_MsgCategory" BO_ 0 105;
BA_ "CO_MsgCategory" BO_ 2021 610;
BA_ "CO_MsgCategory" BO_ 2020 605;
BA_ "CO_MsgCategory" BO_ 1 705;
BA_ "CO_MsgCategory" BO_ 1281 340;
BA_ "CO_MsgCategory" BO_ 1025 330;
BA_ "CO_MsgCategory" BO_ 769 320;
BA_ "CO_MsgCategory" BO_ 513 310;
BA_ "CO_MsgCategory" BO_ 931 325;
BA_ "CO_MsgCategory" BO_ 675 315;
BA_ "CO_MsgCategory" BO_ 419 305;
BA_ "CO_MsgCategory" BO_ 930 325;
BA_ "CO_MsgCategory" BO_ 674 315;
BA_ "CO_MsgCategory" BO_ 418 305;
BA_ "CO_MsgCategory" BO_ 929 325;
BA_ "CO_MsgCategory" BO_ 673 315;
BA_ "CO_MsgCategory" BO_ 417 305;
BA_ "CO_MsgCategory" BO_ 928 325;
BA_ "CO_MsgCategory" BO_ 672 315;
BA_ "CO_MsgCategory" BO_ 416 305;
BA_ "CO_MsgCategory" BO_ 927 325;
BA_ "CO_MsgCategory" BO_ 671 315;
BA_ "CO_MsgCategory" BO_ 415 305;
BA_ "CO_MsgCategory" BO_ 926 325;
BA_ "CO_MsgCategory" BO_ 670 315;
BA_ "CO_MsgCategory" BO_ 414 305;
BA_ "CO_MsgCategory" BO_ 1177 335;
BA_ "CO_MsgCategory" BO_ 921 325;
BA_ "CO_MsgCategory" BO_ 665 315;
BA_ "CO_MsgCategory" BO_ 409 305;
BA_ "CO_MsgCategory" BO_ 1176 335;
BA_ "CO_MsgCategory" BO_ 920 325;
BA_ "CO_MsgCategory" BO_ 664 315;
BA_ "CO_MsgCategory" BO_ 408 305;
BA_ "CO_MsgCategory" BO_ 1175 335;
BA_ "CO_MsgCategory" BO_ 919 325;
BA_ "CO_MsgCategory" BO_ 663 315;
BA_ "CO_MsgCategory" BO_ 407 305;
BA_ "CO_MsgCategory" BO_ 1174 335;
BA_ "CO_MsgCategory" BO_ 918 325;
BA_ "CO_MsgCategory" BO_ 662 315;
BA_ "CO_MsgCategory" BO_ 406 305;
BA_ "CO_MsgCategory" BO_ 1173 335;
BA_ "CO_MsgCategory" BO_ 917 325;
BA_ "CO_MsgCategory" BO_ 661 315;
BA_ "CO_MsgCategory" BO_ 405 305;
BA_ "CO_MsgCategory" BO_ 1172 335;
BA_ "CO_MsgCategory" BO_ 916 325;
BA_ "CO_MsgCategory" BO_ 660 315;
BA_ "CO_MsgCategory" BO_ 404 305;
BA_ "CO_MsgCategory" BO_ 905 325;
BA_ "CO_MsgCategory" BO_ 649 315;
BA_ "CO_MsgCategory" BO_ 393 305;
BA_ "CO_MsgCategory" BO_ 648 315;
BA_ "CO_MsgCategory" BO_ 392 305;
BA_ "CO_MsgCategory" BO_ 391 305;
BA_ "CO_MsgCategory" BO_ 1153 335;
BA_ "CO_MsgCategory" BO_ 897 325;
BA_ "CO_MsgCategory" BO_ 641 315;
BA_ "CO_MsgCategory" BO_ 385 305;
VAL_ 1871 State 127 "PreOperational" 5 "Operational" 4 "Stopped" 0 "Bootup" ;
VAL_ 1870 State 127 "PreOperational" 5 "Operational" 4 "Stopped" 0 "Bootup" ;
VAL_ 1869 State 127 "PreOperational" 5 "Operational" 4 "Stopped" 0 "Bootup" ;
VAL_ 1868 State 127 "PreOperational" 5 "Operational" 4 "Stopped" 0 "Bootup" ;
VAL_ 1867 State 127 "PreOperational" 5 "Operational" 4 "Stopped" 0 "Bootup" ;
VAL_ 1866 State 127 "PreOperational" 5 "Operational" 4 "Stopped" 0 "Bootup" ;
VAL_ 1865 State 127 "PreOperational" 5 "Operational" 4 "Stopped" 0 "Bootup" ;
VAL_ 1864 State 127 "PreOperational" 5 "Operational" 4 "Stopped" 0 "Bootup" ;
VAL_ 1863 State 127 "PreOperational" 5 "Operational" 4 "Stopped" 0 "Bootup" ;
VAL_ 1862 State 127 "PreOperational" 5 "Operational" 4 "Stopped" 0 "Bootup" ;
VAL_ 1861 State 127 "PreOperational" 5 "Operational" 4 "Stopped" 0 "Bootup" ;
VAL_ 1860 State 127 "PreOperational" 5 "Operational" 4 "Stopped" 0 "Bootup" ;
VAL_ 1859 State 127 "PreOperational" 5 "Operational" 4 "Stopped" 0 "Bootup" ;
VAL_ 1858 State 127 "PreOperational" 5 "Operational" 4 "Stopped" 0 "Bootup" ;
VAL_ 1857 State 127 "PreOperational" 5 "Operational" 4 "Stopped" 0 "Bootup" ;
VAL_ 1856 State 127 "PreOperational" 5 "Operational" 4 "Stopped" 0 "Bootup" ;
VAL_ 1855 State 127 "PreOperational" 5 "Operational" 4 "Stopped" 0 "Bootup" ;
VAL_ 1854 State 127 "PreOperational" 5 "Operational" 4 "Stopped" 0 "Bootup" ;
VAL_ 1853 State 127 "PreOperational" 5 "Operational" 4 "Stopped" 0 "Bootup" ;
VAL_ 1852 State 127 "PreOperational" 5 "Operational" 4 "Stopped" 0 "Bootup" ;
VAL_ 1851 State 127 "PreOperational" 5 "Operational" 4 "Stopped" 0 "Bootup" ;
VAL_ 1850 State 127 "PreOperational" 5 "Operational" 4 "Stopped" 0 "Bootup" ;
VAL_ 1849 State 127 "PreOperational" 5 "Operational" 4 "Stopped" 0 "Bootup" ;
VAL_ 1848 State 127 "PreOperational" 5 "Operational" 4 "Stopped" 0 "Bootup" ;
VAL_ 1847 State 127 "PreOperational" 5 "Operational" 4 "Stopped" 0 "Bootup" ;
VAL_ 1846 State 127 "PreOperational" 5 "Operational" 4 "Stopped" 0 "Bootup" ;
VAL_ 1845 State 127 "PreOperational" 5 "Operational" 4 "Stopped" 0 "Bootup" ;
VAL_ 1844 State 127 "PreOperational" 5 "Operational" 4 "Stopped" 0 "Bootup" ;
VAL_ 1843 State 127 "PreOperational" 5 "Operational" 4 "Stopped" 0 "Bootup" ;
VAL_ 1842 State 127 "PreOperational" 5 "Operational" 4 "Stopped" 0 "Bootup" ;
VAL_ 1841 State 127 "PreOperational" 5 "Operational" 4 "Stopped" 0 "Bootup" ;
VAL_ 1840 State 127 "PreOperational" 5 "Operational" 4 "Stopped" 0 "Bootup" ;
VAL_ 1839 State 127 "PreOperational" 5 "Operational" 4 "Stopped" 0 "Bootup" ;
VAL_ 1838 State 127 "PreOperational" 5 "Operational" 4 "Stopped" 0 "Bootup" ;
VAL_ 1837 State 127 "PreOperational" 5 "Operational" 4 "Stopped" 0 "Bootup" ;
VAL_ 1836 State 127 "PreOperational" 5 "Operational" 4 "Stopped" 0 "Bootup" ;
VAL_ 1835 State 127 "PreOperational" 5 "Operational" 4 "Stopped" 0 "Bootup" ;
VAL_ 1834 State 127 "PreOperational" 5 "Operational" 4 "Stopped" 0 "Bootup" ;
VAL_ 1833 State 127 "PreOperational" 5 "Operational" 4 "Stopped" 0 "Bootup" ;
VAL_ 1832 State 127 "PreOperational" 5 "Operational" 4 "Stopped" 0 "Bootup" ;
VAL_ 1831 State 127 "PreOperational" 5 "Operational" 4 "Stopped" 0 "Bootup" ;
VAL_ 1830 State 127 "PreOperational" 5 "Operational" 4 "Stopped" 0 "Bootup" ;
VAL_ 1829 State 127 "PreOperational" 5 "Operational" 4 "Stopped" 0 "Bootup" ;
VAL_ 1828 State 127 "PreOperational" 5 "Operational" 4 "Stopped" 0 "Bootup" ;
VAL_ 1821 State 127 "PreOperational" 5 "Operational" 4 "Stopped" 0 "Bootup" ;
VAL_ 1820 State 127 "PreOperational" 5 "Operational" 4 "Stopped" 0 "Bootup" ;
VAL_ 1819 State 127 "PreOperational" 5 "Operational" 4 "Stopped" 0 "Bootup" ;
VAL_ 1818 State 127 "PreOperational" 5 "Operational" 4 "Stopped" 0 "Bootup" ;
VAL_ 1811 State 127 "PreOperational" 5 "Operational" 4 "Stopped" 0 "Bootup" ;
VAL_ 1810 State 127 "PreOperational" 5 "Operational" 4 "Stopped" 0 "Bootup" ;
VAL_ 1809 State 127 "PreOperational" 5 "Operational" 4 "Stopped" 0 "Bootup" ;
VAL_ 1808 State 127 "PreOperational" 5 "Operational" 4 "Stopped" 0 "Bootup" ;
VAL_ 1807 State 127 "PreOperational" 5 "Operational" 4 "Stopped" 0 "Bootup" ;
VAL_ 1806 State 127 "PreOperational" 5 "Operational" 4 "Stopped" 0 "Bootup" ;
VAL_ 1805 State 127 "PreOperational" 5 "Operational" 4 "Stopped" 0 "Bootup" ;
VAL_ 1804 State 127 "PreOperational" 5 "Operational" 4 "Stopped" 0 "Bootup" ;
VAL_ 1803 State 127 "PreOperational" 5 "Operational" 4 "Stopped" 0 "Bootup" ;
VAL_ 1798 State 127 "PreOperational" 5 "Operational" 4 "Stopped" 0 "Bootup" ;
VAL_ 1797 State 127 "PreOperational" 5 "Operational" 4 "Stopped" 0 "Bootup" ;
VAL_ 1796 State 127 "PreOperational" 5 "Operational" 4 "Stopped" 0 "Bootup" ;
VAL_ 1795 State 127 "PreOperational" 5 "Operational" 4 "Stopped" 0 "Bootup" ;
VAL_ 1794 State 127 "PreOperational" 5 "Operational" 4 "Stopped" 0 "Bootup" ;
VAL_ 0 Node_ID 35 "BMS_5_1" 34 "BMS_4_1" 33 "BMS_3_1" 32 "BMS_2_1" 31 "BMS_1_1" 30 "BMS_0_1" 25 "BMS_5_0" 24 "BMS_4_0" 23 "BMS_3_0" 22 "BMS_2_0" 21 "BMS_1_0" 20 "BMS_0_0" 10 "PVC" 9 "IMU" 8 "TMS" 7 "TMU" 1 "MC" 0 "All" ;
VAL_ 0 CS 130 "Reset Communication" 129 "Reset Node" 128 "Enter Pre-Operational" 2 "Stop" 1 "Start" ;
VAL_ 2021 LSS_TableIndex 8 "10" 7 "20" 6 "50" 5 "100" 4 "125" 3 "250" 2 "500" 1 "800" 0 "1000" ;
VAL_ 2021 LSS_TableSelector 0 "Std_CiA_Table" ;
VAL_ 2021 LSS_Mode 1 "Configuration" 0 "Operation" ;
VAL_ 2021 LSS_M_CS 94 "InquireNodeID" 93 "InquireSerial" 92 "InquireRevision" 91 "InquireProduct" 90 "InquireVendor" 81 "FastScan" 23 "StoreConfiguration" 21 "ActivateBitTiming" 19 "ConfigureBitTiming" 17 "ConfigureNodeID" 76 "IdentifyNonConfSlave" 75 "IdentifySerialHigh" 74 "IdentifySerialLow" 73 "IdentifyRevisionHigh" 72 "IdentifyRevisionLow" 71 "IdentifyProduct" 70 "IdentifyVendor" 67 "SwitchModeSelectSerial" 66 "SwitchModeSelectRevision" 65 "SwitchModeSelectProduct" 64 "SwitchModeSelectVendor" 4 "SwitchModeGlobal" ;
VAL_ 2020 LSS_StoreCfg_ErrCode 255 "Impl_spec_error" 2 "Storage_media_access_error" 1 "Not_supported" 0 "Success" ;
VAL_ 2020 LSS_CfgBitTim_ErrCode 255 "Impl_spec_error" 1 "Not_supported" 0 "Success" ;
VAL_ 2020 LSS_CfgNodeID_ErrCode 255 "Impl_spec_error" 1 "NodeID_Out_Of_Range" 0 "Success" ;
VAL_ 2020 LSS_S_CS 94 "InquireNodeID" 93 "InquireSerial" 92 "InquireRevision" 91 "InquireProduct" 90 "InquireVendor" 76 "IdentifyNonConfSlave" 79 "IdentifySlave" 23 "StoreConfiguration" 19 "ConfigureBitTiming" 17 "ConfigureNodeID" 68 "SwitchModeSelectConfirm" ;
